AUTOSAR XML (schema 4-3-0)
package /CAN1/ISignalGroup
  31 x i signal group:
    CAN1_SG_ABM1: i-signal=[CAN1_AirBagFailCmd, CAN1_Checksum_ABM1, CAN1_CrashOutputSts, CAN1_DriverSeatBeltCmd, CAN1_LifeCount_ABM1, CAN1_PABSwitchCmd, CAN1_PsngrSeatBeltCmd, CAN1_RCenterSeatBeltCmd, CAN1_RDriverSeatBeltCmd, CAN1_RPsngrSeatBeltCmd, CAN1_TLHPsngrSeatBeltCmd, CAN1_TRHPsngrSeatBeltCmd], system-signal-group=CAN1_SG_ABM1
    CAN1_SG_EPAS1: i-signal=[CAN1_DriIntend, CAN1_EPAS1_Checksum, CAN1_EPAS1_LifeCount, CAN1_EPS_AOI_Control, CAN1_EPS_TOI_Fault], system-signal-group=CAN1_SG_EPAS1
    CAN1_SG_EPAS2: i-signal=[CAN1_SAS_Angle, CAN1_SAS_CAL, CAN1_SAS_CheckSum, CAN1_SAS_MsgCount, CAN1_SAS_Speed, CAN1_SAS_Speed_Valid, CAN1_SAS_V], system-signal-group=CAN1_SG_EPAS2
    CAN1_SG_EPB1: i-signal=[CAN1_DOA_Sta, CAN1_EPB1_CS, CAN1_EPB1_RC, CAN1_EPBCarWashMode, CAN1_EPBErrSta, CAN1_EPBExtApplyAvail, CAN1_EPBExtReleaseAvail, CAN1_EPBMsg, CAN1_EPBRLampSta, CAN1_EPBSta, CAN1_EPBStaL, CAN1_EPBStaR, CAN1_TakeOverReq], system-signal-group=CAN1_SG_EPB1
    CAN1_SG_ESC1: i-signal=[CAN1_ESC1_CS, CAN1_ESC1_RC, CAN1_Fr_PTCS_Active, CAN1_FrntAxlTrqReq_Drv, CAN1_RearAxlTrqReq_Drv, CAN1_Rr_PTCS_Active, CAN1_VehSpeed], system-signal-group=CAN1_SG_ESC1
    CAN1_SG_ESC2: i-signal=[CAN1_F_WhlSpeed_CRC_8, CAN1_F_WhlSpeed_Count, CAN1_LF_PulseCount, CAN1_LF_PulseCount_V, CAN1_LF_RawWhlSpeed, CAN1_LF_RawWhlSpeed_V, CAN1_LF_WhlRotDir, CAN1_RF_PulseCount, CAN1_RF_PulseCount_V, CAN1_RF_RawWhlSpeed, CAN1_RF_RawWhlSpeed_V, CAN1_RF_WhlRotDir], system-signal-group=CAN1_SG_ESC2
    CAN1_SG_ESC3: i-signal=[CAN1_LR_PulseCount, CAN1_LR_PulseCount_V, CAN1_LR_RawWhlSpeed, CAN1_LR_RawWhlSpeed_V, CAN1_LR_WhlRotDir, CAN1_RR_PulseCount, CAN1_RR_PulseCount_V, CAN1_RR_RawWhlSpeed, CAN1_RR_RawWhlSpeed_V, CAN1_RR_WhlRotDir, CAN1_R_WhlSpeed_CRC_8, CAN1_R_WhlSpeed_Count], system-signal-group=CAN1_SG_ESC3
    CAN1_SG_ESC4: i-signal=[CAN1_ABS_Active, CAN1_ABS_Failed, CAN1_ABS_WnlmpSta, CAN1_AVH_Active, CAN1_AVH_Failed, CAN1_Amber_WnlmpSta, CAN1_BTCS_Active, CAN1_EBD_Active, CAN1_EBD_Failed, CAN1_ESC_Active, CAN1_ESC_BeepReq, CAN1_ESC_Failed, CAN1_ESC_OFF_Status, CAN1_ESC_Off_lmpSta, CAN1_ESC_WnlmpSta, CAN1_ESS_Active, CAN1_GRADE, CAN1_HBB_Active, CAN1_HBB_Failed, CAN1_HDD_Active, CAN1_HDD_Failed, CAN1_HSA_Active, CAN1_HSA_Failed, CAN1_PBA_Active, CAN1_PBA_Failed, CAN1_Red_WnlmpSta, CAN1_SystemVoltage, CAN1_TCS_Active, CAN1_TCS_Failed], system-signal-group=CAN1_SG_ESC4
    CAN1_SG_ESC5: i-signal=[CAN1_BrkSw_Sta, CAN1_BrkSw_V, CAN1_ESC5_CRC8, CAN1_ESC5_RC, CAN1_LatAccel, CAN1_LatAccel_V, CAN1_LongAccel, CAN1_LongAccel_V, CAN1_MCPressure, CAN1_MCPressure_V, CAN1_YawRate, CAN1_YawRate_V], system-signal-group=CAN1_SG_ESC5
    CAN1_SG_ESC6: i-signal=[CAN1_ACCAvail, CAN1_AEBAvail, CAN1_ActBrkLamp_Sta, CAN1_BrkDiscTempSta, CAN1_DecErrSta, CAN1_ESC6_CS, CAN1_ESC6_RC, CAN1_ESC_ADAS_Sta, CAN1_ESC_APS_Sta, CAN1_ESC_Standstill, CAN1_Meter_Ind_VehSpeed], system-signal-group=CAN1_SG_ESC6
    CAN1_SG_ESC7: i-signal=[CAN1_BrkPedalPos, CAN1_BrkPedalPos_Sta, CAN1_ESC7_CS, CAN1_ESC7_RC, CAN1_Fr_RBC_Active, CAN1_FrntAxlTrqReq_Brk, CAN1_RDC_Active, CAN1_RearAxlTrqReq_Brk, CAN1_Rr_RBC_Active], system-signal-group=CAN1_SG_ESC7
    CAN1_SG_FCM2: i-signal=[CAN1_ACC_ComfortBandLower, CAN1_ACC_ComfortBandUpper, CAN1_ACC_JerkLowerLimit, CAN1_ACC_JerkUpperLimit, CAN1_ACC_RequiredAccel, CAN1_ACC_VehHoldReq, CAN1_ADAS_AEBReq, CAN1_ADAS_DBSReq, CAN1_ADAS_FaultSta, CAN1_AEB_VehHoldReq, CAN1_FCM2_Checksum, CAN1_FCM2_LifeCount], system-signal-group=CAN1_SG_FCM2
    CAN1_SG_FCM3: i-signal=[CAN1_ACC_ObjDist, CAN1_ACC_ObjRelSpd, CAN1_ADAS_ForceIdle, CAN1_ADAS_ShftPosnReq, CAN1_ADAS_ShftPosnReq_A, CAN1_ADAS_VehSpdLim, CAN1_FCM3_Checksum, CAN1_FCM3_LifeCount], system-signal-group=CAN1_SG_FCM3
    CAN1_SG_FCM4: i-signal=[CAN1_ACCSetSpeed, CAN1_ACCSetSpeed_Disp, CAN1_ACC_ObjDstLvl, CAN1_ACC_TakeoverReq, CAN1_ADAS_ACC_Sta, CAN1_ADAS_AEB_Sta, CAN1_ADAS_CAM_SpdLim, CAN1_ADAS_FCW_Sta, CAN1_ADAS_FltWrnReq, CAN1_ADAS_LDW_Sta, CAN1_ADAS_SLIF_SpdLim, CAN1_ADAS_WarningMsg, CAN1_FCM4_Checksum, CAN1_ForceLowBeam, CAN1_HazardWarningReq, CAN1_LeftTurnLightReq, CAN1_RightTurnLightReq, CAN1_Target_Type, CAN1_TimeGapLevel], system-signal-group=CAN1_SG_FCM4
    CAN1_SG_FD_APS1: i-signal=[CAN1_APS_Angle_Target, CAN1_APS_Rq_EPAS_Ctrl, CAN1_APS_Sta_System, CAN1_APS_V_Rq_EPAS_Ctrl], system-signal-group=CAN1_SG_FD_APS1
    CAN1_SG_FD_APS2: i-signal=[CAN1_APS_D_FLL, CAN1_APS_D_FLR, CAN1_APS_D_RLL, CAN1_APS_D_RLR, CAN1_APS_ExitCondition, CAN1_APS_HW_Ver, CAN1_APS_Progress_PCT, CAN1_APS_RQ_Display, CAN1_APS_SW_Ver, CAN1_PAS_A_FCL, CAN1_PAS_A_FCR, CAN1_PAS_A_FML, CAN1_PAS_A_FMR, CAN1_PAS_A_RCL, CAN1_PAS_A_RCR, CAN1_PAS_A_RML, CAN1_PAS_A_RMR, CAN1_PAS_Chime, CAN1_PAS_D_FCL, CAN1_PAS_D_FCR, CAN1_PAS_D_FML, CAN1_PAS_D_FMR, CAN1_PAS_D_RCL, CAN1_PAS_D_RCR, CAN1_PAS_D_RML, CAN1_PAS_D_RMR, CAN1_PAS_Mod_Operation, CAN1_PAS_SNSR_Layout, CAN1_PAS_Sta_F_Sys, CAN1_USS_Sta_FCL, CAN1_USS_Sta_FCR, CAN1_USS_Sta_FLL, CAN1_USS_Sta_FLR, CAN1_USS_Sta_FML, CAN1_USS_Sta_FMR, CAN1_USS_Sta_RCL, CAN1_USS_Sta_RCR, CAN1_USS_Sta_RLL, CAN1_USS_Sta_RLR, CAN1_USS_Sta_RML, CAN1_USS_Sta_RMR], system-signal-group=CAN1_SG_FD_APS2
    CAN1_SG_FD_APS3: i-signal=[CAN1_APS3_LifeCount, CAN1_APS3_checksum, CAN1_APSOpenPTG, CAN1_APS_DecReq, CAN1_APS_DecReq_A, CAN1_APS_Req, CAN1_CAAS_Sta, CAN1_SPTGDet, CAN1_SPTG_Sta], system-signal-group=CAN1_SG_FD_APS3
    CAN1_SG_FD_BCM1: i-signal=[CAN1_AllDoorSW, CAN1_AntiTheftSeatFold, CAN1_AntitheftSta, CAN1_BCM_Buzzer_Req, CAN1_BCM_DoorLock_Sta, CAN1_BrakeLamp, CAN1_CTDCtrl, CAN1_CTDLockSW, CAN1_CTDUnlockSW, CAN1_CrashDetd, CAN1_Dimmer, CAN1_DimmerEN, CAN1_DoorLockIND, CAN1_DrDoorSW, CAN1_Fr_ChargingDoorCtrl, CAN1_Fr_FogLamp, CAN1_Fr_Wiper_H, CAN1_Fr_Wiper_L, CAN1_H_Beam, CAN1_HazardSW, CAN1_HoodSW, CAN1_HornCtrl, CAN1_LBSD, CAN1_LDRL, CAN1_LTurnLP, CAN1_L_APM_WdwEnable, CAN1_L_Beam, CAN1_LockSetting, CAN1_MirrorCtrl, CAN1_MirrorDefog, CAN1_PosLamp, CAN1_PsDoorSW, CAN1_RBSD, CAN1_RDRL, CAN1_RLDoorSW, CAN1_RRDoorSW, CAN1_RTurnLP, CAN1_ReverseLamp, CAN1_RoomLampH, CAN1_RoomLampL, CAN1_Rr_ChargingDoorCtrl, CAN1_Rr_Defog, CAN1_Rr_FogLamp, CAN1_Rr_Wiper, CAN1_TailgateHDSW, CAN1_TailgateRemote, CAN1_Tailgate_SW, CAN1_TrunkRel, CAN1_WasherCtrl, CAN1_WiperFixMode], system-signal-group=CAN1_SG_FD_BCM1
    CAN1_SG_FD_THCM1: i-signal=[CAN1_BatteryMode, CAN1_CCU_ACLampSts, CAN1_CCU_ACMaxLampSts, CAN1_CCU_AutoLampSts, CAN1_CCU_AutoMidLampSts, CAN1_CCU_Dispaly_Request, CAN1_CCU_EcoSts, CAN1_CCU_FrtOnOffLampSts, CAN1_CCU_HEATMaxLampSts, CAN1_CCU_RrOnOffLampSts, CAN1_CCU_SyncLampSts, CAN1_CabinMode, CAN1_EDriveMode, CAN1_FD_AGS_Cmd, CAN1_FD_RecyAuto_Cmd, CAN1_Fr_Coolantflow, CAN1_Fr_Coolanttemp, CAN1_HPThermalRecoveryReq, CAN1_Rr_Coolantflow, CAN1_Rr_Coolanttemp, CAN1_sigAirIntenZon1St, CAN1_sigAirIntenZon3St, CAN1_sigAmbAirT, CAN1_sigCbnAirT, CAN1_sigCbnPTCPwrAct, CAN1_sigCbnSolarLeft, CAN1_sigCbnSolarRight, CAN1_sigClmtCmprPwrAct, CAN1_sigClntTHvBattOut, CAN1_sigDfrstSt, CAN1_sigHvacSt, CAN1_sigRecircSt, CAN1_sigSetTempZon1St, CAN1_sigSetTempZon2St, CAN1_sigSetTempZon3St, CAN1_sigWindDirZon1St, CAN1_sigWindDirZon3St], system-signal-group=CAN1_SG_FD_THCM1
    CAN1_SG_FD_VCU1: i-signal=[CAN1_CC_Crl_Sta, CAN1_HVPwrSta, CAN1_LVPwrSta, CAN1_MSA_Crl_Sta, CAN1_P_Button_Sta, CAN1_PrkReq, CAN1_PrkReqValid, CAN1_PwrSta, CAN1_ShiftGearPosn, CAN1_XWDMode], system-signal-group=CAN1_SG_FD_VCU1
    CAN1_SG_FD_VCU2: i-signal=[CAN1_ACC_CtrlAvail, CAN1_AccPedal_Override, CAN1_ActAPSPosn, CAN1_CS_VCU2_CAN1, CAN1_DriverTq, CAN1_Fr_DriverTq, CAN1_RC_VCU2_CAN1, CAN1_Rr_DriverTq, CAN1_VehActPwr], system-signal-group=CAN1_SG_FD_VCU2
    CAN1_SG_FD_VCU3: i-signal=[CAN1_CS_VCU3_CAN1, CAN1_EquivAccPedalSWSta, CAN1_Fr_EDUAvailBrkRgnTq, CAN1_Fr_EDUAvailBrkRgnTqValid, CAN1_Fr_EDURealARgnTq, CAN1_Fr_EDURealDrvOrBRgnTq, CAN1_Fr_EDUSpd, CAN1_Fr_EDUSpdValid, CAN1_Fr_RgnDecrSta, CAN1_Fr_RgnPermSta, CAN1_PTCS_PermSta, CAN1_RC_VCU3_CAN1, CAN1_RgnAbnorSta, CAN1_Rr_EDUAvailBrkRgnTq, CAN1_Rr_EDUAvailBrkRgnTqValid, CAN1_Rr_EDURealARgnTq, CAN1_Rr_EDURealDrvOrBRgnTq, CAN1_Rr_EDUSpd, CAN1_Rr_EDUSpdValid, CAN1_Rr_RgnDecrSta, CAN1_Rr_RgnPermSta], system-signal-group=CAN1_SG_FD_VCU3
    CAN1_SG_FD_VCU4: i-signal=[CAN1_Eng_AGSCloseSta, CAN1_Eng_ActvDmpDisabSta, CAN1_Eng_CoastDwSta, CAN1_Eng_PwrLockSta, CAN1_VehMalfunLevel], system-signal-group=CAN1_SG_FD_VCU4
    CAN1_SG_SRR1: i-signal=[CAN1_SRR1_Chksum, CAN1_SRR1_LifeCount, CAN1_SRR_BSD_Mute, CAN1_SRR_BSD_SoundL, CAN1_SRR_BSD_SoundR, CAN1_SRR_BSD_Sta, CAN1_SRR_BSD_WarnL, CAN1_SRR_BSD_WarnR, CAN1_SRR_FltWrnReq, CAN1_SRR_ODA_Mute, CAN1_SRR_ODA_SoundL, CAN1_SRR_ODA_SoundR, CAN1_SRR_ODA_Sta, CAN1_SRR_ODA_WarnL, CAN1_SRR_ODA_WarnR, CAN1_SRR_RCTA_Sta, CAN1_SRR_RCTA_WarnL, CAN1_SRR_RCTA_WarnR], system-signal-group=CAN1_SG_SRR1
    CAN1_SG_XNMm_ABM: i-signal=[CAN1_NM_ABM_Active_WU, CAN1_NM_ABM_CSB, CAN1_NM_ABM_ERROR_State, CAN1_NM_ABM_Node_ID, CAN1_NM_ABM_PNI, CAN1_NM_ABM_Rpt_Msg_Req], system-signal-group=CAN1_SG_XNMm_ABM
    CAN1_SG_XNMm_EPAS: i-signal=[CAN1_NM_EPAS_Active_WU, CAN1_NM_EPAS_CSB, CAN1_NM_EPAS_ERROR_State, CAN1_NM_EPAS_Node_ID, CAN1_NM_EPAS_PNI, CAN1_NM_EPAS_Rpt_Msg_Req], system-signal-group=CAN1_SG_XNMm_EPAS
    CAN1_SG_XNMm_ESC: i-signal=[CAN1_NM_ESC_Active_WU, CAN1_NM_ESC_CSB, CAN1_NM_ESC_ERROR_State, CAN1_NM_ESC_Node_ID, CAN1_NM_ESC_PNI, CAN1_NM_ESC_Rpt_Msg_Req], system-signal-group=CAN1_SG_XNMm_ESC
    CAN1_SG_XNMm_FCM: i-signal=[CAN1_NM_FCM_Active_WU, CAN1_NM_FCM_CSB, CAN1_NM_FCM_ERROR_State, CAN1_NM_FCM_Node_ID, CAN1_NM_FCM_PNI, CAN1_NM_FCM_Rpt_Msg_Req], system-signal-group=CAN1_SG_XNMm_FCM
    CAN1_SG_XNMm_FUSION: i-signal=[CAN1_NM_FUSION_Active_WU, CAN1_NM_FUSION_CSB, CAN1_NM_FUSION_ERROR_State, CAN1_NM_FUSION_Node_ID, CAN1_NM_FUSION_PNI, CAN1_NM_FUSION_Rpt_Msg_Req], system-signal-group=CAN1_SG_XNMm_FUSION
    CAN1_SG_XNMm_SRR_M: i-signal=[CAN1_NM_SRR_M_Active_WU, CAN1_NM_SRR_M_CSB, CAN1_NM_SRR_M_ERROR_State, CAN1_NM_SRR_M_Node_ID, CAN1_NM_SRR_M_PNI, CAN1_NM_SRR_M_Rpt_Msg_Req], system-signal-group=CAN1_SG_XNMm_SRR_M
    CAN1_SG_XNMm_eBST: i-signal=[CAN1_NM_eBST_Active_WU, CAN1_NM_eBST_CSB, CAN1_NM_eBST_ERROR_State, CAN1_NM_eBST_Node_ID, CAN1_NM_eBST_PNI, CAN1_NM_eBST_Rpt_Msg_Req], system-signal-group=CAN1_SG_XNMm_eBST
package /CAN1/Cluster
  can cluster CAN1: baudrate=500, can-fd-baudrate=2000
    can physical channel CAN1: comm-connectors=ConnCAN1
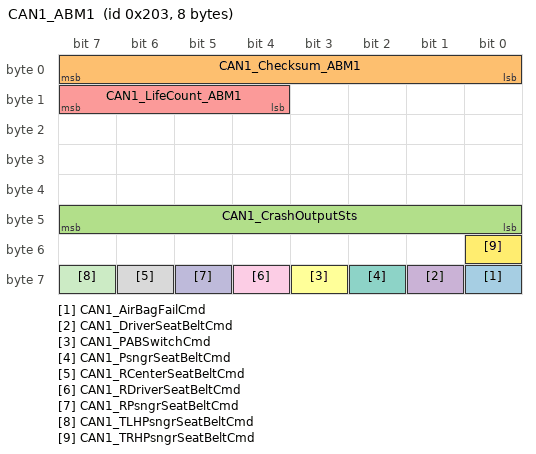
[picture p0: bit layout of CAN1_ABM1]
      frame CAN1_ABM1: id 0x203, frame-length=8, can-addressing-mode=STANDARD, can-fd-frame-support=true, can-frame-rx-behavior=CAN-FD, can-frame-tx-behavior=CAN-FD
        pdu CAN1_ABM1: length=8, minimum-delay=0.0, transmission-mode-true-timing={cyclic-timing=time-period=0.5, event-controlled-timing={number-of-repetitions=0, repetition-period=0.05}}, unused-bit-pattern=0
          mapping CAN1_SG_ABM1: i-signal-group=CAN1_SG_ABM1, start-position=0, transfer-property=TRIGGERED-ON-CHANGE
          signal CAN1_AirBagFailCmd: start 56, 1 bit, big-endian, i-signal-type=PRIMITIVE, init-value=constant-reference=Init_CAN1_AirBagFailCmd, base-type=uint8, implementation-data-type=uint8, transfer-property=TRIGGERED-ON-CHANGE
          signal CAN1_Checksum_ABM1: start 7, 8 bit, big-endian, i-signal-type=PRIMITIVE, init-value=constant-reference=Init_CAN1_Checksum_ABM1, base-type=uint8, implementation-data-type=uint8, transfer-property=TRIGGERED-ON-CHANGE
          signal CAN1_CrashOutputSts: start 47, 8 bit, big-endian, i-signal-type=PRIMITIVE, init-value=constant-reference=Init_CAN1_CrashOutputSts, base-type=uint8, implementation-data-type=uint8, transfer-property=TRIGGERED-ON-CHANGE
          signal CAN1_DriverSeatBeltCmd: start 57, 1 bit, big-endian, i-signal-type=PRIMITIVE, init-value=constant-reference=Init_CAN1_DriverSeatBeltCmd, base-type=uint8, implementation-data-type=uint8, transfer-property=TRIGGERED-ON-CHANGE
          signal CAN1_LifeCount_ABM1: start 15, 4 bit, big-endian, i-signal-type=PRIMITIVE, init-value=constant-reference=Init_CAN1_LifeCount_ABM1, base-type=uint8, implementation-data-type=uint8, transfer-property=TRIGGERED-ON-CHANGE
          signal CAN1_PABSwitchCmd: start 59, 1 bit, big-endian, i-signal-type=PRIMITIVE, init-value=constant-reference=Init_CAN1_PABSwitchCmd, base-type=uint8, implementation-data-type=uint8, transfer-property=TRIGGERED-ON-CHANGE
          signal CAN1_PsngrSeatBeltCmd: start 58, 1 bit, big-endian, i-signal-type=PRIMITIVE, init-value=constant-reference=Init_CAN1_PsngrSeatBeltCmd, base-type=uint8, implementation-data-type=uint8, transfer-property=TRIGGERED-ON-CHANGE
          signal CAN1_RCenterSeatBeltCmd: start 62, 1 bit, big-endian, i-signal-type=PRIMITIVE, init-value=constant-reference=Init_CAN1_RCenterSeatBeltCmd, base-type=uint8, implementation-data-type=uint8, transfer-property=TRIGGERED-ON-CHANGE
          signal CAN1_RDriverSeatBeltCmd: start 60, 1 bit, big-endian, i-signal-type=PRIMITIVE, init-value=constant-reference=Init_CAN1_RDriverSeatBeltCmd, base-type=uint8, implementation-data-type=uint8, transfer-property=TRIGGERED-ON-CHANGE
          signal CAN1_RPsngrSeatBeltCmd: start 61, 1 bit, big-endian, i-signal-type=PRIMITIVE, init-value=constant-reference=Init_CAN1_RPsngrSeatBeltCmd, base-type=uint8, implementation-data-type=uint8, transfer-property=TRIGGERED-ON-CHANGE
          signal CAN1_TLHPsngrSeatBeltCmd: start 63, 1 bit, big-endian, i-signal-type=PRIMITIVE, init-value=constant-reference=Init_CAN1_TLHPsngrSeatBeltCmd, base-type=uint8, implementation-data-type=uint8, transfer-property=TRIGGERED-ON-CHANGE
          signal CAN1_TRHPsngrSeatBeltCmd: start 48, 1 bit, big-endian, i-signal-type=PRIMITIVE, init-value=constant-reference=Init_CAN1_TRHPsngrSeatBeltCmd, base-type=uint8, implementation-data-type=uint8, transfer-property=TRIGGERED-ON-CHANGE
      frame CAN1_DiagFuncReqFT: id 0x7D0, frame-length=8, can-addressing-mode=STANDARD, can-fd-frame-support=false, can-frame-rx-behavior=CAN-20, can-frame-tx-behavior=CAN-20
        n pdu CAN1_DiagFuncReqFT: length=8
      frame CAN1_DiagPhysReqToABM: id 0x6B1, frame-length=8, can-addressing-mode=STANDARD, can-fd-frame-support=true, can-frame-rx-behavior=CAN-FD, can-frame-tx-behavior=CAN-FD
        n pdu CAN1_DiagPhysReqToABM: length=8
      frame CAN1_DiagPhysReqToEPAS: id 0x6A1, frame-length=8, can-addressing-mode=STANDARD, can-fd-frame-support=true, can-frame-rx-behavior=CAN-FD, can-frame-tx-behavior=CAN-FD
        n pdu CAN1_DiagPhysReqToEPAS: length=8
      frame CAN1_DiagPhysReqToESC: id 0x681, frame-length=8, can-addressing-mode=STANDARD, can-fd-frame-support=false, can-frame-rx-behavior=CAN-20, can-frame-tx-behavior=CAN-20
        n pdu CAN1_DiagPhysReqToESC: length=8
      frame CAN1_DiagPhysReqToFCM: id 0x690, frame-length=8, can-addressing-mode=STANDARD, can-fd-frame-support=true, can-frame-rx-behavior=CAN-FD, can-frame-tx-behavior=CAN-FD
        n pdu CAN1_DiagPhysReqToFCM: length=8
      frame CAN1_DiagPhysReqToMRR: id 0x695, frame-length=8, can-addressing-mode=STANDARD, can-fd-frame-support=false, can-frame-rx-behavior=CAN-20, can-frame-tx-behavior=CAN-20
        n pdu CAN1_DiagPhysReqToMRR: length=8
      frame CAN1_DiagPhysReqToSRR_M: id 0x692, frame-length=8, can-addressing-mode=STANDARD, can-fd-frame-support=true, can-frame-rx-behavior=CAN-FD, can-frame-tx-behavior=CAN-FD
        n pdu CAN1_DiagPhysReqToSRR_M: length=8
      frame CAN1_DiagPhysReqToeBST: id 0x691, frame-length=8, can-addressing-mode=STANDARD, can-fd-frame-support=false, can-frame-rx-behavior=CAN-20, can-frame-tx-behavior=CAN-20
        n pdu CAN1_DiagPhysReqToeBST: length=8
      frame CAN1_DiagRespFromABM: id 0x631, frame-length=8, can-addressing-mode=STANDARD, can-fd-frame-support=true, can-frame-rx-behavior=CAN-FD, can-frame-tx-behavior=CAN-FD
        n pdu CAN1_DiagRespFromABM: length=8
      frame CAN1_DiagRespFromEPAS: id 0x621, frame-length=8, can-addressing-mode=STANDARD, can-fd-frame-support=true, can-frame-rx-behavior=CAN-FD, can-frame-tx-behavior=CAN-FD
        n pdu CAN1_DiagRespFromEPAS: length=8
      frame CAN1_DiagRespFromESC: id 0x601, frame-length=8, can-addressing-mode=STANDARD, can-fd-frame-support=false, can-frame-rx-behavior=CAN-20, can-frame-tx-behavior=CAN-20
        n pdu CAN1_DiagRespFromESC: length=8
      frame CAN1_DiagRespFromFCM: id 0x610, frame-length=8, can-addressing-mode=STANDARD, can-fd-frame-support=true, can-frame-rx-behavior=CAN-FD, can-frame-tx-behavior=CAN-FD
        n pdu CAN1_DiagRespFromFCM: length=8
      frame CAN1_DiagRespFromMRR: id 0x615, frame-length=8, can-addressing-mode=STANDARD, can-fd-frame-support=false, can-frame-rx-behavior=CAN-20, can-frame-tx-behavior=CAN-20
        n pdu CAN1_DiagRespFromMRR: length=8
      frame CAN1_DiagRespFromSRR_M: id 0x612, frame-length=8, can-addressing-mode=STANDARD, can-fd-frame-support=true, can-frame-rx-behavior=CAN-FD, can-frame-tx-behavior=CAN-FD
        n pdu CAN1_DiagRespFromSRR_M: length=8
      frame CAN1_DiagRespFromeBST: id 0x611, frame-length=8, can-addressing-mode=STANDARD, can-fd-frame-support=false, can-frame-rx-behavior=CAN-20, can-frame-tx-behavior=CAN-20
        n pdu CAN1_DiagRespFromeBST: length=8
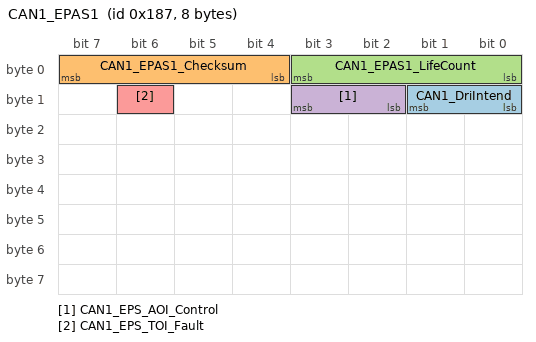
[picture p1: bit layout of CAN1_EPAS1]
      frame CAN1_EPAS1: id 0x187, frame-length=8, can-addressing-mode=STANDARD, can-fd-frame-support=true, can-frame-rx-behavior=CAN-FD, can-frame-tx-behavior=CAN-FD
        pdu CAN1_EPAS1: length=8, minimum-delay=0.0, transmission-mode-true-timing=cyclic-timing=time-period=0.02, unused-bit-pattern=0
          mapping CAN1_SG_EPAS1: i-signal-group=CAN1_SG_EPAS1, start-position=0, transfer-property=PENDING
          signal CAN1_DriIntend: start 9, 2 bit, big-endian, i-signal-type=PRIMITIVE, init-value=constant-reference=Init_CAN1_DriIntend, base-type=uint8, implementation-data-type=uint8, transfer-property=PENDING
          signal CAN1_EPAS1_Checksum: start 7, 4 bit, big-endian, i-signal-type=PRIMITIVE, init-value=constant-reference=Init_CAN1_EPAS1_Checksum, base-type=uint8, implementation-data-type=uint8, transfer-property=PENDING
          signal CAN1_EPAS1_LifeCount: start 3, 4 bit, big-endian, i-signal-type=PRIMITIVE, init-value=constant-reference=Init_CAN1_EPAS1_LifeCount, base-type=uint8, implementation-data-type=uint8, transfer-property=PENDING
          signal CAN1_EPS_AOI_Control: start 11, 2 bit, big-endian, i-signal-type=PRIMITIVE, init-value=constant-reference=Init_CAN1_EPS_AOI_Control, base-type=uint8, implementation-data-type=uint8, transfer-property=PENDING
          signal CAN1_EPS_TOI_Fault: start 14, 1 bit, big-endian, i-signal-type=PRIMITIVE, init-value=constant-reference=Init_CAN1_EPS_TOI_Fault, base-type=uint8, implementation-data-type=uint8, transfer-property=PENDING
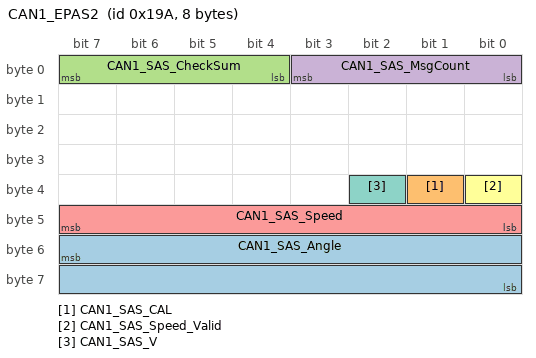
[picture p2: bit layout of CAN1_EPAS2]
      frame CAN1_EPAS2: id 0x19A, frame-length=8, can-addressing-mode=STANDARD, can-fd-frame-support=true, can-frame-rx-behavior=CAN-FD, can-frame-tx-behavior=CAN-FD
        pdu CAN1_EPAS2: length=8, minimum-delay=0.0, transmission-mode-true-timing=cyclic-timing=time-period=0.01, unused-bit-pattern=0
          mapping CAN1_SG_EPAS2: i-signal-group=CAN1_SG_EPAS2, start-position=0, transfer-property=PENDING
          signal CAN1_SAS_Angle: start 55, 16 bit, big-endian, i-signal-type=PRIMITIVE, init-value=constant-reference=Init_CAN1_SAS_Angle, base-type=uint16, implementation-data-type=uint16, transfer-property=PENDING
          signal CAN1_SAS_CAL: start 33, 1 bit, big-endian, i-signal-type=PRIMITIVE, init-value=constant-reference=Init_CAN1_SAS_CAL, base-type=uint8, implementation-data-type=uint8, transfer-property=PENDING
          signal CAN1_SAS_CheckSum: start 7, 4 bit, big-endian, i-signal-type=PRIMITIVE, init-value=constant-reference=Init_CAN1_SAS_CheckSum, base-type=uint8, implementation-data-type=uint8, transfer-property=PENDING
          signal CAN1_SAS_MsgCount: start 3, 4 bit, big-endian, i-signal-type=PRIMITIVE, init-value=constant-reference=Init_CAN1_SAS_MsgCount, base-type=uint8, implementation-data-type=uint8, transfer-property=PENDING
          signal CAN1_SAS_Speed: start 47, 8 bit, big-endian, i-signal-type=PRIMITIVE, init-value=constant-reference=Init_CAN1_SAS_Speed, base-type=uint8, implementation-data-type=uint8, transfer-property=PENDING
          signal CAN1_SAS_Speed_Valid: start 32, 1 bit, big-endian, i-signal-type=PRIMITIVE, init-value=constant-reference=Init_CAN1_SAS_Speed_Valid, base-type=uint8, implementation-data-type=uint8, transfer-property=PENDING
          signal CAN1_SAS_V: start 34, 1 bit, big-endian, i-signal-type=PRIMITIVE, init-value=constant-reference=Init_CAN1_SAS_V, base-type=uint8, implementation-data-type=uint8, transfer-property=PENDING
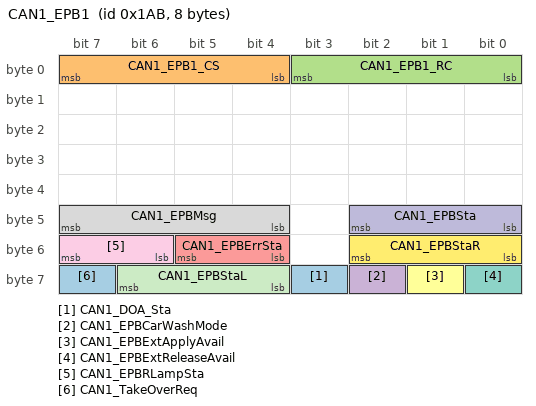
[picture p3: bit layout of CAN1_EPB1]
      frame CAN1_EPB1: id 0x1AB, frame-length=8, can-addressing-mode=STANDARD, can-fd-frame-support=true, can-frame-rx-behavior=CAN-FD, can-frame-tx-behavior=CAN-FD
        pdu CAN1_EPB1: length=8, minimum-delay=0.0, transmission-mode-true-timing=cyclic-timing=time-period=0.04, unused-bit-pattern=0
          mapping CAN1_SG_EPB1: i-signal-group=CAN1_SG_EPB1, start-position=0, transfer-property=PENDING
          signal CAN1_DOA_Sta: start 59, 1 bit, big-endian, i-signal-type=PRIMITIVE, init-value=constant-reference=Init_CAN1_DOA_Sta, base-type=uint8, implementation-data-type=uint8, transfer-property=PENDING
          signal CAN1_EPB1_CS: start 7, 4 bit, big-endian, i-signal-type=PRIMITIVE, init-value=constant-reference=Init_CAN1_EPB1_CS, base-type=uint8, implementation-data-type=uint8, transfer-property=PENDING
          signal CAN1_EPB1_RC: start 3, 4 bit, big-endian, i-signal-type=PRIMITIVE, init-value=constant-reference=Init_CAN1_EPB1_RC, base-type=uint8, implementation-data-type=uint8, transfer-property=PENDING
          signal CAN1_EPBCarWashMode: start 58, 1 bit, big-endian, i-signal-type=PRIMITIVE, init-value=constant-reference=Init_CAN1_EPBCarWashMode, base-type=uint8, implementation-data-type=uint8, transfer-property=PENDING
          signal CAN1_EPBErrSta: start 53, 2 bit, big-endian, i-signal-type=PRIMITIVE, init-value=constant-reference=Init_CAN1_EPBErrSta, base-type=uint8, implementation-data-type=uint8, transfer-property=PENDING
          signal CAN1_EPBExtApplyAvail: start 57, 1 bit, big-endian, i-signal-type=PRIMITIVE, init-value=constant-reference=Init_CAN1_EPBExtApplyAvail, base-type=uint8, implementation-data-type=uint8, transfer-property=PENDING
          signal CAN1_EPBExtReleaseAvail: start 56, 1 bit, big-endian, i-signal-type=PRIMITIVE, init-value=constant-reference=Init_CAN1_EPBExtReleaseAvail, base-type=uint8, implementation-data-type=uint8, transfer-property=PENDING
          signal CAN1_EPBMsg: start 47, 4 bit, big-endian, i-signal-type=PRIMITIVE, init-value=constant-reference=Init_CAN1_EPBMsg, base-type=uint8, implementation-data-type=uint8, transfer-property=PENDING
          signal CAN1_EPBRLampSta: start 55, 2 bit, big-endian, i-signal-type=PRIMITIVE, init-value=constant-reference=Init_CAN1_EPBRLampSta, base-type=uint8, implementation-data-type=uint8, transfer-property=PENDING
          signal CAN1_EPBSta: start 42, 3 bit, big-endian, i-signal-type=PRIMITIVE, init-value=constant-reference=Init_CAN1_EPBSta, base-type=uint8, implementation-data-type=uint8, transfer-property=PENDING
          signal CAN1_EPBStaL: start 62, 3 bit, big-endian, i-signal-type=PRIMITIVE, init-value=constant-reference=Init_CAN1_EPBStaL, base-type=uint8, implementation-data-type=uint8, transfer-property=PENDING
          signal CAN1_EPBStaR: start 50, 3 bit, big-endian, i-signal-type=PRIMITIVE, init-value=constant-reference=Init_CAN1_EPBStaR, base-type=uint8, implementation-data-type=uint8, transfer-property=PENDING
          signal CAN1_TakeOverReq: start 63, 1 bit, big-endian, i-signal-type=PRIMITIVE, init-value=constant-reference=Init_CAN1_TakeOverReq, base-type=uint8, implementation-data-type=uint8, transfer-property=PENDING
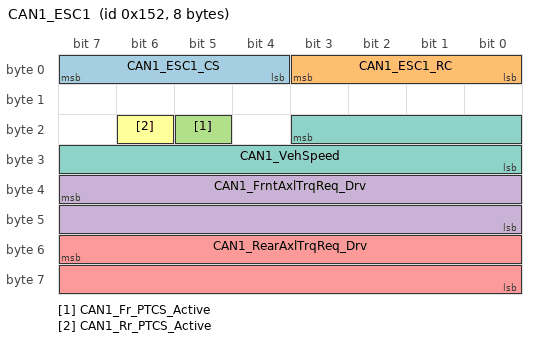
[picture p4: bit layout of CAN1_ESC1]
      frame CAN1_ESC1: id 0x152, frame-length=8, can-addressing-mode=STANDARD, can-fd-frame-support=true, can-frame-rx-behavior=CAN-FD, can-frame-tx-behavior=CAN-FD
        pdu CAN1_ESC1: length=8, minimum-delay=0.0, transmission-mode-true-timing=cyclic-timing=time-period=0.01, unused-bit-pattern=0
          mapping CAN1_SG_ESC1: i-signal-group=CAN1_SG_ESC1, start-position=0, transfer-property=PENDING
          signal CAN1_ESC1_CS: start 7, 4 bit, big-endian, i-signal-type=PRIMITIVE, init-value=constant-reference=Init_CAN1_ESC1_CS, base-type=uint8, implementation-data-type=uint8, transfer-property=PENDING
          signal CAN1_ESC1_RC: start 3, 4 bit, big-endian, i-signal-type=PRIMITIVE, init-value=constant-reference=Init_CAN1_ESC1_RC, base-type=uint8, implementation-data-type=uint8, transfer-property=PENDING
          signal CAN1_Fr_PTCS_Active: start 21, 1 bit, big-endian, i-signal-type=PRIMITIVE, init-value=constant-reference=Init_CAN1_Fr_PTCS_Active, base-type=uint8, implementation-data-type=uint8, transfer-property=PENDING
          signal CAN1_FrntAxlTrqReq_Drv: start 39, 16 bit, big-endian, i-signal-type=PRIMITIVE, init-value=constant-reference=Init_CAN1_FrntAxlTrqReq_Drv, base-type=uint16, implementation-data-type=uint16, transfer-property=PENDING
          signal CAN1_RearAxlTrqReq_Drv: start 55, 16 bit, big-endian, i-signal-type=PRIMITIVE, init-value=constant-reference=Init_CAN1_RearAxlTrqReq_Drv, base-type=uint16, implementation-data-type=uint16, transfer-property=PENDING
          signal CAN1_Rr_PTCS_Active: start 22, 1 bit, big-endian, i-signal-type=PRIMITIVE, init-value=constant-reference=Init_CAN1_Rr_PTCS_Active, base-type=uint8, implementation-data-type=uint8, transfer-property=PENDING
          signal CAN1_VehSpeed: start 19, 12 bit, big-endian, i-signal-type=PRIMITIVE, init-value=constant-reference=Init_CAN1_VehSpeed, base-type=uint16, implementation-data-type=uint16, transfer-property=PENDING
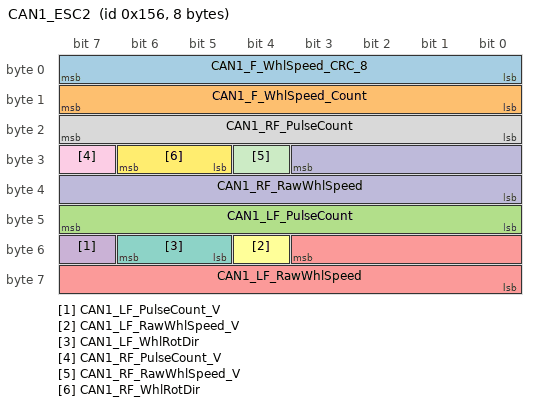
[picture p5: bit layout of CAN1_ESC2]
      frame CAN1_ESC2: id 0x156, frame-length=8, can-addressing-mode=STANDARD, can-fd-frame-support=true, can-frame-rx-behavior=CAN-FD, can-frame-tx-behavior=CAN-FD
        pdu CAN1_ESC2: length=8, minimum-delay=0.0, transmission-mode-true-timing=cyclic-timing=time-period=0.01, unused-bit-pattern=0
          mapping CAN1_SG_ESC2: i-signal-group=CAN1_SG_ESC2, start-position=0, transfer-property=PENDING
          signal CAN1_F_WhlSpeed_CRC_8: start 7, 8 bit, big-endian, i-signal-type=PRIMITIVE, init-value=constant-reference=Init_CAN1_F_WhlSpeed_CRC_8, base-type=uint8, implementation-data-type=uint8, transfer-property=PENDING
          signal CAN1_F_WhlSpeed_Count: start 15, 8 bit, big-endian, i-signal-type=PRIMITIVE, init-value=constant-reference=Init_CAN1_F_WhlSpeed_Count, base-type=uint8, implementation-data-type=uint8, transfer-property=PENDING
          signal CAN1_LF_PulseCount: start 47, 8 bit, big-endian, i-signal-type=PRIMITIVE, init-value=constant-reference=Init_CAN1_LF_PulseCount, base-type=uint8, implementation-data-type=uint8, transfer-property=PENDING
          signal CAN1_LF_PulseCount_V: start 55, 1 bit, big-endian, i-signal-type=PRIMITIVE, init-value=constant-reference=Init_CAN1_LF_PulseCount_V, base-type=uint8, implementation-data-type=uint8, transfer-property=PENDING
          signal CAN1_LF_RawWhlSpeed: start 51, 12 bit, big-endian, i-signal-type=PRIMITIVE, init-value=constant-reference=Init_CAN1_LF_RawWhlSpeed, base-type=uint16, implementation-data-type=uint16, transfer-property=PENDING
          signal CAN1_LF_RawWhlSpeed_V: start 52, 1 bit, big-endian, i-signal-type=PRIMITIVE, init-value=constant-reference=Init_CAN1_LF_RawWhlSpeed_V, base-type=uint8, implementation-data-type=uint8, transfer-property=PENDING
          signal CAN1_LF_WhlRotDir: start 54, 2 bit, big-endian, i-signal-type=PRIMITIVE, init-value=constant-reference=Init_CAN1_LF_WhlRotDir, base-type=uint8, implementation-data-type=uint8, transfer-property=PENDING
          signal CAN1_RF_PulseCount: start 23, 8 bit, big-endian, i-signal-type=PRIMITIVE, init-value=constant-reference=Init_CAN1_RF_PulseCount, base-type=uint8, implementation-data-type=uint8, transfer-property=PENDING
          signal CAN1_RF_PulseCount_V: start 31, 1 bit, big-endian, i-signal-type=PRIMITIVE, init-value=constant-reference=Init_CAN1_RF_PulseCount_V, base-type=uint8, implementation-data-type=uint8, transfer-property=PENDING
          signal CAN1_RF_RawWhlSpeed: start 27, 12 bit, big-endian, i-signal-type=PRIMITIVE, init-value=constant-reference=Init_CAN1_RF_RawWhlSpeed, base-type=uint16, implementation-data-type=uint16, transfer-property=PENDING
          signal CAN1_RF_RawWhlSpeed_V: start 28, 1 bit, big-endian, i-signal-type=PRIMITIVE, init-value=constant-reference=Init_CAN1_RF_RawWhlSpeed_V, base-type=uint8, implementation-data-type=uint8, transfer-property=PENDING
          signal CAN1_RF_WhlRotDir: start 30, 2 bit, big-endian, i-signal-type=PRIMITIVE, init-value=constant-reference=Init_CAN1_RF_WhlRotDir, base-type=uint8, implementation-data-type=uint8, transfer-property=PENDING
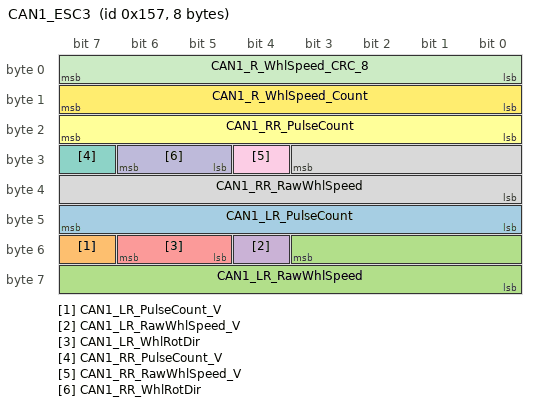
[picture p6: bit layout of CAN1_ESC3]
      frame CAN1_ESC3: id 0x157, frame-length=8, can-addressing-mode=STANDARD, can-fd-frame-support=true, can-frame-rx-behavior=CAN-FD, can-frame-tx-behavior=CAN-FD
        pdu CAN1_ESC3: length=8, minimum-delay=0.0, transmission-mode-true-timing=cyclic-timing=time-period=0.01, unused-bit-pattern=0
          mapping CAN1_SG_ESC3: i-signal-group=CAN1_SG_ESC3, start-position=0, transfer-property=PENDING
          signal CAN1_LR_PulseCount: start 47, 8 bit, big-endian, i-signal-type=PRIMITIVE, init-value=constant-reference=Init_CAN1_LR_PulseCount, base-type=uint8, implementation-data-type=uint8, transfer-property=PENDING
          signal CAN1_LR_PulseCount_V: start 55, 1 bit, big-endian, i-signal-type=PRIMITIVE, init-value=constant-reference=Init_CAN1_LR_PulseCount_V, base-type=uint8, implementation-data-type=uint8, transfer-property=PENDING
          signal CAN1_LR_RawWhlSpeed: start 51, 12 bit, big-endian, i-signal-type=PRIMITIVE, init-value=constant-reference=Init_CAN1_LR_RawWhlSpeed, base-type=uint16, implementation-data-type=uint16, transfer-property=PENDING
          signal CAN1_LR_RawWhlSpeed_V: start 52, 1 bit, big-endian, i-signal-type=PRIMITIVE, init-value=constant-reference=Init_CAN1_LR_RawWhlSpeed_V, base-type=uint8, implementation-data-type=uint8, transfer-property=PENDING
          signal CAN1_LR_WhlRotDir: start 54, 2 bit, big-endian, i-signal-type=PRIMITIVE, init-value=constant-reference=Init_CAN1_LR_WhlRotDir, base-type=uint8, implementation-data-type=uint8, transfer-property=PENDING
          signal CAN1_RR_PulseCount: start 23, 8 bit, big-endian, i-signal-type=PRIMITIVE, init-value=constant-reference=Init_CAN1_RR_PulseCount, base-type=uint8, implementation-data-type=uint8, transfer-property=PENDING
          signal CAN1_RR_PulseCount_V: start 31, 1 bit, big-endian, i-signal-type=PRIMITIVE, init-value=constant-reference=Init_CAN1_RR_PulseCount_V, base-type=uint8, implementation-data-type=uint8, transfer-property=PENDING
          signal CAN1_RR_RawWhlSpeed: start 27, 12 bit, big-endian, i-signal-type=PRIMITIVE, init-value=constant-reference=Init_CAN1_RR_RawWhlSpeed, base-type=uint16, implementation-data-type=uint16, transfer-property=PENDING
          signal CAN1_RR_RawWhlSpeed_V: start 28, 1 bit, big-endian, i-signal-type=PRIMITIVE, init-value=constant-reference=Init_CAN1_RR_RawWhlSpeed_V, base-type=uint8, implementation-data-type=uint8, transfer-property=PENDING
          signal CAN1_RR_WhlRotDir: start 30, 2 bit, big-endian, i-signal-type=PRIMITIVE, init-value=constant-reference=Init_CAN1_RR_WhlRotDir, base-type=uint8, implementation-data-type=uint8, transfer-property=PENDING
          signal CAN1_R_WhlSpeed_CRC_8: start 7, 8 bit, big-endian, i-signal-type=PRIMITIVE, init-value=constant-reference=Init_CAN1_R_WhlSpeed_CRC_8, base-type=uint8, implementation-data-type=uint8, transfer-property=PENDING
          signal CAN1_R_WhlSpeed_Count: start 15, 8 bit, big-endian, i-signal-type=PRIMITIVE, init-value=constant-reference=Init_CAN1_R_WhlSpeed_Count, base-type=uint8, implementation-data-type=uint8, transfer-property=PENDING
      frame CAN1_ESC4: id 0x1A3, frame-length=8, can-addressing-mode=STANDARD, can-fd-frame-support=true, can-frame-rx-behavior=CAN-FD, can-frame-tx-behavior=CAN-FD
        pdu CAN1_ESC4: length=8, minimum-delay=0.0, transmission-mode-true-timing=cyclic-timing=time-period=0.01, unused-bit-pattern=0
          mapping CAN1_SG_ESC4: i-signal-group=CAN1_SG_ESC4, start-position=0, transfer-property=PENDING
          signal CAN1_ABS_Active: start 45, 1 bit, big-endian, i-signal-type=PRIMITIVE, init-value=constant-reference=Init_CAN1_ABS_Active, base-type=uint8, implementation-data-type=uint8, transfer-property=PENDING
          signal CAN1_ABS_Failed: start 25, 1 bit, big-endian, i-signal-type=PRIMITIVE, init-value=constant-reference=Init_CAN1_ABS_Failed, base-type=uint8, implementation-data-type=uint8, transfer-property=PENDING
          signal CAN1_ABS_WnlmpSta: start 60, 1 bit, big-endian, i-signal-type=PRIMITIVE, init-value=constant-reference=Init_CAN1_ABS_WnlmpSta, base-type=uint8, implementation-data-type=uint8, transfer-property=PENDING
          signal CAN1_AVH_Active: start 35, 1 bit, big-endian, i-signal-type=PRIMITIVE, init-value=constant-reference=Init_CAN1_AVH_Active, base-type=uint8, implementation-data-type=uint8, transfer-property=PENDING
          signal CAN1_AVH_Failed: start 31, 1 bit, big-endian, i-signal-type=PRIMITIVE, init-value=constant-reference=Init_CAN1_AVH_Failed, base-type=uint8, implementation-data-type=uint8, transfer-property=PENDING
          signal CAN1_Amber_WnlmpSta: start 36, 1 bit, big-endian, i-signal-type=PRIMITIVE, init-value=constant-reference=Init_CAN1_Amber_WnlmpSta, base-type=uint8, implementation-data-type=uint8, transfer-property=PENDING
          signal CAN1_BTCS_Active: start 37, 1 bit, big-endian, i-signal-type=PRIMITIVE, init-value=constant-reference=Init_CAN1_BTCS_Active, base-type=uint8, implementation-data-type=uint8, transfer-property=PENDING
          signal CAN1_EBD_Active: start 44, 1 bit, big-endian, i-signal-type=PRIMITIVE, init-value=constant-reference=Init_CAN1_EBD_Active, base-type=uint8, implementation-data-type=uint8, transfer-property=PENDING
          signal CAN1_EBD_Failed: start 24, 1 bit, big-endian, i-signal-type=PRIMITIVE, init-value=constant-reference=Init_CAN1_EBD_Failed, base-type=uint8, implementation-data-type=uint8, transfer-property=PENDING
          signal CAN1_ESC_Active: start 47, 1 bit, big-endian, i-signal-type=PRIMITIVE, init-value=constant-reference=Init_CAN1_ESC_Active, base-type=uint8, implementation-data-type=uint8, transfer-property=PENDING
          signal CAN1_ESC_BeepReq: start 15, 1 bit, big-endian, i-signal-type=PRIMITIVE, init-value=constant-reference=Init_CAN1_ESC_BeepReq, base-type=uint8, implementation-data-type=uint8, transfer-property=PENDING
          signal CAN1_ESC_Failed: start 27, 1 bit, big-endian, i-signal-type=PRIMITIVE, init-value=constant-reference=Init_CAN1_ESC_Failed, base-type=uint8, implementation-data-type=uint8, transfer-property=PENDING
          signal CAN1_ESC_OFF_Status: start 18, 2 bit, big-endian, i-signal-type=PRIMITIVE, init-value=constant-reference=Init_CAN1_ESC_OFF_Status, base-type=uint8, implementation-data-type=uint8, transfer-property=PENDING
          signal CAN1_ESC_Off_lmpSta: start 61, 1 bit, big-endian, i-signal-type=PRIMITIVE, init-value=constant-reference=Init_CAN1_ESC_Off_lmpSta, base-type=uint8, implementation-data-type=uint8, transfer-property=PENDING
          signal CAN1_ESC_WnlmpSta: start 63, 2 bit, big-endian, i-signal-type=PRIMITIVE, init-value=constant-reference=Init_CAN1_ESC_WnlmpSta, base-type=uint8, implementation-data-type=uint8, transfer-property=PENDING
          signal CAN1_ESS_Active: start 38, 1 bit, big-endian, i-signal-type=PRIMITIVE, init-value=constant-reference=Init_CAN1_ESS_Active, base-type=uint8, implementation-data-type=uint8, transfer-property=PENDING
          signal CAN1_GRADE: start 55, 8 bit, big-endian, i-signal-type=PRIMITIVE, init-value=constant-reference=Init_CAN1_GRADE, base-type=uint8, implementation-data-type=uint8, transfer-property=PENDING
          signal CAN1_HBB_Active: start 32, 1 bit, big-endian, i-signal-type=PRIMITIVE, init-value=constant-reference=Init_CAN1_HBB_Active, base-type=uint8, implementation-data-type=uint8, transfer-property=PENDING
          signal CAN1_HBB_Failed: start 28, 1 bit, big-endian, i-signal-type=PRIMITIVE, init-value=constant-reference=Init_CAN1_HBB_Failed, base-type=uint8, implementation-data-type=uint8, transfer-property=PENDING
          signal CAN1_HDD_Active: start 39, 1 bit, big-endian, i-signal-type=PRIMITIVE, init-value=constant-reference=Init_CAN1_HDD_Active, base-type=uint8, implementation-data-type=uint8, transfer-property=PENDING
          signal CAN1_HDD_Failed: start 16, 1 bit, big-endian, i-signal-type=PRIMITIVE, init-value=constant-reference=Init_CAN1_HDD_Failed, base-type=uint8, implementation-data-type=uint8, transfer-property=PENDING
          signal CAN1_HSA_Active: start 34, 1 bit, big-endian, i-signal-type=PRIMITIVE, init-value=constant-reference=Init_CAN1_HSA_Active, base-type=uint8, implementation-data-type=uint8, transfer-property=PENDING
          signal CAN1_HSA_Failed: start 30, 1 bit, big-endian, i-signal-type=PRIMITIVE, init-value=constant-reference=Init_CAN1_HSA_Failed, base-type=uint8, implementation-data-type=uint8, transfer-property=PENDING
          signal CAN1_PBA_Active: start 33, 1 bit, big-endian, i-signal-type=PRIMITIVE, init-value=constant-reference=Init_CAN1_PBA_Active, base-type=uint8, implementation-data-type=uint8, transfer-property=PENDING
          signal CAN1_PBA_Failed: start 29, 1 bit, big-endian, i-signal-type=PRIMITIVE, init-value=constant-reference=Init_CAN1_PBA_Failed, base-type=uint8, implementation-data-type=uint8, transfer-property=PENDING
          signal CAN1_Red_WnlmpSta: start 59, 1 bit, big-endian, i-signal-type=PRIMITIVE, init-value=constant-reference=Init_CAN1_Red_WnlmpSta, base-type=uint8, implementation-data-type=uint8, transfer-property=PENDING
          signal CAN1_SystemVoltage: start 7, 8 bit, big-endian, i-signal-type=PRIMITIVE, init-value=constant-reference=Init_CAN1_SystemVoltage, base-type=uint8, implementation-data-type=uint8, transfer-property=PENDING
          signal CAN1_TCS_Active: start 46, 1 bit, big-endian, i-signal-type=PRIMITIVE, init-value=constant-reference=Init_CAN1_TCS_Active, base-type=uint8, implementation-data-type=uint8, transfer-property=PENDING
          signal CAN1_TCS_Failed: start 26, 1 bit, big-endian, i-signal-type=PRIMITIVE, init-value=constant-reference=Init_CAN1_TCS_Failed, base-type=uint8, implementation-data-type=uint8, transfer-property=PENDING
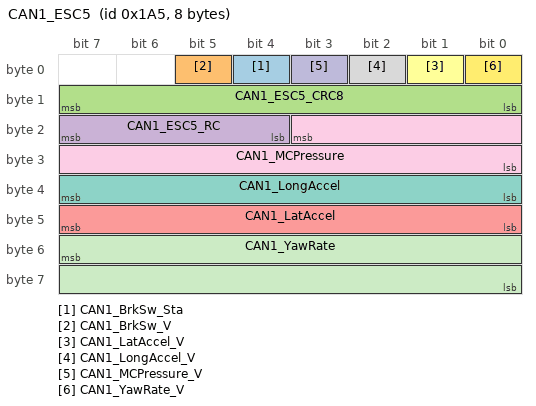
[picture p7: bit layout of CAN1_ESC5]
      frame CAN1_ESC5: id 0x1A5, frame-length=8, can-addressing-mode=STANDARD, can-fd-frame-support=true, can-frame-rx-behavior=CAN-FD, can-frame-tx-behavior=CAN-FD
        pdu CAN1_ESC5: length=8, minimum-delay=0.0, transmission-mode-true-timing=cyclic-timing=time-period=0.01, unused-bit-pattern=0
          mapping CAN1_SG_ESC5: i-signal-group=CAN1_SG_ESC5, start-position=0, transfer-property=PENDING
          signal CAN1_BrkSw_Sta: start 4, 1 bit, big-endian, i-signal-type=PRIMITIVE, init-value=constant-reference=Init_CAN1_BrkSw_Sta, base-type=uint8, implementation-data-type=uint8, transfer-property=PENDING
          signal CAN1_BrkSw_V: start 5, 1 bit, big-endian, i-signal-type=PRIMITIVE, init-value=constant-reference=Init_CAN1_BrkSw_V, base-type=uint8, implementation-data-type=uint8, transfer-property=PENDING
          signal CAN1_ESC5_CRC8: start 15, 8 bit, big-endian, i-signal-type=PRIMITIVE, init-value=constant-reference=Init_CAN1_ESC5_CRC8, base-type=uint8, implementation-data-type=uint8, transfer-property=PENDING
          signal CAN1_ESC5_RC: start 23, 4 bit, big-endian, i-signal-type=PRIMITIVE, init-value=constant-reference=Init_CAN1_ESC5_RC, base-type=uint8, implementation-data-type=uint8, transfer-property=PENDING
          signal CAN1_LatAccel: start 47, 8 bit, big-endian, i-signal-type=PRIMITIVE, init-value=constant-reference=Init_CAN1_LatAccel, base-type=uint8, implementation-data-type=uint8, transfer-property=PENDING
          signal CAN1_LatAccel_V: start 1, 1 bit, big-endian, i-signal-type=PRIMITIVE, init-value=constant-reference=Init_CAN1_LatAccel_V, base-type=uint8, implementation-data-type=uint8, transfer-property=PENDING
          signal CAN1_LongAccel: start 39, 8 bit, big-endian, i-signal-type=PRIMITIVE, init-value=constant-reference=Init_CAN1_LongAccel, base-type=uint8, implementation-data-type=uint8, transfer-property=PENDING
          signal CAN1_LongAccel_V: start 2, 1 bit, big-endian, i-signal-type=PRIMITIVE, init-value=constant-reference=Init_CAN1_LongAccel_V, base-type=uint8, implementation-data-type=uint8, transfer-property=PENDING
          signal CAN1_MCPressure: start 19, 12 bit, big-endian, i-signal-type=PRIMITIVE, init-value=constant-reference=Init_CAN1_MCPressure, base-type=uint16, implementation-data-type=uint16, transfer-property=PENDING
          signal CAN1_MCPressure_V: start 3, 1 bit, big-endian, i-signal-type=PRIMITIVE, init-value=constant-reference=Init_CAN1_MCPressure_V, base-type=uint8, implementation-data-type=uint8, transfer-property=PENDING
          signal CAN1_YawRate: start 55, 16 bit, big-endian, i-signal-type=PRIMITIVE, init-value=constant-reference=Init_CAN1_YawRate, base-type=uint16, implementation-data-type=uint16, transfer-property=PENDING
          signal CAN1_YawRate_V: start 0, 1 bit, big-endian, i-signal-type=PRIMITIVE, init-value=constant-reference=Init_CAN1_YawRate_V, base-type=uint8, implementation-data-type=uint8, transfer-property=PENDING
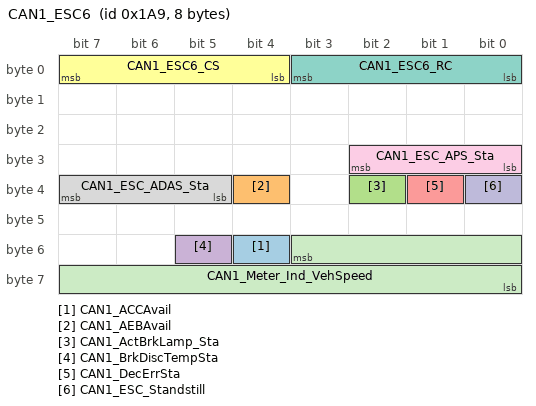
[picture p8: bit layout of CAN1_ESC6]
      frame CAN1_ESC6: id 0x1A9, frame-length=8, can-addressing-mode=STANDARD, can-fd-frame-support=true, can-frame-rx-behavior=CAN-FD, can-frame-tx-behavior=CAN-FD
        pdu CAN1_ESC6: length=8, minimum-delay=0.0, transmission-mode-true-timing=cyclic-timing=time-period=0.01, unused-bit-pattern=0
          mapping CAN1_SG_ESC6: i-signal-group=CAN1_SG_ESC6, start-position=0, transfer-property=PENDING
          signal CAN1_ACCAvail: start 52, 1 bit, big-endian, i-signal-type=PRIMITIVE, init-value=constant-reference=Init_CAN1_ACCAvail, base-type=uint8, implementation-data-type=uint8, transfer-property=PENDING
          signal CAN1_AEBAvail: start 36, 1 bit, big-endian, i-signal-type=PRIMITIVE, init-value=constant-reference=Init_CAN1_AEBAvail, base-type=uint8, implementation-data-type=uint8, transfer-property=PENDING
          signal CAN1_ActBrkLamp_Sta: start 34, 1 bit, big-endian, i-signal-type=PRIMITIVE, init-value=constant-reference=Init_CAN1_ActBrkLamp_Sta, base-type=uint8, implementation-data-type=uint8, transfer-property=PENDING
          signal CAN1_BrkDiscTempSta: start 53, 1 bit, big-endian, i-signal-type=PRIMITIVE, init-value=constant-reference=Init_CAN1_BrkDiscTempSta, base-type=uint8, implementation-data-type=uint8, transfer-property=PENDING
          signal CAN1_DecErrSta: start 33, 1 bit, big-endian, i-signal-type=PRIMITIVE, init-value=constant-reference=Init_CAN1_DecErrSta, base-type=uint8, implementation-data-type=uint8, transfer-property=PENDING
          signal CAN1_ESC6_CS: start 7, 4 bit, big-endian, i-signal-type=PRIMITIVE, init-value=constant-reference=Init_CAN1_ESC6_CS, base-type=uint8, implementation-data-type=uint8, transfer-property=PENDING
          signal CAN1_ESC6_RC: start 3, 4 bit, big-endian, i-signal-type=PRIMITIVE, init-value=constant-reference=Init_CAN1_ESC6_RC, base-type=uint8, implementation-data-type=uint8, transfer-property=PENDING
          signal CAN1_ESC_ADAS_Sta: start 39, 3 bit, big-endian, i-signal-type=PRIMITIVE, init-value=constant-reference=Init_CAN1_ESC_ADAS_Sta, base-type=uint8, implementation-data-type=uint8, transfer-property=PENDING
          signal CAN1_ESC_APS_Sta: start 26, 3 bit, big-endian, i-signal-type=PRIMITIVE, init-value=constant-reference=Init_CAN1_ESC_APS_Sta, base-type=uint8, implementation-data-type=uint8, transfer-property=PENDING
          signal CAN1_ESC_Standstill: start 32, 1 bit, big-endian, i-signal-type=PRIMITIVE, init-value=constant-reference=Init_CAN1_ESC_Standstill, base-type=uint8, implementation-data-type=uint8, transfer-property=PENDING
          signal CAN1_Meter_Ind_VehSpeed: start 51, 12 bit, big-endian, i-signal-type=PRIMITIVE, init-value=constant-reference=Init_CAN1_Meter_Ind_VehSpeed, base-type=uint16, implementation-data-type=uint16, transfer-property=PENDING
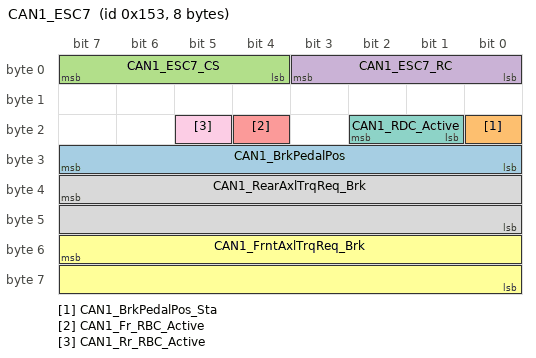
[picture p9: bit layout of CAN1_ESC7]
      frame CAN1_ESC7: id 0x153, frame-length=8, can-addressing-mode=STANDARD, can-fd-frame-support=true, can-frame-rx-behavior=CAN-FD, can-frame-tx-behavior=CAN-FD
        pdu CAN1_ESC7: length=8, minimum-delay=0.0, transmission-mode-true-timing=cyclic-timing=time-period=0.01, unused-bit-pattern=0
          mapping CAN1_SG_ESC7: i-signal-group=CAN1_SG_ESC7, start-position=0, transfer-property=PENDING
          signal CAN1_BrkPedalPos: start 31, 8 bit, big-endian, i-signal-type=PRIMITIVE, init-value=constant-reference=Init_CAN1_BrkPedalPos, base-type=uint8, implementation-data-type=uint8, transfer-property=PENDING
          signal CAN1_BrkPedalPos_Sta: start 16, 1 bit, big-endian, i-signal-type=PRIMITIVE, init-value=constant-reference=Init_CAN1_BrkPedalPos_Sta, base-type=uint8, implementation-data-type=uint8, transfer-property=PENDING
          signal CAN1_ESC7_CS: start 7, 4 bit, big-endian, i-signal-type=PRIMITIVE, init-value=constant-reference=Init_CAN1_ESC7_CS, base-type=uint8, implementation-data-type=uint8, transfer-property=PENDING
          signal CAN1_ESC7_RC: start 3, 4 bit, big-endian, i-signal-type=PRIMITIVE, init-value=constant-reference=Init_CAN1_ESC7_RC, base-type=uint8, implementation-data-type=uint8, transfer-property=PENDING
          signal CAN1_Fr_RBC_Active: start 20, 1 bit, big-endian, i-signal-type=PRIMITIVE, init-value=constant-reference=Init_CAN1_Fr_RBC_Active, base-type=uint8, implementation-data-type=uint8, transfer-property=PENDING
          signal CAN1_FrntAxlTrqReq_Brk: start 55, 16 bit, big-endian, i-signal-type=PRIMITIVE, init-value=constant-reference=Init_CAN1_FrntAxlTrqReq_Brk, base-type=uint16, implementation-data-type=uint16, transfer-property=PENDING
          signal CAN1_RDC_Active: start 18, 2 bit, big-endian, i-signal-type=PRIMITIVE, init-value=constant-reference=Init_CAN1_RDC_Active, base-type=uint8, implementation-data-type=uint8, transfer-property=PENDING
          signal CAN1_RearAxlTrqReq_Brk: start 39, 16 bit, big-endian, i-signal-type=PRIMITIVE, init-value=constant-reference=Init_CAN1_RearAxlTrqReq_Brk, base-type=uint16, implementation-data-type=uint16, transfer-property=PENDING
          signal CAN1_Rr_RBC_Active: start 21, 1 bit, big-endian, i-signal-type=PRIMITIVE, init-value=constant-reference=Init_CAN1_Rr_RBC_Active, base-type=uint8, implementation-data-type=uint8, transfer-property=PENDING
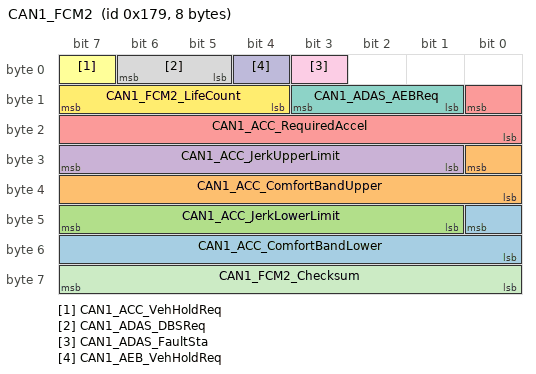
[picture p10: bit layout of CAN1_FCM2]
      frame CAN1_FCM2: id 0x179, frame-length=8, can-addressing-mode=STANDARD, can-fd-frame-support=true, can-frame-rx-behavior=CAN-FD, can-frame-tx-behavior=CAN-FD
        pdu CAN1_FCM2: length=8, minimum-delay=0.0, transmission-mode-true-timing=cyclic-timing=time-period=0.01, unused-bit-pattern=0
          mapping CAN1_SG_FCM2: i-signal-group=CAN1_SG_FCM2, start-position=0, transfer-property=PENDING
          signal CAN1_ACC_ComfortBandLower: start 40, 9 bit, big-endian, i-signal-type=PRIMITIVE, init-value=constant-reference=Init_CAN1_ACC_ComfortBandLower, base-type=uint16, implementation-data-type=uint16, transfer-property=PENDING
          signal CAN1_ACC_ComfortBandUpper: start 24, 9 bit, big-endian, i-signal-type=PRIMITIVE, init-value=constant-reference=Init_CAN1_ACC_ComfortBandUpper, base-type=uint16, implementation-data-type=uint16, transfer-property=PENDING
          signal CAN1_ACC_JerkLowerLimit: start 47, 7 bit, big-endian, i-signal-type=PRIMITIVE, init-value=constant-reference=Init_CAN1_ACC_JerkLowerLimit, base-type=uint8, implementation-data-type=uint8, transfer-property=PENDING
          signal CAN1_ACC_JerkUpperLimit: start 31, 7 bit, big-endian, i-signal-type=PRIMITIVE, init-value=constant-reference=Init_CAN1_ACC_JerkUpperLimit, base-type=uint8, implementation-data-type=uint8, transfer-property=PENDING
          signal CAN1_ACC_RequiredAccel: start 8, 9 bit, big-endian, i-signal-type=PRIMITIVE, init-value=constant-reference=Init_CAN1_ACC_RequiredAccel, base-type=uint16, implementation-data-type=uint16, transfer-property=PENDING
          signal CAN1_ACC_VehHoldReq: start 7, 1 bit, big-endian, i-signal-type=PRIMITIVE, init-value=constant-reference=Init_CAN1_ACC_VehHoldReq, base-type=uint8, implementation-data-type=uint8, transfer-property=PENDING
          signal CAN1_ADAS_AEBReq: start 11, 3 bit, big-endian, i-signal-type=PRIMITIVE, init-value=constant-reference=Init_CAN1_ADAS_AEBReq, base-type=uint8, implementation-data-type=uint8, transfer-property=PENDING
          signal CAN1_ADAS_DBSReq: start 6, 2 bit, big-endian, i-signal-type=PRIMITIVE, init-value=constant-reference=Init_CAN1_ADAS_DBSReq, base-type=uint8, implementation-data-type=uint8, transfer-property=PENDING
          signal CAN1_ADAS_FaultSta: start 3, 1 bit, big-endian, i-signal-type=PRIMITIVE, init-value=constant-reference=Init_CAN1_ADAS_FaultSta, base-type=uint8, implementation-data-type=uint8, transfer-property=PENDING
          signal CAN1_AEB_VehHoldReq: start 4, 1 bit, big-endian, i-signal-type=PRIMITIVE, init-value=constant-reference=Init_CAN1_AEB_VehHoldReq, base-type=uint8, implementation-data-type=uint8, transfer-property=PENDING
          signal CAN1_FCM2_Checksum: start 63, 8 bit, big-endian, i-signal-type=PRIMITIVE, init-value=constant-reference=Init_CAN1_FCM2_Checksum, base-type=uint8, implementation-data-type=uint8, transfer-property=PENDING
          signal CAN1_FCM2_LifeCount: start 15, 4 bit, big-endian, i-signal-type=PRIMITIVE, init-value=constant-reference=Init_CAN1_FCM2_LifeCount, base-type=uint8, implementation-data-type=uint8, transfer-property=PENDING
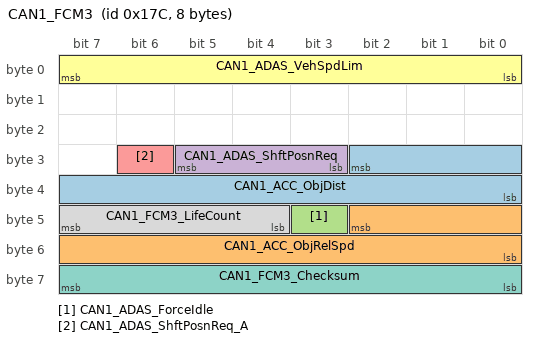
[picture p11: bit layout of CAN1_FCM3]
      frame CAN1_FCM3: id 0x17C, frame-length=8, can-addressing-mode=STANDARD, can-fd-frame-support=true, can-frame-rx-behavior=CAN-FD, can-frame-tx-behavior=CAN-FD
        pdu CAN1_FCM3: length=8, minimum-delay=0.0, transmission-mode-true-timing=cyclic-timing=time-period=0.01, unused-bit-pattern=0
          mapping CAN1_SG_FCM3: i-signal-group=CAN1_SG_FCM3, start-position=0, transfer-property=PENDING
          signal CAN1_ACC_ObjDist: start 26, 11 bit, big-endian, i-signal-type=PRIMITIVE, init-value=constant-reference=Init_CAN1_ACC_ObjDist, base-type=uint16, implementation-data-type=uint16, transfer-property=PENDING
          signal CAN1_ACC_ObjRelSpd: start 42, 11 bit, big-endian, i-signal-type=PRIMITIVE, init-value=constant-reference=Init_CAN1_ACC_ObjRelSpd, base-type=uint16, implementation-data-type=uint16, transfer-property=PENDING
          signal CAN1_ADAS_ForceIdle: start 43, 1 bit, big-endian, i-signal-type=PRIMITIVE, init-value=constant-reference=Init_CAN1_ADAS_ForceIdle, base-type=uint8, implementation-data-type=uint8, transfer-property=PENDING
          signal CAN1_ADAS_ShftPosnReq: start 29, 3 bit, big-endian, i-signal-type=PRIMITIVE, init-value=constant-reference=Init_CAN1_ADAS_ShftPosnReq, base-type=uint8, implementation-data-type=uint8, transfer-property=PENDING
          signal CAN1_ADAS_ShftPosnReq_A: start 30, 1 bit, big-endian, i-signal-type=PRIMITIVE, init-value=constant-reference=Init_CAN1_ADAS_ShftPosnReq_A, base-type=uint8, implementation-data-type=uint8, transfer-property=PENDING
          signal CAN1_ADAS_VehSpdLim: start 7, 8 bit, big-endian, i-signal-type=PRIMITIVE, init-value=constant-reference=Init_CAN1_ADAS_VehSpdLim, base-type=uint8, implementation-data-type=uint8, transfer-property=PENDING
          signal CAN1_FCM3_Checksum: start 63, 8 bit, big-endian, i-signal-type=PRIMITIVE, init-value=constant-reference=Init_CAN1_FCM3_Checksum, base-type=uint8, implementation-data-type=uint8, transfer-property=PENDING
          signal CAN1_FCM3_LifeCount: start 47, 4 bit, big-endian, i-signal-type=PRIMITIVE, init-value=constant-reference=Init_CAN1_FCM3_LifeCount, base-type=uint8, implementation-data-type=uint8, transfer-property=PENDING
      frame CAN1_FCM4: id 0x23A, frame-length=8, can-addressing-mode=STANDARD, can-fd-frame-support=true, can-frame-rx-behavior=CAN-FD, can-frame-tx-behavior=CAN-FD
        pdu CAN1_FCM4: length=8, minimum-delay=0.0, transmission-mode-true-timing=cyclic-timing=time-period=0.1, unused-bit-pattern=0
          mapping CAN1_SG_FCM4: i-signal-group=CAN1_SG_FCM4, start-position=0, transfer-property=PENDING
          signal CAN1_ACCSetSpeed: start 31, 8 bit, big-endian, i-signal-type=PRIMITIVE, init-value=constant-reference=Init_CAN1_ACCSetSpeed, base-type=uint8, implementation-data-type=uint8, transfer-property=PENDING
          signal CAN1_ACCSetSpeed_Disp: start 39, 3 bit, big-endian, i-signal-type=PRIMITIVE, init-value=constant-reference=Init_CAN1_ACCSetSpeed_Disp, base-type=uint8, implementation-data-type=uint8, transfer-property=PENDING
          signal CAN1_ACC_ObjDstLvl: start 23, 3 bit, big-endian, i-signal-type=PRIMITIVE, init-value=constant-reference=Init_CAN1_ACC_ObjDstLvl, base-type=uint8, implementation-data-type=uint8, transfer-property=PENDING
          signal CAN1_ACC_TakeoverReq: start 36, 1 bit, big-endian, i-signal-type=PRIMITIVE, init-value=constant-reference=Init_CAN1_ACC_TakeoverReq, base-type=uint8, implementation-data-type=uint8, transfer-property=PENDING
          signal CAN1_ADAS_ACC_Sta: start 10, 3 bit, big-endian, i-signal-type=PRIMITIVE, init-value=constant-reference=Init_CAN1_ADAS_ACC_Sta, base-type=uint8, implementation-data-type=uint8, transfer-property=PENDING
          signal CAN1_ADAS_AEB_Sta: start 6, 3 bit, big-endian, i-signal-type=PRIMITIVE, init-value=constant-reference=Init_CAN1_ADAS_AEB_Sta, base-type=uint8, implementation-data-type=uint8, transfer-property=PENDING
          signal CAN1_ADAS_CAM_SpdLim: start 47, 5 bit, big-endian, i-signal-type=PRIMITIVE, init-value=constant-reference=Init_CAN1_ADAS_CAM_SpdLim, base-type=uint8, implementation-data-type=uint8, transfer-property=PENDING
          signal CAN1_ADAS_FCW_Sta: start 2, 3 bit, big-endian, i-signal-type=PRIMITIVE, init-value=constant-reference=Init_CAN1_ADAS_FCW_Sta, base-type=uint8, implementation-data-type=uint8, transfer-property=PENDING
          signal CAN1_ADAS_FltWrnReq: start 11, 1 bit, big-endian, i-signal-type=PRIMITIVE, init-value=constant-reference=Init_CAN1_ADAS_FltWrnReq, base-type=uint8, implementation-data-type=uint8, transfer-property=PENDING
          signal CAN1_ADAS_LDW_Sta: start 14, 3 bit, big-endian, i-signal-type=PRIMITIVE, init-value=constant-reference=Init_CAN1_ADAS_LDW_Sta, base-type=uint8, implementation-data-type=uint8, transfer-property=PENDING
          signal CAN1_ADAS_SLIF_SpdLim: start 52, 5 bit, big-endian, i-signal-type=PRIMITIVE, init-value=constant-reference=Init_CAN1_ADAS_SLIF_SpdLim, base-type=uint8, implementation-data-type=uint8, transfer-property=PENDING
          signal CAN1_ADAS_WarningMsg: start 35, 4 bit, big-endian, i-signal-type=PRIMITIVE, init-value=constant-reference=Init_CAN1_ADAS_WarningMsg, base-type=uint8, implementation-data-type=uint8, transfer-property=PENDING
          signal CAN1_FCM4_Checksum: start 63, 8 bit, big-endian, i-signal-type=PRIMITIVE, init-value=constant-reference=Init_CAN1_FCM4_Checksum, base-type=uint8, implementation-data-type=uint8, transfer-property=PENDING
          signal CAN1_ForceLowBeam: start 20, 2 bit, big-endian, i-signal-type=PRIMITIVE, init-value=constant-reference=Init_CAN1_ForceLowBeam, base-type=uint8, implementation-data-type=uint8, transfer-property=PENDING
          signal CAN1_HazardWarningReq: start 7, 1 bit, big-endian, i-signal-type=PRIMITIVE, init-value=constant-reference=Init_CAN1_HazardWarningReq, base-type=uint8, implementation-data-type=uint8, transfer-property=PENDING
          signal CAN1_LeftTurnLightReq: start 15, 1 bit, big-endian, i-signal-type=PRIMITIVE, init-value=constant-reference=Init_CAN1_LeftTurnLightReq, base-type=uint8, implementation-data-type=uint8, transfer-property=PENDING
          signal CAN1_RightTurnLightReq: start 3, 1 bit, big-endian, i-signal-type=PRIMITIVE, init-value=constant-reference=Init_CAN1_RightTurnLightReq, base-type=uint8, implementation-data-type=uint8, transfer-property=PENDING
          signal CAN1_Target_Type: start 40, 4 bit, big-endian, i-signal-type=PRIMITIVE, init-value=constant-reference=Init_CAN1_Target_Type, base-type=uint8, implementation-data-type=uint8, transfer-property=PENDING
          signal CAN1_TimeGapLevel: start 18, 3 bit, big-endian, i-signal-type=PRIMITIVE, init-value=constant-reference=Init_CAN1_TimeGapLevel, base-type=uint8, implementation-data-type=uint8, transfer-property=PENDING
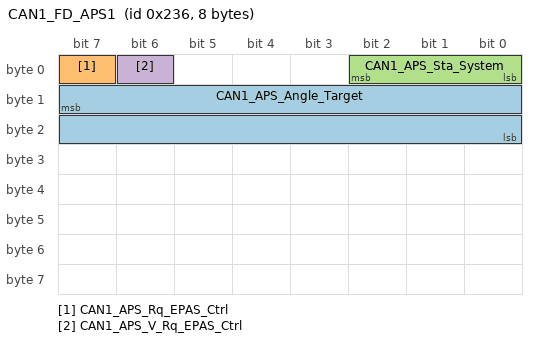
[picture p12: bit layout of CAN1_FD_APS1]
      frame CAN1_FD_APS1: id 0x236, frame-length=8, can-addressing-mode=STANDARD, can-fd-frame-support=true, can-frame-rx-behavior=CAN-FD, can-frame-tx-behavior=CAN-FD
        pdu CAN1_FD_APS1: length=8, minimum-delay=0.0, transmission-mode-true-timing=cyclic-timing=time-period=0.02, unused-bit-pattern=0
          mapping CAN1_SG_FD_APS1: i-signal-group=CAN1_SG_FD_APS1, start-position=0, transfer-property=PENDING
          signal CAN1_APS_Angle_Target: start 15, 16 bit, big-endian, i-signal-type=PRIMITIVE, init-value=constant-reference=Init_CAN1_APS_Angle_Target, base-type=uint16, implementation-data-type=uint16, transfer-property=PENDING
          signal CAN1_APS_Rq_EPAS_Ctrl: start 7, 1 bit, big-endian, i-signal-type=PRIMITIVE, init-value=constant-reference=Init_CAN1_APS_Rq_EPAS_Ctrl, base-type=uint8, implementation-data-type=uint8, transfer-property=PENDING
          signal CAN1_APS_Sta_System: start 2, 3 bit, big-endian, i-signal-type=PRIMITIVE, init-value=constant-reference=Init_CAN1_APS_Sta_System, base-type=uint8, implementation-data-type=uint8, transfer-property=PENDING
          signal CAN1_APS_V_Rq_EPAS_Ctrl: start 6, 1 bit, big-endian, i-signal-type=PRIMITIVE, init-value=constant-reference=Init_CAN1_APS_V_Rq_EPAS_Ctrl, base-type=uint8, implementation-data-type=uint8, transfer-property=PENDING
      frame CAN1_FD_APS2: id 0x210, frame-length=32, can-addressing-mode=STANDARD, can-fd-frame-support=true, can-frame-rx-behavior=CAN-FD, can-frame-tx-behavior=CAN-FD
        pdu CAN1_FD_APS2: length=32, minimum-delay=0.0, transmission-mode-true-timing=cyclic-timing=time-period=0.02, unused-bit-pattern=0
          mapping CAN1_SG_FD_APS2: i-signal-group=CAN1_SG_FD_APS2, start-position=0, transfer-property=PENDING
          signal CAN1_APS_D_FLL: start 49, 10 bit, big-endian, i-signal-type=PRIMITIVE, init-value=constant-reference=Init_CAN1_APS_D_FLL, base-type=uint16, implementation-data-type=uint16, transfer-property=PENDING
          signal CAN1_APS_D_FLR: start 65, 10 bit, big-endian, i-signal-type=PRIMITIVE, init-value=constant-reference=Init_CAN1_APS_D_FLR, base-type=uint16, implementation-data-type=uint16, transfer-property=PENDING
          signal CAN1_APS_D_RLL: start 81, 10 bit, big-endian, i-signal-type=PRIMITIVE, init-value=constant-reference=Init_CAN1_APS_D_RLL, base-type=uint16, implementation-data-type=uint16, transfer-property=PENDING
          signal CAN1_APS_D_RLR: start 97, 10 bit, big-endian, i-signal-type=PRIMITIVE, init-value=constant-reference=Init_CAN1_APS_D_RLR, base-type=uint16, implementation-data-type=uint16, transfer-property=PENDING
          signal CAN1_APS_ExitCondition: start 151, 8 bit, big-endian, i-signal-type=PRIMITIVE, init-value=constant-reference=Init_CAN1_APS_ExitCondition, base-type=uint8, implementation-data-type=uint8, transfer-property=PENDING
          signal CAN1_APS_HW_Ver: start 159, 8 bit, big-endian, i-signal-type=PRIMITIVE, init-value=constant-reference=Init_CAN1_APS_HW_Ver, base-type=uint8, implementation-data-type=uint8, transfer-property=PENDING
          signal CAN1_APS_Progress_PCT: start 215, 8 bit, big-endian, i-signal-type=PRIMITIVE, init-value=constant-reference=Init_CAN1_APS_Progress_PCT, base-type=uint8, implementation-data-type=uint8, transfer-property=PENDING
          signal CAN1_APS_RQ_Display: start 207, 8 bit, big-endian, i-signal-type=PRIMITIVE, init-value=constant-reference=Init_CAN1_APS_RQ_Display, base-type=uint8, implementation-data-type=uint8, transfer-property=PENDING
          signal CAN1_APS_SW_Ver: start 167, 8 bit, big-endian, i-signal-type=PRIMITIVE, init-value=constant-reference=Init_CAN1_APS_SW_Ver, base-type=uint8, implementation-data-type=uint8, transfer-property=PENDING
          signal CAN1_PAS_A_FCL: start 219, 4 bit, big-endian, i-signal-type=PRIMITIVE, init-value=constant-reference=Init_CAN1_PAS_A_FCL, base-type=uint8, implementation-data-type=uint8, transfer-property=PENDING
          signal CAN1_PAS_A_FCR: start 23, 4 bit, big-endian, i-signal-type=PRIMITIVE, init-value=constant-reference=Init_CAN1_PAS_A_FCR, base-type=uint8, implementation-data-type=uint8, transfer-property=PENDING
          signal CAN1_PAS_A_FML: start 19, 4 bit, big-endian, i-signal-type=PRIMITIVE, init-value=constant-reference=Init_CAN1_PAS_A_FML, base-type=uint8, implementation-data-type=uint8, transfer-property=PENDING
          signal CAN1_PAS_A_FMR: start 31, 4 bit, big-endian, i-signal-type=PRIMITIVE, init-value=constant-reference=Init_CAN1_PAS_A_FMR, base-type=uint8, implementation-data-type=uint8, transfer-property=PENDING
          signal CAN1_PAS_A_RCL: start 27, 4 bit, big-endian, i-signal-type=PRIMITIVE, init-value=constant-reference=Init_CAN1_PAS_A_RCL, base-type=uint8, implementation-data-type=uint8, transfer-property=PENDING
          signal CAN1_PAS_A_RCR: start 39, 4 bit, big-endian, i-signal-type=PRIMITIVE, init-value=constant-reference=Init_CAN1_PAS_A_RCR, base-type=uint8, implementation-data-type=uint8, transfer-property=PENDING
          signal CAN1_PAS_A_RML: start 35, 4 bit, big-endian, i-signal-type=PRIMITIVE, init-value=constant-reference=Init_CAN1_PAS_A_RML, base-type=uint8, implementation-data-type=uint8, transfer-property=PENDING
          signal CAN1_PAS_A_RMR: start 47, 4 bit, big-endian, i-signal-type=PRIMITIVE, init-value=constant-reference=Init_CAN1_PAS_A_RMR, base-type=uint8, implementation-data-type=uint8, transfer-property=PENDING
          signal CAN1_PAS_Chime: start 223, 4 bit, big-endian, i-signal-type=PRIMITIVE, init-value=constant-reference=Init_CAN1_PAS_Chime, base-type=uint8, implementation-data-type=uint8, transfer-property=PENDING
          signal CAN1_PAS_D_FCL: start 119, 8 bit, big-endian, i-signal-type=PRIMITIVE, init-value=constant-reference=Init_CAN1_PAS_D_FCL, base-type=uint8, implementation-data-type=uint8, transfer-property=PENDING
          signal CAN1_PAS_D_FCR: start 127, 8 bit, big-endian, i-signal-type=PRIMITIVE, init-value=constant-reference=Init_CAN1_PAS_D_FCR, base-type=uint8, implementation-data-type=uint8, transfer-property=PENDING
          signal CAN1_PAS_D_FML: start 135, 8 bit, big-endian, i-signal-type=PRIMITIVE, init-value=constant-reference=Init_CAN1_PAS_D_FML, base-type=uint8, implementation-data-type=uint8, transfer-property=PENDING
          signal CAN1_PAS_D_FMR: start 143, 8 bit, big-endian, i-signal-type=PRIMITIVE, init-value=constant-reference=Init_CAN1_PAS_D_FMR, base-type=uint8, implementation-data-type=uint8, transfer-property=PENDING
          signal CAN1_PAS_D_RCL: start 175, 8 bit, big-endian, i-signal-type=PRIMITIVE, init-value=constant-reference=Init_CAN1_PAS_D_RCL, base-type=uint8, implementation-data-type=uint8, transfer-property=PENDING
          signal CAN1_PAS_D_RCR: start 183, 8 bit, big-endian, i-signal-type=PRIMITIVE, init-value=constant-reference=Init_CAN1_PAS_D_RCR, base-type=uint8, implementation-data-type=uint8, transfer-property=PENDING
          signal CAN1_PAS_D_RML: start 191, 8 bit, big-endian, i-signal-type=PRIMITIVE, init-value=constant-reference=Init_CAN1_PAS_D_RML, base-type=uint8, implementation-data-type=uint8, transfer-property=PENDING
          signal CAN1_PAS_D_RMR: start 199, 8 bit, big-endian, i-signal-type=PRIMITIVE, init-value=constant-reference=Init_CAN1_PAS_D_RMR, base-type=uint8, implementation-data-type=uint8, transfer-property=PENDING
          signal CAN1_PAS_Mod_Operation: start 11, 2 bit, big-endian, i-signal-type=PRIMITIVE, init-value=constant-reference=Init_CAN1_PAS_Mod_Operation, base-type=uint8, implementation-data-type=uint8, transfer-property=PENDING
          signal CAN1_PAS_SNSR_Layout: start 43, 4 bit, big-endian, i-signal-type=PRIMITIVE, init-value=constant-reference=Init_CAN1_PAS_SNSR_Layout, base-type=uint8, implementation-data-type=uint8, transfer-property=PENDING
          signal CAN1_PAS_Sta_F_Sys: start 9, 1 bit, big-endian, i-signal-type=PRIMITIVE, init-value=constant-reference=Init_CAN1_PAS_Sta_F_Sys, base-type=uint8, implementation-data-type=uint8, transfer-property=PENDING
          signal CAN1_USS_Sta_FCL: start 7, 1 bit, big-endian, i-signal-type=PRIMITIVE, init-value=constant-reference=Init_CAN1_USS_Sta_FCL, base-type=uint8, implementation-data-type=uint8, transfer-property=PENDING
          signal CAN1_USS_Sta_FCR: start 6, 1 bit, big-endian, i-signal-type=PRIMITIVE, init-value=constant-reference=Init_CAN1_USS_Sta_FCR, base-type=uint8, implementation-data-type=uint8, transfer-property=PENDING
          signal CAN1_USS_Sta_FLL: start 5, 1 bit, big-endian, i-signal-type=PRIMITIVE, init-value=constant-reference=Init_CAN1_USS_Sta_FLL, base-type=uint8, implementation-data-type=uint8, transfer-property=PENDING
          signal CAN1_USS_Sta_FLR: start 4, 1 bit, big-endian, i-signal-type=PRIMITIVE, init-value=constant-reference=Init_CAN1_USS_Sta_FLR, base-type=uint8, implementation-data-type=uint8, transfer-property=PENDING
          signal CAN1_USS_Sta_FML: start 3, 1 bit, big-endian, i-signal-type=PRIMITIVE, init-value=constant-reference=Init_CAN1_USS_Sta_FML, base-type=uint8, implementation-data-type=uint8, transfer-property=PENDING
          signal CAN1_USS_Sta_FMR: start 2, 1 bit, big-endian, i-signal-type=PRIMITIVE, init-value=constant-reference=Init_CAN1_USS_Sta_FMR, base-type=uint8, implementation-data-type=uint8, transfer-property=PENDING
          signal CAN1_USS_Sta_RCL: start 1, 1 bit, big-endian, i-signal-type=PRIMITIVE, init-value=constant-reference=Init_CAN1_USS_Sta_RCL, base-type=uint8, implementation-data-type=uint8, transfer-property=PENDING
          signal CAN1_USS_Sta_RCR: start 0, 1 bit, big-endian, i-signal-type=PRIMITIVE, init-value=constant-reference=Init_CAN1_USS_Sta_RCR, base-type=uint8, implementation-data-type=uint8, transfer-property=PENDING
          signal CAN1_USS_Sta_RLL: start 15, 1 bit, big-endian, i-signal-type=PRIMITIVE, init-value=constant-reference=Init_CAN1_USS_Sta_RLL, base-type=uint8, implementation-data-type=uint8, transfer-property=PENDING
          signal CAN1_USS_Sta_RLR: start 14, 1 bit, big-endian, i-signal-type=PRIMITIVE, init-value=constant-reference=Init_CAN1_USS_Sta_RLR, base-type=uint8, implementation-data-type=uint8, transfer-property=PENDING
          signal CAN1_USS_Sta_RML: start 13, 1 bit, big-endian, i-signal-type=PRIMITIVE, init-value=constant-reference=Init_CAN1_USS_Sta_RML, base-type=uint8, implementation-data-type=uint8, transfer-property=PENDING
          signal CAN1_USS_Sta_RMR: start 12, 1 bit, big-endian, i-signal-type=PRIMITIVE, init-value=constant-reference=Init_CAN1_USS_Sta_RMR, base-type=uint8, implementation-data-type=uint8, transfer-property=PENDING
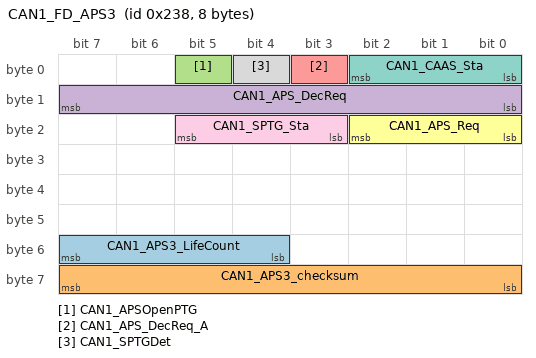
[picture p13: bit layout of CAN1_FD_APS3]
      frame CAN1_FD_APS3: id 0x238, frame-length=8, can-addressing-mode=STANDARD, can-fd-frame-support=true, can-frame-rx-behavior=CAN-FD, can-frame-tx-behavior=CAN-FD
        pdu CAN1_FD_APS3: length=8, minimum-delay=0.0, transmission-mode-true-timing=cyclic-timing=time-period=0.01, unused-bit-pattern=0
          mapping CAN1_SG_FD_APS3: i-signal-group=CAN1_SG_FD_APS3, start-position=0, transfer-property=PENDING
          signal CAN1_APS3_LifeCount: start 55, 4 bit, big-endian, i-signal-type=PRIMITIVE, init-value=constant-reference=Init_CAN1_APS3_LifeCount, base-type=uint8, implementation-data-type=uint8, transfer-property=PENDING
          signal CAN1_APS3_checksum: start 63, 8 bit, big-endian, i-signal-type=PRIMITIVE, init-value=constant-reference=Init_CAN1_APS3_checksum, base-type=uint8, implementation-data-type=uint8, transfer-property=PENDING
          signal CAN1_APSOpenPTG: start 5, 1 bit, big-endian, i-signal-type=PRIMITIVE, init-value=constant-reference=Init_CAN1_APSOpenPTG, base-type=uint8, implementation-data-type=uint8, transfer-property=PENDING
          signal CAN1_APS_DecReq: start 15, 8 bit, big-endian, i-signal-type=PRIMITIVE, init-value=constant-reference=Init_CAN1_APS_DecReq, base-type=uint8, implementation-data-type=uint8, transfer-property=PENDING
          signal CAN1_APS_DecReq_A: start 3, 1 bit, big-endian, i-signal-type=PRIMITIVE, init-value=constant-reference=Init_CAN1_APS_DecReq_A, base-type=uint8, implementation-data-type=uint8, transfer-property=PENDING
          signal CAN1_APS_Req: start 18, 3 bit, big-endian, i-signal-type=PRIMITIVE, init-value=constant-reference=Init_CAN1_APS_Req, base-type=uint8, implementation-data-type=uint8, transfer-property=PENDING
          signal CAN1_CAAS_Sta: start 2, 3 bit, big-endian, i-signal-type=PRIMITIVE, init-value=constant-reference=Init_CAN1_CAAS_Sta, base-type=uint8, implementation-data-type=uint8, transfer-property=PENDING
          signal CAN1_SPTGDet: start 4, 1 bit, big-endian, i-signal-type=PRIMITIVE, init-value=constant-reference=Init_CAN1_SPTGDet, base-type=uint8, implementation-data-type=uint8, transfer-property=PENDING
          signal CAN1_SPTG_Sta: start 21, 3 bit, big-endian, i-signal-type=PRIMITIVE, init-value=constant-reference=Init_CAN1_SPTG_Sta, base-type=uint8, implementation-data-type=uint8, transfer-property=PENDING
      frame CAN1_FD_BCM1: id 0x216, frame-length=16, can-addressing-mode=STANDARD, can-fd-frame-support=true, can-frame-rx-behavior=CAN-FD, can-frame-tx-behavior=CAN-FD
        pdu CAN1_FD_BCM1: length=16, minimum-delay=0.0, transmission-mode-true-timing={cyclic-timing=time-period=0.2, event-controlled-timing={number-of-repetitions=0, repetition-period=0.06}}, unused-bit-pattern=0
          mapping CAN1_SG_FD_BCM1: i-signal-group=CAN1_SG_FD_BCM1, start-position=0, transfer-property=TRIGGERED-ON-CHANGE
          signal CAN1_AllDoorSW: start 124, 1 bit, big-endian, i-signal-type=PRIMITIVE, init-value=constant-reference=Init_CAN1_AllDoorSW, base-type=uint8, implementation-data-type=uint8, transfer-property=TRIGGERED-ON-CHANGE
          signal CAN1_AntiTheftSeatFold: start 84, 1 bit, big-endian, i-signal-type=PRIMITIVE, init-value=constant-reference=Init_CAN1_AntiTheftSeatFold, base-type=uint8, implementation-data-type=uint8, transfer-property=TRIGGERED-ON-CHANGE
          signal CAN1_AntitheftSta: start 83, 2 bit, big-endian, i-signal-type=PRIMITIVE, init-value=constant-reference=Init_CAN1_AntitheftSta, base-type=uint8, implementation-data-type=uint8, transfer-property=TRIGGERED-ON-CHANGE
          signal CAN1_BCM_Buzzer_Req: start 64, 1 bit, big-endian, i-signal-type=PRIMITIVE, init-value=constant-reference=Init_CAN1_BCM_Buzzer_Req, base-type=uint8, implementation-data-type=uint8, transfer-property=TRIGGERED-ON-CHANGE
          signal CAN1_BCM_DoorLock_Sta: start 70, 1 bit, big-endian, i-signal-type=PRIMITIVE, init-value=constant-reference=Init_CAN1_BCM_DoorLock_Sta, base-type=uint8, implementation-data-type=uint8, transfer-property=TRIGGERED-ON-CHANGE
          signal CAN1_BrakeLamp: start 90, 1 bit, big-endian, i-signal-type=PRIMITIVE, init-value=constant-reference=Init_CAN1_BrakeLamp, base-type=uint8, implementation-data-type=uint8, transfer-property=TRIGGERED-ON-CHANGE
          signal CAN1_CTDCtrl: start 113, 2 bit, big-endian, i-signal-type=PRIMITIVE, init-value=constant-reference=Init_CAN1_CTDCtrl, base-type=uint8, implementation-data-type=uint8, transfer-property=TRIGGERED-ON-CHANGE
          signal CAN1_CTDLockSW: start 118, 1 bit, big-endian, i-signal-type=PRIMITIVE, init-value=constant-reference=Init_CAN1_CTDLockSW, base-type=uint8, implementation-data-type=uint8, transfer-property=TRIGGERED-ON-CHANGE
          signal CAN1_CTDUnlockSW: start 119, 1 bit, big-endian, i-signal-type=PRIMITIVE, init-value=constant-reference=Init_CAN1_CTDUnlockSW, base-type=uint8, implementation-data-type=uint8, transfer-property=TRIGGERED-ON-CHANGE
          signal CAN1_CrashDetd: start 85, 1 bit, big-endian, i-signal-type=PRIMITIVE, init-value=constant-reference=Init_CAN1_CrashDetd, base-type=uint8, implementation-data-type=uint8, transfer-property=TRIGGERED-ON-CHANGE
          signal CAN1_Dimmer: start 78, 7 bit, big-endian, i-signal-type=PRIMITIVE, init-value=constant-reference=Init_CAN1_Dimmer, base-type=uint8, implementation-data-type=uint8, transfer-property=TRIGGERED-ON-CHANGE
          signal CAN1_DimmerEN: start 69, 1 bit, big-endian, i-signal-type=PRIMITIVE, init-value=constant-reference=Init_CAN1_DimmerEN, base-type=uint8, implementation-data-type=uint8, transfer-property=TRIGGERED-ON-CHANGE
          signal CAN1_DoorLockIND: start 125, 1 bit, big-endian, i-signal-type=PRIMITIVE, init-value=constant-reference=Init_CAN1_DoorLockIND, base-type=uint8, implementation-data-type=uint8, transfer-property=TRIGGERED-ON-CHANGE
          signal CAN1_DrDoorSW: start 120, 1 bit, big-endian, i-signal-type=PRIMITIVE, init-value=constant-reference=Init_CAN1_DrDoorSW, base-type=uint8, implementation-data-type=uint8, transfer-property=TRIGGERED-ON-CHANGE
          signal CAN1_Fr_ChargingDoorCtrl: start 115, 2 bit, big-endian, i-signal-type=PRIMITIVE, init-value=constant-reference=Init_CAN1_Fr_ChargingDoorCtrl, base-type=uint8, implementation-data-type=uint8, transfer-property=TRIGGERED-ON-CHANGE
          signal CAN1_Fr_FogLamp: start 93, 1 bit, big-endian, i-signal-type=PRIMITIVE, init-value=constant-reference=Init_CAN1_Fr_FogLamp, base-type=uint8, implementation-data-type=uint8, transfer-property=TRIGGERED-ON-CHANGE
          signal CAN1_Fr_Wiper_H: start 110, 1 bit, big-endian, i-signal-type=PRIMITIVE, init-value=constant-reference=Init_CAN1_Fr_Wiper_H, base-type=uint8, implementation-data-type=uint8, transfer-property=TRIGGERED-ON-CHANGE
          signal CAN1_Fr_Wiper_L: start 111, 1 bit, big-endian, i-signal-type=PRIMITIVE, init-value=constant-reference=Init_CAN1_Fr_Wiper_L, base-type=uint8, implementation-data-type=uint8, transfer-property=TRIGGERED-ON-CHANGE
          signal CAN1_H_Beam: start 101, 1 bit, big-endian, i-signal-type=PRIMITIVE, init-value=constant-reference=Init_CAN1_H_Beam, base-type=uint8, implementation-data-type=uint8, transfer-property=TRIGGERED-ON-CHANGE
          signal CAN1_HazardSW: start 95, 1 bit, big-endian, i-signal-type=PRIMITIVE, init-value=constant-reference=Init_CAN1_HazardSW, base-type=uint8, implementation-data-type=uint8, transfer-property=TRIGGERED-ON-CHANGE
          signal CAN1_HoodSW: start 126, 1 bit, big-endian, i-signal-type=PRIMITIVE, init-value=constant-reference=Init_CAN1_HoodSW, base-type=uint8, implementation-data-type=uint8, transfer-property=TRIGGERED-ON-CHANGE
          signal CAN1_HornCtrl: start 71, 1 bit, big-endian, i-signal-type=PRIMITIVE, init-value=constant-reference=Init_CAN1_HornCtrl, base-type=uint8, implementation-data-type=uint8, transfer-property=TRIGGERED-ON-CHANGE
          signal CAN1_LBSD: start 91, 1 bit, big-endian, i-signal-type=PRIMITIVE, init-value=constant-reference=Init_CAN1_LBSD, base-type=uint8, implementation-data-type=uint8, transfer-property=TRIGGERED-ON-CHANGE
          signal CAN1_LDRL: start 103, 1 bit, big-endian, i-signal-type=PRIMITIVE, init-value=constant-reference=Init_CAN1_LDRL, base-type=uint8, implementation-data-type=uint8, transfer-property=TRIGGERED-ON-CHANGE
          signal CAN1_LTurnLP: start 80, 1 bit, big-endian, i-signal-type=PRIMITIVE, init-value=constant-reference=Init_CAN1_LTurnLP, base-type=uint8, implementation-data-type=uint8, transfer-property=TRIGGERED-ON-CHANGE
          signal CAN1_L_APM_WdwEnable: start 87, 1 bit, big-endian, i-signal-type=PRIMITIVE, init-value=constant-reference=Init_CAN1_L_APM_WdwEnable, base-type=uint8, implementation-data-type=uint8, transfer-property=TRIGGERED-ON-CHANGE
          signal CAN1_L_Beam: start 100, 1 bit, big-endian, i-signal-type=PRIMITIVE, init-value=constant-reference=Init_CAN1_L_Beam, base-type=uint8, implementation-data-type=uint8, transfer-property=TRIGGERED-ON-CHANGE
          signal CAN1_LockSetting: start 79, 1 bit, big-endian, i-signal-type=PRIMITIVE, init-value=constant-reference=Init_CAN1_LockSetting, base-type=uint8, implementation-data-type=uint8, transfer-property=TRIGGERED-ON-CHANGE
          signal CAN1_MirrorCtrl: start 109, 2 bit, big-endian, i-signal-type=PRIMITIVE, init-value=constant-reference=Init_CAN1_MirrorCtrl, base-type=uint8, implementation-data-type=uint8, transfer-property=TRIGGERED-ON-CHANGE
          signal CAN1_MirrorDefog: start 104, 1 bit, big-endian, i-signal-type=PRIMITIVE, init-value=constant-reference=Init_CAN1_MirrorDefog, base-type=uint8, implementation-data-type=uint8, transfer-property=TRIGGERED-ON-CHANGE
          signal CAN1_PosLamp: start 102, 1 bit, big-endian, i-signal-type=PRIMITIVE, init-value=constant-reference=Init_CAN1_PosLamp, base-type=uint8, implementation-data-type=uint8, transfer-property=TRIGGERED-ON-CHANGE
          signal CAN1_PsDoorSW: start 121, 1 bit, big-endian, i-signal-type=PRIMITIVE, init-value=constant-reference=Init_CAN1_PsDoorSW, base-type=uint8, implementation-data-type=uint8, transfer-property=TRIGGERED-ON-CHANGE
          signal CAN1_RBSD: start 92, 1 bit, big-endian, i-signal-type=PRIMITIVE, init-value=constant-reference=Init_CAN1_RBSD, base-type=uint8, implementation-data-type=uint8, transfer-property=TRIGGERED-ON-CHANGE
          signal CAN1_RDRL: start 88, 1 bit, big-endian, i-signal-type=PRIMITIVE, init-value=constant-reference=Init_CAN1_RDRL, base-type=uint8, implementation-data-type=uint8, transfer-property=TRIGGERED-ON-CHANGE
          signal CAN1_RLDoorSW: start 122, 1 bit, big-endian, i-signal-type=PRIMITIVE, init-value=constant-reference=Init_CAN1_RLDoorSW, base-type=uint8, implementation-data-type=uint8, transfer-property=TRIGGERED-ON-CHANGE
          signal CAN1_RRDoorSW: start 123, 1 bit, big-endian, i-signal-type=PRIMITIVE, init-value=constant-reference=Init_CAN1_RRDoorSW, base-type=uint8, implementation-data-type=uint8, transfer-property=TRIGGERED-ON-CHANGE
          signal CAN1_RTurnLP: start 81, 1 bit, big-endian, i-signal-type=PRIMITIVE, init-value=constant-reference=Init_CAN1_RTurnLP, base-type=uint8, implementation-data-type=uint8, transfer-property=TRIGGERED-ON-CHANGE
          signal CAN1_ReverseLamp: start 89, 1 bit, big-endian, i-signal-type=PRIMITIVE, init-value=constant-reference=Init_CAN1_ReverseLamp, base-type=uint8, implementation-data-type=uint8, transfer-property=TRIGGERED-ON-CHANGE
          signal CAN1_RoomLampH: start 68, 1 bit, big-endian, i-signal-type=PRIMITIVE, init-value=constant-reference=Init_CAN1_RoomLampH, base-type=uint8, implementation-data-type=uint8, transfer-property=TRIGGERED-ON-CHANGE
          signal CAN1_RoomLampL: start 67, 1 bit, big-endian, i-signal-type=PRIMITIVE, init-value=constant-reference=Init_CAN1_RoomLampL, base-type=uint8, implementation-data-type=uint8, transfer-property=TRIGGERED-ON-CHANGE
          signal CAN1_Rr_ChargingDoorCtrl: start 117, 2 bit, big-endian, i-signal-type=PRIMITIVE, init-value=constant-reference=Init_CAN1_Rr_ChargingDoorCtrl, base-type=uint8, implementation-data-type=uint8, transfer-property=TRIGGERED-ON-CHANGE
          signal CAN1_Rr_Defog: start 105, 1 bit, big-endian, i-signal-type=PRIMITIVE, init-value=constant-reference=Init_CAN1_Rr_Defog, base-type=uint8, implementation-data-type=uint8, transfer-property=TRIGGERED-ON-CHANGE
          signal CAN1_Rr_FogLamp: start 94, 1 bit, big-endian, i-signal-type=PRIMITIVE, init-value=constant-reference=Init_CAN1_Rr_FogLamp, base-type=uint8, implementation-data-type=uint8, transfer-property=TRIGGERED-ON-CHANGE
          signal CAN1_Rr_Wiper: start 96, 1 bit, big-endian, i-signal-type=PRIMITIVE, init-value=constant-reference=Init_CAN1_Rr_Wiper, base-type=uint8, implementation-data-type=uint8, transfer-property=TRIGGERED-ON-CHANGE
          signal CAN1_TailgateHDSW: start 107, 1 bit, big-endian, i-signal-type=PRIMITIVE, init-value=constant-reference=Init_CAN1_TailgateHDSW, base-type=uint8, implementation-data-type=uint8, transfer-property=TRIGGERED-ON-CHANGE
          signal CAN1_TailgateRemote: start 66, 2 bit, big-endian, i-signal-type=PRIMITIVE, init-value=constant-reference=Init_CAN1_TailgateRemote, base-type=uint8, implementation-data-type=uint8, transfer-property=TRIGGERED-ON-CHANGE
          signal CAN1_Tailgate_SW: start 127, 1 bit, big-endian, i-signal-type=PRIMITIVE, init-value=constant-reference=Init_CAN1_Tailgate_SW, base-type=uint8, implementation-data-type=uint8, transfer-property=TRIGGERED-ON-CHANGE
          signal CAN1_TrunkRel: start 106, 1 bit, big-endian, i-signal-type=PRIMITIVE, init-value=constant-reference=Init_CAN1_TrunkRel, base-type=uint8, implementation-data-type=uint8, transfer-property=TRIGGERED-ON-CHANGE
          signal CAN1_WasherCtrl: start 99, 2 bit, big-endian, i-signal-type=PRIMITIVE, init-value=constant-reference=Init_CAN1_WasherCtrl, base-type=uint8, implementation-data-type=uint8, transfer-property=TRIGGERED-ON-CHANGE
          signal CAN1_WiperFixMode: start 97, 1 bit, big-endian, i-signal-type=PRIMITIVE, init-value=constant-reference=Init_CAN1_WiperFixMode, base-type=uint8, implementation-data-type=uint8, transfer-property=TRIGGERED-ON-CHANGE
      frame CAN1_FD_THCM1: id 0x182, frame-length=20, can-addressing-mode=STANDARD, can-fd-frame-support=true, can-frame-rx-behavior=CAN-FD, can-frame-tx-behavior=CAN-FD
        pdu CAN1_FD_THCM1: length=20, minimum-delay=0.0, transmission-mode-true-timing=cyclic-timing=time-period=0.1, unused-bit-pattern=0
          mapping CAN1_SG_FD_THCM1: i-signal-group=CAN1_SG_FD_THCM1, start-position=0, transfer-property=PENDING
          signal CAN1_BatteryMode: start 118, 3 bit, big-endian, i-signal-type=PRIMITIVE, init-value=constant-reference=Init_CAN1_BatteryMode, base-type=uint8, implementation-data-type=uint8, transfer-property=PENDING
          signal CAN1_CCU_ACLampSts: start 6, 1 bit, big-endian, i-signal-type=PRIMITIVE, init-value=constant-reference=Init_CAN1_CCU_ACLampSts, base-type=uint8, implementation-data-type=uint8, transfer-property=PENDING
          signal CAN1_CCU_ACMaxLampSts: start 1, 1 bit, big-endian, i-signal-type=PRIMITIVE, init-value=constant-reference=Init_CAN1_CCU_ACMaxLampSts, base-type=uint8, implementation-data-type=uint8, transfer-property=PENDING
          signal CAN1_CCU_AutoLampSts: start 2, 1 bit, big-endian, i-signal-type=PRIMITIVE, init-value=constant-reference=Init_CAN1_CCU_AutoLampSts, base-type=uint8, implementation-data-type=uint8, transfer-property=PENDING
          signal CAN1_CCU_AutoMidLampSts: start 3, 1 bit, big-endian, i-signal-type=PRIMITIVE, init-value=constant-reference=Init_CAN1_CCU_AutoMidLampSts, base-type=uint8, implementation-data-type=uint8, transfer-property=PENDING
          signal CAN1_CCU_Dispaly_Request: start 5, 1 bit, big-endian, i-signal-type=PRIMITIVE, init-value=constant-reference=Init_CAN1_CCU_Dispaly_Request, base-type=uint8, implementation-data-type=uint8, transfer-property=PENDING
          signal CAN1_CCU_EcoSts: start 4, 1 bit, big-endian, i-signal-type=PRIMITIVE, init-value=constant-reference=Init_CAN1_CCU_EcoSts, base-type=uint8, implementation-data-type=uint8, transfer-property=PENDING
          signal CAN1_CCU_FrtOnOffLampSts: start 19, 1 bit, big-endian, i-signal-type=PRIMITIVE, init-value=constant-reference=Init_CAN1_CCU_FrtOnOffLampSts, base-type=uint8, implementation-data-type=uint8, transfer-property=PENDING
          signal CAN1_CCU_HEATMaxLampSts: start 7, 1 bit, big-endian, i-signal-type=PRIMITIVE, init-value=constant-reference=Init_CAN1_CCU_HEATMaxLampSts, base-type=uint8, implementation-data-type=uint8, transfer-property=PENDING
          signal CAN1_CCU_RrOnOffLampSts: start 23, 1 bit, big-endian, i-signal-type=PRIMITIVE, init-value=constant-reference=Init_CAN1_CCU_RrOnOffLampSts, base-type=uint8, implementation-data-type=uint8, transfer-property=PENDING
          signal CAN1_CCU_SyncLampSts: start 39, 1 bit, big-endian, i-signal-type=PRIMITIVE, init-value=constant-reference=Init_CAN1_CCU_SyncLampSts, base-type=uint8, implementation-data-type=uint8, transfer-property=PENDING
          signal CAN1_CabinMode: start 115, 4 bit, big-endian, i-signal-type=PRIMITIVE, init-value=constant-reference=Init_CAN1_CabinMode, base-type=uint8, implementation-data-type=uint8, transfer-property=PENDING
          signal CAN1_EDriveMode: start 63, 2 bit, big-endian, i-signal-type=PRIMITIVE, init-value=constant-reference=Init_CAN1_EDriveMode, base-type=uint8, implementation-data-type=uint8, transfer-property=PENDING
          signal CAN1_FD_AGS_Cmd: start 143, 8 bit, big-endian, i-signal-type=PRIMITIVE, init-value=constant-reference=Init_CAN1_FD_AGS_Cmd, base-type=uint8, implementation-data-type=uint8, transfer-property=PENDING
          signal CAN1_FD_RecyAuto_Cmd: start 111, 3 bit, big-endian, i-signal-type=PRIMITIVE, init-value=constant-reference=Init_CAN1_FD_RecyAuto_Cmd, base-type=uint8, implementation-data-type=uint8, transfer-property=PENDING
          signal CAN1_Fr_Coolantflow: start 61, 6 bit, big-endian, i-signal-type=PRIMITIVE, init-value=constant-reference=Init_CAN1_Fr_Coolantflow, base-type=uint8, implementation-data-type=uint8, transfer-property=PENDING
          signal CAN1_Fr_Coolanttemp: start 0, 9 bit, big-endian, i-signal-type=PRIMITIVE, init-value=constant-reference=Init_CAN1_Fr_Coolanttemp, base-type=uint16, implementation-data-type=uint16, transfer-property=PENDING
          signal CAN1_HPThermalRecoveryReq: start 55, 2 bit, big-endian, i-signal-type=PRIMITIVE, init-value=constant-reference=Init_CAN1_HPThermalRecoveryReq, base-type=uint8, implementation-data-type=uint8, transfer-property=PENDING
          signal CAN1_Rr_Coolantflow: start 150, 6 bit, big-endian, i-signal-type=PRIMITIVE, init-value=constant-reference=Init_CAN1_Rr_Coolantflow, base-type=uint8, implementation-data-type=uint8, transfer-property=PENDING
          signal CAN1_Rr_Coolanttemp: start 144, 9 bit, big-endian, i-signal-type=PRIMITIVE, init-value=constant-reference=Init_CAN1_Rr_Coolanttemp, base-type=uint16, implementation-data-type=uint16, transfer-property=PENDING
          signal CAN1_sigAirIntenZon1St: start 31, 4 bit, big-endian, i-signal-type=PRIMITIVE, init-value=constant-reference=Init_CAN1_sigAirIntenZon1St, base-type=uint8, implementation-data-type=uint8, transfer-property=PENDING
          signal CAN1_sigAirIntenZon3St: start 27, 4 bit, big-endian, i-signal-type=PRIMITIVE, init-value=constant-reference=Init_CAN1_sigAirIntenZon3St, base-type=uint8, implementation-data-type=uint8, transfer-property=PENDING
          signal CAN1_sigAmbAirT: start 95, 8 bit, big-endian, i-signal-type=PRIMITIVE, init-value=constant-reference=Init_CAN1_sigAmbAirT, base-type=uint8, implementation-data-type=uint8, transfer-property=PENDING
          signal CAN1_sigCbnAirT: start 87, 8 bit, big-endian, i-signal-type=PRIMITIVE, init-value=constant-reference=Init_CAN1_sigCbnAirT, base-type=uint8, implementation-data-type=uint8, transfer-property=PENDING
          signal CAN1_sigCbnPTCPwrAct: start 79, 8 bit, big-endian, i-signal-type=PRIMITIVE, init-value=constant-reference=Init_CAN1_sigCbnPTCPwrAct, base-type=uint8, implementation-data-type=uint8, transfer-property=PENDING
          signal CAN1_sigCbnSolarLeft: start 127, 8 bit, big-endian, i-signal-type=PRIMITIVE, init-value=constant-reference=Init_CAN1_sigCbnSolarLeft, base-type=uint8, implementation-data-type=uint8, transfer-property=PENDING
          signal CAN1_sigCbnSolarRight: start 103, 8 bit, big-endian, i-signal-type=PRIMITIVE, init-value=constant-reference=Init_CAN1_sigCbnSolarRight, base-type=uint8, implementation-data-type=uint8, transfer-property=PENDING
          signal CAN1_sigClmtCmprPwrAct: start 71, 8 bit, big-endian, i-signal-type=PRIMITIVE, init-value=constant-reference=Init_CAN1_sigClmtCmprPwrAct, base-type=uint8, implementation-data-type=uint8, transfer-property=PENDING
          signal CAN1_sigClntTHvBattOut: start 135, 8 bit, big-endian, i-signal-type=PRIMITIVE, init-value=constant-reference=Init_CAN1_sigClntTHvBattOut, base-type=uint8, implementation-data-type=uint8, transfer-property=PENDING
          signal CAN1_sigDfrstSt: start 38, 1 bit, big-endian, i-signal-type=PRIMITIVE, init-value=constant-reference=Init_CAN1_sigDfrstSt, base-type=uint8, implementation-data-type=uint8, transfer-property=PENDING
          signal CAN1_sigHvacSt: start 46, 1 bit, big-endian, i-signal-type=PRIMITIVE, init-value=constant-reference=Init_CAN1_sigHvacSt, base-type=uint8, implementation-data-type=uint8, transfer-property=PENDING
          signal CAN1_sigRecircSt: start 47, 1 bit, big-endian, i-signal-type=PRIMITIVE, init-value=constant-reference=Init_CAN1_sigRecircSt, base-type=uint8, implementation-data-type=uint8, transfer-property=PENDING
          signal CAN1_sigSetTempZon1St: start 53, 6 bit, big-endian, i-signal-type=PRIMITIVE, init-value=constant-reference=Init_CAN1_sigSetTempZon1St, base-type=uint8, implementation-data-type=uint8, transfer-property=PENDING
          signal CAN1_sigSetTempZon2St: start 45, 6 bit, big-endian, i-signal-type=PRIMITIVE, init-value=constant-reference=Init_CAN1_sigSetTempZon2St, base-type=uint8, implementation-data-type=uint8, transfer-property=PENDING
          signal CAN1_sigSetTempZon3St: start 37, 6 bit, big-endian, i-signal-type=PRIMITIVE, init-value=constant-reference=Init_CAN1_sigSetTempZon3St, base-type=uint8, implementation-data-type=uint8, transfer-property=PENDING
          signal CAN1_sigWindDirZon1St: start 22, 3 bit, big-endian, i-signal-type=PRIMITIVE, init-value=constant-reference=Init_CAN1_sigWindDirZon1St, base-type=uint8, implementation-data-type=uint8, transfer-property=PENDING
          signal CAN1_sigWindDirZon3St: start 18, 3 bit, big-endian, i-signal-type=PRIMITIVE, init-value=constant-reference=Init_CAN1_sigWindDirZon3St, base-type=uint8, implementation-data-type=uint8, transfer-property=PENDING
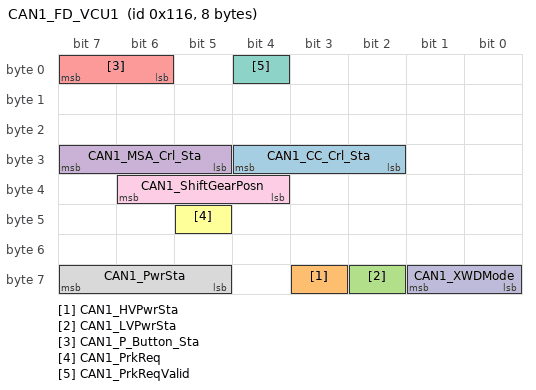
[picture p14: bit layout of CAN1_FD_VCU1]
      frame CAN1_FD_VCU1: id 0x116, frame-length=8, can-addressing-mode=STANDARD, can-fd-frame-support=true, can-frame-rx-behavior=CAN-FD, can-frame-tx-behavior=CAN-FD
        pdu CAN1_FD_VCU1: length=8, minimum-delay=0.0, transmission-mode-true-timing={cyclic-timing=time-period=0.1, event-controlled-timing={number-of-repetitions=0, repetition-period=0.01}}, unused-bit-pattern=0
          mapping CAN1_SG_FD_VCU1: i-signal-group=CAN1_SG_FD_VCU1, start-position=0, transfer-property=TRIGGERED-ON-CHANGE
          signal CAN1_CC_Crl_Sta: start 28, 3 bit, big-endian, i-signal-type=PRIMITIVE, init-value=constant-reference=Init_CAN1_CC_Crl_Sta, base-type=uint8, implementation-data-type=uint8, transfer-property=TRIGGERED-ON-CHANGE
          signal CAN1_HVPwrSta: start 59, 1 bit, big-endian, i-signal-type=PRIMITIVE, init-value=constant-reference=Init_CAN1_HVPwrSta, base-type=uint8, implementation-data-type=uint8, transfer-property=TRIGGERED-ON-CHANGE
          signal CAN1_LVPwrSta: start 58, 1 bit, big-endian, i-signal-type=PRIMITIVE, init-value=constant-reference=Init_CAN1_LVPwrSta, base-type=uint8, implementation-data-type=uint8, transfer-property=TRIGGERED-ON-CHANGE
          signal CAN1_MSA_Crl_Sta: start 31, 3 bit, big-endian, i-signal-type=PRIMITIVE, init-value=constant-reference=Init_CAN1_MSA_Crl_Sta, base-type=uint8, implementation-data-type=uint8, transfer-property=TRIGGERED-ON-CHANGE
          signal CAN1_P_Button_Sta: start 7, 2 bit, big-endian, i-signal-type=PRIMITIVE, init-value=constant-reference=Init_CAN1_P_Button_Sta, base-type=uint8, implementation-data-type=uint8, transfer-property=PENDING
          signal CAN1_PrkReq: start 45, 1 bit, big-endian, i-signal-type=PRIMITIVE, init-value=constant-reference=Init_CAN1_PrkReq, base-type=uint8, implementation-data-type=uint8, transfer-property=TRIGGERED-ON-CHANGE
          signal CAN1_PrkReqValid: start 4, 1 bit, big-endian, i-signal-type=PRIMITIVE, init-value=constant-reference=Init_CAN1_PrkReqValid, base-type=uint8, implementation-data-type=uint8, transfer-property=TRIGGERED-ON-CHANGE
          signal CAN1_PwrSta: start 63, 3 bit, big-endian, i-signal-type=PRIMITIVE, init-value=constant-reference=Init_CAN1_PwrSta, base-type=uint8, implementation-data-type=uint8, transfer-property=TRIGGERED-ON-CHANGE
          signal CAN1_ShiftGearPosn: start 38, 3 bit, big-endian, i-signal-type=PRIMITIVE, init-value=constant-reference=Init_CAN1_ShiftGearPosn, base-type=uint8, implementation-data-type=uint8, transfer-property=TRIGGERED-ON-CHANGE
          signal CAN1_XWDMode: start 57, 2 bit, big-endian, i-signal-type=PRIMITIVE, init-value=constant-reference=Init_CAN1_XWDMode, base-type=uint8, implementation-data-type=uint8, transfer-property=TRIGGERED-ON-CHANGE
      frame CAN1_FD_VCU2: id 0x154, frame-length=16, can-addressing-mode=STANDARD, can-fd-frame-support=true, can-frame-rx-behavior=CAN-FD, can-frame-tx-behavior=CAN-FD
        pdu CAN1_FD_VCU2: length=16, minimum-delay=0.0, transmission-mode-true-timing=cyclic-timing=time-period=0.01, unused-bit-pattern=0
          mapping CAN1_SG_FD_VCU2: i-signal-group=CAN1_SG_FD_VCU2, start-position=0, transfer-property=PENDING
          signal CAN1_ACC_CtrlAvail: start 15, 1 bit, big-endian, i-signal-type=PRIMITIVE, init-value=constant-reference=Init_CAN1_ACC_CtrlAvail, base-type=uint8, implementation-data-type=uint8, transfer-property=PENDING
          signal CAN1_AccPedal_Override: start 14, 1 bit, big-endian, i-signal-type=PRIMITIVE, init-value=constant-reference=Init_CAN1_AccPedal_Override, base-type=uint8, implementation-data-type=uint8, transfer-property=PENDING
          signal CAN1_ActAPSPosn: start 127, 8 bit, big-endian, i-signal-type=PRIMITIVE, init-value=constant-reference=Init_CAN1_ActAPSPosn, base-type=uint8, implementation-data-type=uint8, transfer-property=PENDING
          signal CAN1_CS_VCU2_CAN1: start 7, 8 bit, big-endian, i-signal-type=PRIMITIVE, init-value=constant-reference=Init_CAN1_CS_VCU2_CAN1, base-type=uint8, implementation-data-type=uint8, transfer-property=PENDING
          signal CAN1_DriverTq: start 111, 16 bit, big-endian, i-signal-type=PRIMITIVE, init-value=constant-reference=Init_CAN1_DriverTq, base-type=uint16, implementation-data-type=uint16, transfer-property=PENDING
          signal CAN1_Fr_DriverTq: start 23, 16 bit, big-endian, i-signal-type=PRIMITIVE, init-value=constant-reference=Init_CAN1_Fr_DriverTq, base-type=uint16, implementation-data-type=uint16, transfer-property=PENDING
          signal CAN1_RC_VCU2_CAN1: start 11, 4 bit, big-endian, i-signal-type=PRIMITIVE, init-value=constant-reference=Init_CAN1_RC_VCU2_CAN1, base-type=uint8, implementation-data-type=uint8, transfer-property=PENDING
          signal CAN1_Rr_DriverTq: start 39, 16 bit, big-endian, i-signal-type=PRIMITIVE, init-value=constant-reference=Init_CAN1_Rr_DriverTq, base-type=uint16, implementation-data-type=uint16, transfer-property=PENDING
          signal CAN1_VehActPwr: start 87, 24 bit, big-endian, i-signal-type=PRIMITIVE, init-value=constant-reference=Init_CAN1_VehActPwr, base-type=uint32, implementation-data-type=uint32, transfer-property=PENDING
      frame CAN1_FD_VCU3: id 0x159, frame-length=20, can-addressing-mode=STANDARD, can-fd-frame-support=true, can-frame-rx-behavior=CAN-FD, can-frame-tx-behavior=CAN-FD
        pdu CAN1_FD_VCU3: length=20, minimum-delay=0.0, transmission-mode-true-timing=cyclic-timing=time-period=0.01, unused-bit-pattern=0
          mapping CAN1_SG_FD_VCU3: i-signal-group=CAN1_SG_FD_VCU3, start-position=0, transfer-property=PENDING
          signal CAN1_CS_VCU3_CAN1: start 7, 8 bit, big-endian, i-signal-type=PRIMITIVE, init-value=constant-reference=Init_CAN1_CS_VCU3_CAN1, base-type=uint8, implementation-data-type=uint8, transfer-property=PENDING
          signal CAN1_EquivAccPedalSWSta: start 38, 1 bit, big-endian, i-signal-type=PRIMITIVE, init-value=constant-reference=Init_CAN1_EquivAccPedalSWSta, base-type=uint8, implementation-data-type=uint8, transfer-property=PENDING
          signal CAN1_Fr_EDUAvailBrkRgnTq: start 135, 16 bit, big-endian, i-signal-type=PRIMITIVE, init-value=constant-reference=Init_CAN1_Fr_EDUAvailBrkRgnTq, base-type=uint16, implementation-data-type=uint16, transfer-property=PENDING
          signal CAN1_Fr_EDUAvailBrkRgnTqValid: start 102, 1 bit, big-endian, i-signal-type=PRIMITIVE, init-value=constant-reference=Init_CAN1_Fr_EDUAvailBrkRgnTqValid, base-type=uint8, implementation-data-type=uint8, transfer-property=PENDING
          signal CAN1_Fr_EDURealARgnTq: start 119, 16 bit, big-endian, i-signal-type=PRIMITIVE, init-value=constant-reference=Init_CAN1_Fr_EDURealARgnTq, base-type=uint16, implementation-data-type=uint16, transfer-property=PENDING
          signal CAN1_Fr_EDURealDrvOrBRgnTq: start 151, 16 bit, big-endian, i-signal-type=PRIMITIVE, init-value=constant-reference=Init_CAN1_Fr_EDURealDrvOrBRgnTq, base-type=uint16, implementation-data-type=uint16, transfer-property=PENDING
          signal CAN1_Fr_EDUSpd: start 99, 12 bit, big-endian, i-signal-type=PRIMITIVE, init-value=constant-reference=Init_CAN1_Fr_EDUSpd, base-type=uint16, implementation-data-type=uint16, transfer-property=PENDING
          signal CAN1_Fr_EDUSpdValid: start 30, 1 bit, big-endian, i-signal-type=PRIMITIVE, init-value=constant-reference=Init_CAN1_Fr_EDUSpdValid, base-type=uint8, implementation-data-type=uint8, transfer-property=PENDING
          signal CAN1_Fr_RgnDecrSta: start 27, 1 bit, big-endian, i-signal-type=PRIMITIVE, init-value=constant-reference=Init_CAN1_Fr_RgnDecrSta, base-type=uint8, implementation-data-type=uint8, transfer-property=PENDING
          signal CAN1_Fr_RgnPermSta: start 25, 1 bit, big-endian, i-signal-type=PRIMITIVE, init-value=constant-reference=Init_CAN1_Fr_RgnPermSta, base-type=uint8, implementation-data-type=uint8, transfer-property=PENDING
          signal CAN1_PTCS_PermSta: start 39, 1 bit, big-endian, i-signal-type=PRIMITIVE, init-value=constant-reference=Init_CAN1_PTCS_PermSta, base-type=uint8, implementation-data-type=uint8, transfer-property=PENDING
          signal CAN1_RC_VCU3_CAN1: start 15, 4 bit, big-endian, i-signal-type=PRIMITIVE, init-value=constant-reference=Init_CAN1_RC_VCU3_CAN1, base-type=uint8, implementation-data-type=uint8, transfer-property=PENDING
          signal CAN1_RgnAbnorSta: start 28, 1 bit, big-endian, i-signal-type=PRIMITIVE, init-value=constant-reference=Init_CAN1_RgnAbnorSta, base-type=uint8, implementation-data-type=uint8, transfer-property=PENDING
          signal CAN1_Rr_EDUAvailBrkRgnTq: start 71, 16 bit, big-endian, i-signal-type=PRIMITIVE, init-value=constant-reference=Init_CAN1_Rr_EDUAvailBrkRgnTq, base-type=uint16, implementation-data-type=uint16, transfer-property=PENDING
          signal CAN1_Rr_EDUAvailBrkRgnTqValid: start 103, 1 bit, big-endian, i-signal-type=PRIMITIVE, init-value=constant-reference=Init_CAN1_Rr_EDUAvailBrkRgnTqValid, base-type=uint8, implementation-data-type=uint8, transfer-property=PENDING
          signal CAN1_Rr_EDURealARgnTq: start 55, 16 bit, big-endian, i-signal-type=PRIMITIVE, init-value=constant-reference=Init_CAN1_Rr_EDURealARgnTq, base-type=uint16, implementation-data-type=uint16, transfer-property=PENDING
          signal CAN1_Rr_EDURealDrvOrBRgnTq: start 87, 16 bit, big-endian, i-signal-type=PRIMITIVE, init-value=constant-reference=Init_CAN1_Rr_EDURealDrvOrBRgnTq, base-type=uint16, implementation-data-type=uint16, transfer-property=PENDING
          signal CAN1_Rr_EDUSpd: start 35, 12 bit, big-endian, i-signal-type=PRIMITIVE, init-value=constant-reference=Init_CAN1_Rr_EDUSpd, base-type=uint16, implementation-data-type=uint16, transfer-property=PENDING
          signal CAN1_Rr_EDUSpdValid: start 29, 1 bit, big-endian, i-signal-type=PRIMITIVE, init-value=constant-reference=Init_CAN1_Rr_EDUSpdValid, base-type=uint8, implementation-data-type=uint8, transfer-property=PENDING
          signal CAN1_Rr_RgnDecrSta: start 26, 1 bit, big-endian, i-signal-type=PRIMITIVE, init-value=constant-reference=Init_CAN1_Rr_RgnDecrSta, base-type=uint8, implementation-data-type=uint8, transfer-property=PENDING
          signal CAN1_Rr_RgnPermSta: start 24, 1 bit, big-endian, i-signal-type=PRIMITIVE, init-value=constant-reference=Init_CAN1_Rr_RgnPermSta, base-type=uint8, implementation-data-type=uint8, transfer-property=PENDING
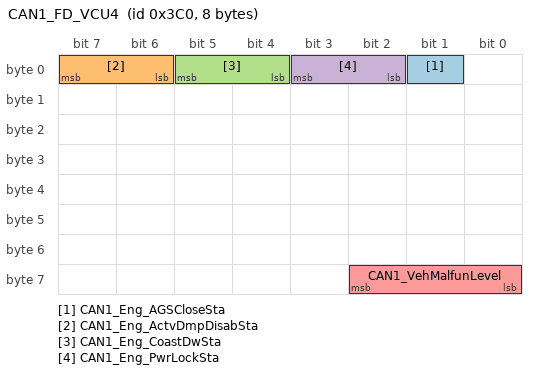
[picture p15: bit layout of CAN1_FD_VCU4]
      frame CAN1_FD_VCU4: id 0x3C0, frame-length=8, can-addressing-mode=STANDARD, can-fd-frame-support=true, can-frame-rx-behavior=CAN-FD, can-frame-tx-behavior=CAN-FD
        pdu CAN1_FD_VCU4: length=8, minimum-delay=0.0, transmission-mode-true-timing={cyclic-timing=time-period=0.2, event-controlled-timing={number-of-repetitions=0, repetition-period=0.05}}, unused-bit-pattern=0
          mapping CAN1_SG_FD_VCU4: i-signal-group=CAN1_SG_FD_VCU4, start-position=0, transfer-property=TRIGGERED-ON-CHANGE
          signal CAN1_Eng_AGSCloseSta: start 1, 1 bit, big-endian, i-signal-type=PRIMITIVE, init-value=constant-reference=Init_CAN1_Eng_AGSCloseSta, base-type=uint8, implementation-data-type=uint8, transfer-property=TRIGGERED-ON-CHANGE
          signal CAN1_Eng_ActvDmpDisabSta: start 7, 2 bit, big-endian, i-signal-type=PRIMITIVE, init-value=constant-reference=Init_CAN1_Eng_ActvDmpDisabSta, base-type=uint8, implementation-data-type=uint8, transfer-property=TRIGGERED-ON-CHANGE
          signal CAN1_Eng_CoastDwSta: start 5, 2 bit, big-endian, i-signal-type=PRIMITIVE, init-value=constant-reference=Init_CAN1_Eng_CoastDwSta, base-type=uint8, implementation-data-type=uint8, transfer-property=TRIGGERED-ON-CHANGE
          signal CAN1_Eng_PwrLockSta: start 3, 2 bit, big-endian, i-signal-type=PRIMITIVE, init-value=constant-reference=Init_CAN1_Eng_PwrLockSta, base-type=uint8, implementation-data-type=uint8, transfer-property=TRIGGERED-ON-CHANGE
          signal CAN1_VehMalfunLevel: start 58, 3 bit, big-endian, i-signal-type=PRIMITIVE, init-value=constant-reference=Init_CAN1_VehMalfunLevel, base-type=uint8, implementation-data-type=uint8, transfer-property=TRIGGERED-ON-CHANGE
      frame CAN1_SRR1: id 0x205, frame-length=8, can-addressing-mode=STANDARD, can-fd-frame-support=true, can-frame-rx-behavior=CAN-FD, can-frame-tx-behavior=CAN-FD
        pdu CAN1_SRR1: length=8, minimum-delay=0.0, transmission-mode-true-timing=cyclic-timing=time-period=0.1, unused-bit-pattern=0
          mapping CAN1_SG_SRR1: i-signal-group=CAN1_SG_SRR1, start-position=0, transfer-property=PENDING
          signal CAN1_SRR1_Chksum: start 63, 8 bit, big-endian, i-signal-type=PRIMITIVE, init-value=constant-reference=Init_CAN1_SRR1_Chksum, base-type=uint8, implementation-data-type=uint8, transfer-property=PENDING
          signal CAN1_SRR1_LifeCount: start 7, 4 bit, big-endian, i-signal-type=PRIMITIVE, init-value=constant-reference=Init_CAN1_SRR1_LifeCount, base-type=uint8, implementation-data-type=uint8, transfer-property=PENDING
          signal CAN1_SRR_BSD_Mute: start 46, 1 bit, big-endian, i-signal-type=PRIMITIVE, init-value=constant-reference=Init_CAN1_SRR_BSD_Mute, base-type=uint8, implementation-data-type=uint8, transfer-property=PENDING
          signal CAN1_SRR_BSD_SoundL: start 45, 1 bit, big-endian, i-signal-type=PRIMITIVE, init-value=constant-reference=Init_CAN1_SRR_BSD_SoundL, base-type=uint8, implementation-data-type=uint8, transfer-property=PENDING
          signal CAN1_SRR_BSD_SoundR: start 44, 1 bit, big-endian, i-signal-type=PRIMITIVE, init-value=constant-reference=Init_CAN1_SRR_BSD_SoundR, base-type=uint8, implementation-data-type=uint8, transfer-property=PENDING
          signal CAN1_SRR_BSD_Sta: start 10, 3 bit, big-endian, i-signal-type=PRIMITIVE, init-value=constant-reference=Init_CAN1_SRR_BSD_Sta, base-type=uint8, implementation-data-type=uint8, transfer-property=PENDING
          signal CAN1_SRR_BSD_WarnL: start 43, 2 bit, big-endian, i-signal-type=PRIMITIVE, init-value=constant-reference=Init_CAN1_SRR_BSD_WarnL, base-type=uint8, implementation-data-type=uint8, transfer-property=PENDING
          signal CAN1_SRR_BSD_WarnR: start 41, 2 bit, big-endian, i-signal-type=PRIMITIVE, init-value=constant-reference=Init_CAN1_SRR_BSD_WarnR, base-type=uint8, implementation-data-type=uint8, transfer-property=PENDING
          signal CAN1_SRR_FltWrnReq: start 15, 1 bit, big-endian, i-signal-type=PRIMITIVE, init-value=constant-reference=Init_CAN1_SRR_FltWrnReq, base-type=uint8, implementation-data-type=uint8, transfer-property=PENDING
          signal CAN1_SRR_ODA_Mute: start 38, 1 bit, big-endian, i-signal-type=PRIMITIVE, init-value=constant-reference=Init_CAN1_SRR_ODA_Mute, base-type=uint8, implementation-data-type=uint8, transfer-property=PENDING
          signal CAN1_SRR_ODA_SoundL: start 37, 1 bit, big-endian, i-signal-type=PRIMITIVE, init-value=constant-reference=Init_CAN1_SRR_ODA_SoundL, base-type=uint8, implementation-data-type=uint8, transfer-property=PENDING
          signal CAN1_SRR_ODA_SoundR: start 36, 1 bit, big-endian, i-signal-type=PRIMITIVE, init-value=constant-reference=Init_CAN1_SRR_ODA_SoundR, base-type=uint8, implementation-data-type=uint8, transfer-property=PENDING
          signal CAN1_SRR_ODA_Sta: start 18, 3 bit, big-endian, i-signal-type=PRIMITIVE, init-value=constant-reference=Init_CAN1_SRR_ODA_Sta, base-type=uint8, implementation-data-type=uint8, transfer-property=PENDING
          signal CAN1_SRR_ODA_WarnL: start 35, 2 bit, big-endian, i-signal-type=PRIMITIVE, init-value=constant-reference=Init_CAN1_SRR_ODA_WarnL, base-type=uint8, implementation-data-type=uint8, transfer-property=PENDING
          signal CAN1_SRR_ODA_WarnR: start 33, 2 bit, big-endian, i-signal-type=PRIMITIVE, init-value=constant-reference=Init_CAN1_SRR_ODA_WarnR, base-type=uint8, implementation-data-type=uint8, transfer-property=PENDING
          signal CAN1_SRR_RCTA_Sta: start 14, 3 bit, big-endian, i-signal-type=PRIMITIVE, init-value=constant-reference=Init_CAN1_SRR_RCTA_Sta, base-type=uint8, implementation-data-type=uint8, transfer-property=PENDING
          signal CAN1_SRR_RCTA_WarnL: start 49, 1 bit, big-endian, i-signal-type=PRIMITIVE, init-value=constant-reference=Init_CAN1_SRR_RCTA_WarnL, base-type=uint8, implementation-data-type=uint8, transfer-property=PENDING
          signal CAN1_SRR_RCTA_WarnR: start 48, 1 bit, big-endian, i-signal-type=PRIMITIVE, init-value=constant-reference=Init_CAN1_SRR_RCTA_WarnR, base-type=uint8, implementation-data-type=uint8, transfer-property=PENDING
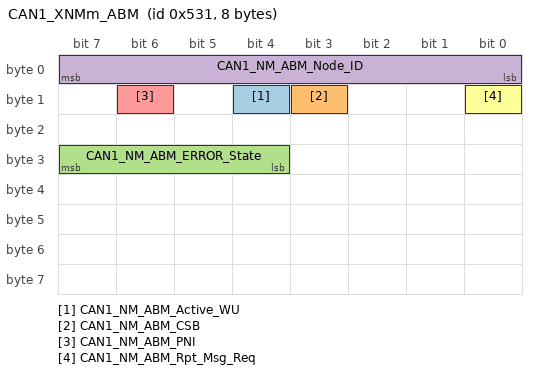
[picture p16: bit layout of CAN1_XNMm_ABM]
      frame CAN1_XNMm_ABM: id 0x531, frame-length=8, can-addressing-mode=STANDARD, can-fd-frame-support=false, can-frame-rx-behavior=CAN-20, can-frame-tx-behavior=CAN-20
        pdu CAN1_XNMm_ABM: length=8, minimum-delay=0.0, transmission-mode-true-timing=cyclic-timing=time-period=0.7, unused-bit-pattern=0
          mapping CAN1_SG_XNMm_ABM: i-signal-group=CAN1_SG_XNMm_ABM, start-position=0, transfer-property=PENDING
          signal CAN1_NM_ABM_Active_WU: start 12, 1 bit, big-endian, i-signal-type=PRIMITIVE, init-value=constant-reference=Init_CAN1_NM_ABM_Active_WU, base-type=uint8, implementation-data-type=uint8, transfer-property=PENDING
          signal CAN1_NM_ABM_CSB: start 11, 1 bit, big-endian, i-signal-type=PRIMITIVE, init-value=constant-reference=Init_CAN1_NM_ABM_CSB, base-type=uint8, implementation-data-type=uint8, transfer-property=PENDING
          signal CAN1_NM_ABM_ERROR_State: start 31, 4 bit, big-endian, i-signal-type=PRIMITIVE, init-value=constant-reference=Init_CAN1_NM_ABM_ERROR_State, base-type=uint8, implementation-data-type=uint8, transfer-property=PENDING
          signal CAN1_NM_ABM_Node_ID: start 7, 8 bit, big-endian, i-signal-type=PRIMITIVE, init-value=constant-reference=Init_CAN1_NM_ABM_Node_ID, base-type=uint8, implementation-data-type=uint8, transfer-property=PENDING
          signal CAN1_NM_ABM_PNI: start 14, 1 bit, big-endian, i-signal-type=PRIMITIVE, init-value=constant-reference=Init_CAN1_NM_ABM_PNI, base-type=uint8, implementation-data-type=uint8, transfer-property=PENDING
          signal CAN1_NM_ABM_Rpt_Msg_Req: start 8, 1 bit, big-endian, i-signal-type=PRIMITIVE, init-value=constant-reference=Init_CAN1_NM_ABM_Rpt_Msg_Req, base-type=uint8, implementation-data-type=uint8, transfer-property=PENDING
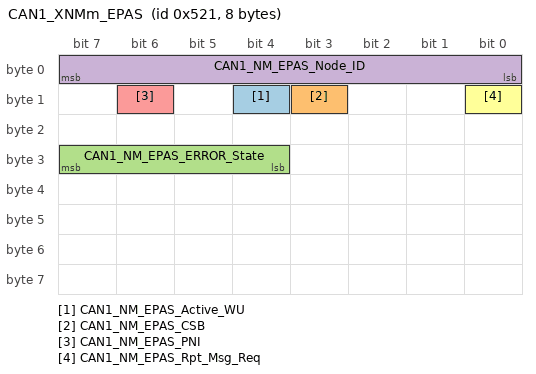
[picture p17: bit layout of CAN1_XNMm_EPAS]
      frame CAN1_XNMm_EPAS: id 0x521, frame-length=8, can-addressing-mode=STANDARD, can-fd-frame-support=false, can-frame-rx-behavior=CAN-20, can-frame-tx-behavior=CAN-20
        pdu CAN1_XNMm_EPAS: length=8, minimum-delay=0.0, transmission-mode-true-timing=cyclic-timing=time-period=0.7, unused-bit-pattern=0
          mapping CAN1_SG_XNMm_EPAS: i-signal-group=CAN1_SG_XNMm_EPAS, start-position=0, transfer-property=PENDING
          signal CAN1_NM_EPAS_Active_WU: start 12, 1 bit, big-endian, i-signal-type=PRIMITIVE, init-value=constant-reference=Init_CAN1_NM_EPAS_Active_WU, base-type=uint8, implementation-data-type=uint8, transfer-property=PENDING
          signal CAN1_NM_EPAS_CSB: start 11, 1 bit, big-endian, i-signal-type=PRIMITIVE, init-value=constant-reference=Init_CAN1_NM_EPAS_CSB, base-type=uint8, implementation-data-type=uint8, transfer-property=PENDING
          signal CAN1_NM_EPAS_ERROR_State: start 31, 4 bit, big-endian, i-signal-type=PRIMITIVE, init-value=constant-reference=Init_CAN1_NM_EPAS_ERROR_State, base-type=uint8, implementation-data-type=uint8, transfer-property=PENDING
          signal CAN1_NM_EPAS_Node_ID: start 7, 8 bit, big-endian, i-signal-type=PRIMITIVE, init-value=constant-reference=Init_CAN1_NM_EPAS_Node_ID, base-type=uint8, implementation-data-type=uint8, transfer-property=PENDING
          signal CAN1_NM_EPAS_PNI: start 14, 1 bit, big-endian, i-signal-type=PRIMITIVE, init-value=constant-reference=Init_CAN1_NM_EPAS_PNI, base-type=uint8, implementation-data-type=uint8, transfer-property=PENDING
          signal CAN1_NM_EPAS_Rpt_Msg_Req: start 8, 1 bit, big-endian, i-signal-type=PRIMITIVE, init-value=constant-reference=Init_CAN1_NM_EPAS_Rpt_Msg_Req, base-type=uint8, implementation-data-type=uint8, transfer-property=PENDING
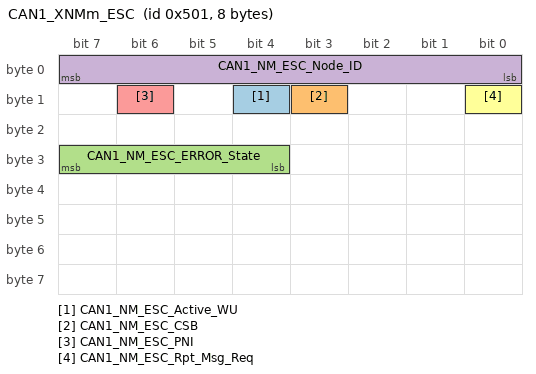
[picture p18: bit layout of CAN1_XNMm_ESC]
      frame CAN1_XNMm_ESC: id 0x501, frame-length=8, can-addressing-mode=STANDARD, can-fd-frame-support=false, can-frame-rx-behavior=CAN-20, can-frame-tx-behavior=CAN-20
        pdu CAN1_XNMm_ESC: length=8, minimum-delay=0.0, transmission-mode-true-timing=cyclic-timing=time-period=0.7, unused-bit-pattern=0
          mapping CAN1_SG_XNMm_ESC: i-signal-group=CAN1_SG_XNMm_ESC, start-position=0, transfer-property=PENDING
          signal CAN1_NM_ESC_Active_WU: start 12, 1 bit, big-endian, i-signal-type=PRIMITIVE, init-value=constant-reference=Init_CAN1_NM_ESC_Active_WU, base-type=uint8, implementation-data-type=uint8, transfer-property=PENDING
          signal CAN1_NM_ESC_CSB: start 11, 1 bit, big-endian, i-signal-type=PRIMITIVE, init-value=constant-reference=Init_CAN1_NM_ESC_CSB, base-type=uint8, implementation-data-type=uint8, transfer-property=PENDING
          signal CAN1_NM_ESC_ERROR_State: start 31, 4 bit, big-endian, i-signal-type=PRIMITIVE, init-value=constant-reference=Init_CAN1_NM_ESC_ERROR_State, base-type=uint8, implementation-data-type=uint8, transfer-property=PENDING
          signal CAN1_NM_ESC_Node_ID: start 7, 8 bit, big-endian, i-signal-type=PRIMITIVE, init-value=constant-reference=Init_CAN1_NM_ESC_Node_ID, base-type=uint8, implementation-data-type=uint8, transfer-property=PENDING
          signal CAN1_NM_ESC_PNI: start 14, 1 bit, big-endian, i-signal-type=PRIMITIVE, init-value=constant-reference=Init_CAN1_NM_ESC_PNI, base-type=uint8, implementation-data-type=uint8, transfer-property=PENDING
          signal CAN1_NM_ESC_Rpt_Msg_Req: start 8, 1 bit, big-endian, i-signal-type=PRIMITIVE, init-value=constant-reference=Init_CAN1_NM_ESC_Rpt_Msg_Req, base-type=uint8, implementation-data-type=uint8, transfer-property=PENDING
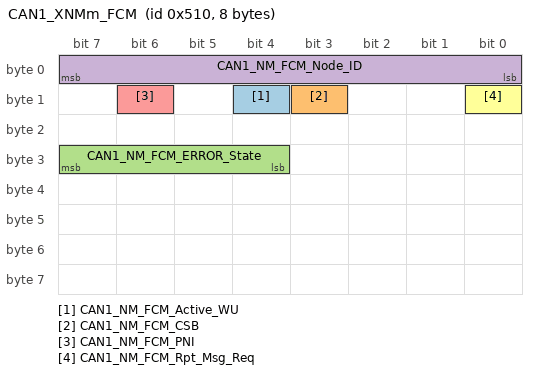
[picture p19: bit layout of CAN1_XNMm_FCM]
      frame CAN1_XNMm_FCM: id 0x510, frame-length=8, can-addressing-mode=STANDARD, can-fd-frame-support=false, can-frame-rx-behavior=CAN-20, can-frame-tx-behavior=CAN-20
        pdu CAN1_XNMm_FCM: length=8, minimum-delay=0.0, transmission-mode-true-timing=cyclic-timing=time-period=0.7, unused-bit-pattern=0
          mapping CAN1_SG_XNMm_FCM: i-signal-group=CAN1_SG_XNMm_FCM, start-position=0, transfer-property=PENDING
          signal CAN1_NM_FCM_Active_WU: start 12, 1 bit, big-endian, i-signal-type=PRIMITIVE, init-value=constant-reference=Init_CAN1_NM_FCM_Active_WU, base-type=uint8, implementation-data-type=uint8, transfer-property=PENDING
          signal CAN1_NM_FCM_CSB: start 11, 1 bit, big-endian, i-signal-type=PRIMITIVE, init-value=constant-reference=Init_CAN1_NM_FCM_CSB, base-type=uint8, implementation-data-type=uint8, transfer-property=PENDING
          signal CAN1_NM_FCM_ERROR_State: start 31, 4 bit, big-endian, i-signal-type=PRIMITIVE, init-value=constant-reference=Init_CAN1_NM_FCM_ERROR_State, base-type=uint8, implementation-data-type=uint8, transfer-property=PENDING
          signal CAN1_NM_FCM_Node_ID: start 7, 8 bit, big-endian, i-signal-type=PRIMITIVE, init-value=constant-reference=Init_CAN1_NM_FCM_Node_ID, base-type=uint8, implementation-data-type=uint8, transfer-property=PENDING
          signal CAN1_NM_FCM_PNI: start 14, 1 bit, big-endian, i-signal-type=PRIMITIVE, init-value=constant-reference=Init_CAN1_NM_FCM_PNI, base-type=uint8, implementation-data-type=uint8, transfer-property=PENDING
          signal CAN1_NM_FCM_Rpt_Msg_Req: start 8, 1 bit, big-endian, i-signal-type=PRIMITIVE, init-value=constant-reference=Init_CAN1_NM_FCM_Rpt_Msg_Req, base-type=uint8, implementation-data-type=uint8, transfer-property=PENDING
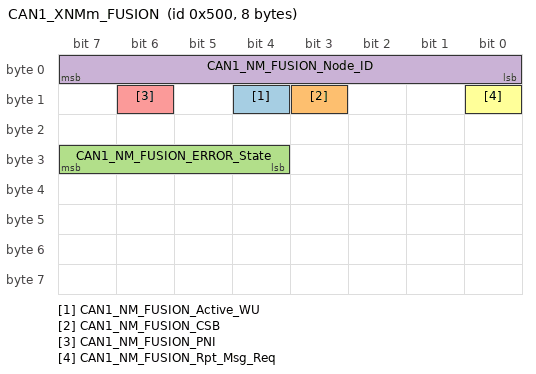
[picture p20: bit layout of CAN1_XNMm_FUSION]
      frame CAN1_XNMm_FUSION: id 0x500, frame-length=8, can-addressing-mode=STANDARD, can-fd-frame-support=false, can-frame-rx-behavior=CAN-20, can-frame-tx-behavior=CAN-20
        pdu CAN1_XNMm_FUSION: length=8, minimum-delay=0.0, transmission-mode-true-timing=cyclic-timing=time-period=0.7, unused-bit-pattern=0
          mapping CAN1_SG_XNMm_FUSION: i-signal-group=CAN1_SG_XNMm_FUSION, start-position=0, transfer-property=PENDING
          signal CAN1_NM_FUSION_Active_WU: start 12, 1 bit, big-endian, i-signal-type=PRIMITIVE, init-value=constant-reference=Init_CAN1_NM_FUSION_Active_WU, base-type=uint8, implementation-data-type=uint8, transfer-property=PENDING
          signal CAN1_NM_FUSION_CSB: start 11, 1 bit, big-endian, i-signal-type=PRIMITIVE, init-value=constant-reference=Init_CAN1_NM_FUSION_CSB, base-type=uint8, implementation-data-type=uint8, transfer-property=PENDING
          signal CAN1_NM_FUSION_ERROR_State: start 31, 4 bit, big-endian, i-signal-type=PRIMITIVE, init-value=constant-reference=Init_CAN1_NM_FUSION_ERROR_State, base-type=uint8, implementation-data-type=uint8, transfer-property=PENDING
          signal CAN1_NM_FUSION_Node_ID: start 7, 8 bit, big-endian, i-signal-type=PRIMITIVE, init-value=constant-reference=Init_CAN1_NM_FUSION_Node_ID, base-type=uint8, implementation-data-type=uint8, transfer-property=PENDING
          signal CAN1_NM_FUSION_PNI: start 14, 1 bit, big-endian, i-signal-type=PRIMITIVE, init-value=constant-reference=Init_CAN1_NM_FUSION_PNI, base-type=uint8, implementation-data-type=uint8, transfer-property=PENDING
          signal CAN1_NM_FUSION_Rpt_Msg_Req: start 8, 1 bit, big-endian, i-signal-type=PRIMITIVE, init-value=constant-reference=Init_CAN1_NM_FUSION_Rpt_Msg_Req, base-type=uint8, implementation-data-type=uint8, transfer-property=PENDING
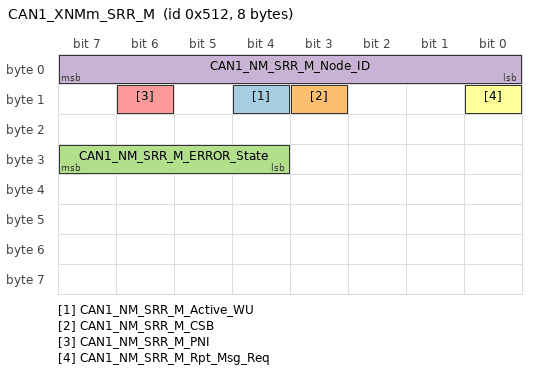
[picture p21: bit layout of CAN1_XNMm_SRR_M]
      frame CAN1_XNMm_SRR_M: id 0x512, frame-length=8, can-addressing-mode=STANDARD, can-fd-frame-support=false, can-frame-rx-behavior=CAN-20, can-frame-tx-behavior=CAN-20
        pdu CAN1_XNMm_SRR_M: length=8, minimum-delay=0.0, transmission-mode-true-timing=cyclic-timing=time-period=0.7, unused-bit-pattern=0
          mapping CAN1_SG_XNMm_SRR_M: i-signal-group=CAN1_SG_XNMm_SRR_M, start-position=0, transfer-property=PENDING
          signal CAN1_NM_SRR_M_Active_WU: start 12, 1 bit, big-endian, i-signal-type=PRIMITIVE, init-value=constant-reference=Init_CAN1_NM_SRR_M_Active_WU, base-type=uint8, implementation-data-type=uint8, transfer-property=PENDING
          signal CAN1_NM_SRR_M_CSB: start 11, 1 bit, big-endian, i-signal-type=PRIMITIVE, init-value=constant-reference=Init_CAN1_NM_SRR_M_CSB, base-type=uint8, implementation-data-type=uint8, transfer-property=PENDING
          signal CAN1_NM_SRR_M_ERROR_State: start 31, 4 bit, big-endian, i-signal-type=PRIMITIVE, init-value=constant-reference=Init_CAN1_NM_SRR_M_ERROR_State, base-type=uint8, implementation-data-type=uint8, transfer-property=PENDING
          signal CAN1_NM_SRR_M_Node_ID: start 7, 8 bit, big-endian, i-signal-type=PRIMITIVE, init-value=constant-reference=Init_CAN1_NM_SRR_M_Node_ID, base-type=uint8, implementation-data-type=uint8, transfer-property=PENDING
          signal CAN1_NM_SRR_M_PNI: start 14, 1 bit, big-endian, i-signal-type=PRIMITIVE, init-value=constant-reference=Init_CAN1_NM_SRR_M_PNI, base-type=uint8, implementation-data-type=uint8, transfer-property=PENDING
          signal CAN1_NM_SRR_M_Rpt_Msg_Req: start 8, 1 bit, big-endian, i-signal-type=PRIMITIVE, init-value=constant-reference=Init_CAN1_NM_SRR_M_Rpt_Msg_Req, base-type=uint8, implementation-data-type=uint8, transfer-property=PENDING
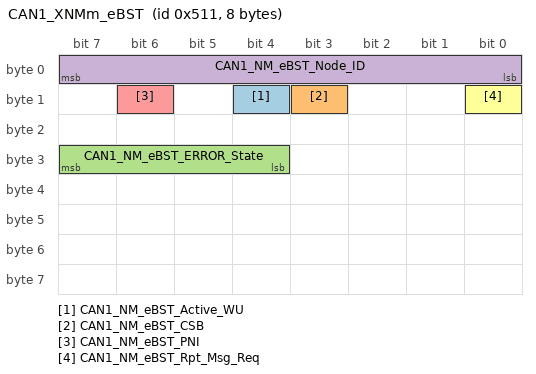
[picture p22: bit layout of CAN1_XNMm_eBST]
      frame CAN1_XNMm_eBST: id 0x511, frame-length=8, can-addressing-mode=STANDARD, can-fd-frame-support=false, can-frame-rx-behavior=CAN-20, can-frame-tx-behavior=CAN-20
        pdu CAN1_XNMm_eBST: length=8, minimum-delay=0.0, transmission-mode-true-timing=cyclic-timing=time-period=0.7, unused-bit-pattern=0
          mapping CAN1_SG_XNMm_eBST: i-signal-group=CAN1_SG_XNMm_eBST, start-position=0, transfer-property=PENDING
          signal CAN1_NM_eBST_Active_WU: start 12, 1 bit, big-endian, i-signal-type=PRIMITIVE, init-value=constant-reference=Init_CAN1_NM_eBST_Active_WU, base-type=uint8, implementation-data-type=uint8, transfer-property=PENDING
          signal CAN1_NM_eBST_CSB: start 11, 1 bit, big-endian, i-signal-type=PRIMITIVE, init-value=constant-reference=Init_CAN1_NM_eBST_CSB, base-type=uint8, implementation-data-type=uint8, transfer-property=PENDING
          signal CAN1_NM_eBST_ERROR_State: start 31, 4 bit, big-endian, i-signal-type=PRIMITIVE, init-value=constant-reference=Init_CAN1_NM_eBST_ERROR_State, base-type=uint8, implementation-data-type=uint8, transfer-property=PENDING
          signal CAN1_NM_eBST_Node_ID: start 7, 8 bit, big-endian, i-signal-type=PRIMITIVE, init-value=constant-reference=Init_CAN1_NM_eBST_Node_ID, base-type=uint8, implementation-data-type=uint8, transfer-property=PENDING
          signal CAN1_NM_eBST_PNI: start 14, 1 bit, big-endian, i-signal-type=PRIMITIVE, init-value=constant-reference=Init_CAN1_NM_eBST_PNI, base-type=uint8, implementation-data-type=uint8, transfer-property=PENDING
          signal CAN1_NM_eBST_Rpt_Msg_Req: start 8, 1 bit, big-endian, i-signal-type=PRIMITIVE, init-value=constant-reference=Init_CAN1_NM_eBST_Rpt_Msg_Req, base-type=uint8, implementation-data-type=uint8, transfer-property=PENDING
package /CAN1/ConstantSpecification
  445 x constant specification:
    Init_CAN1_AirBagFailCmd: value-spec=0
    Init_CAN1_Checksum_ABM1: value-spec=0
    Init_CAN1_CrashOutputSts: value-spec=0
    Init_CAN1_DriverSeatBeltCmd: value-spec=0
    Init_CAN1_LifeCount_ABM1: value-spec=0
    Init_CAN1_PABSwitchCmd: value-spec=0
    Init_CAN1_PsngrSeatBeltCmd: value-spec=0
    Init_CAN1_RCenterSeatBeltCmd: value-spec=0
    Init_CAN1_RDriverSeatBeltCmd: value-spec=0
    Init_CAN1_RPsngrSeatBeltCmd: value-spec=0
    Init_CAN1_TLHPsngrSeatBeltCmd: value-spec=0
    Init_CAN1_TRHPsngrSeatBeltCmd: value-spec=0
    Init_CAN1_SG_ABM1: value-spec=fields=[Init_CAN1_AirBagFailCmd, Init_CAN1_Checksum_ABM1, Init_CAN1_CrashOutputSts, Init_CAN1_DriverSeatBeltCmd, Init_CAN1_LifeCount_ABM1, Init_CAN1_PABSwitchCmd, Init_CAN1_PsngrSeatBeltCmd, Init_CAN1_RCenterSeatBeltCmd, Init_CAN1_RDriverSeatBeltCmd, Init_CAN1_RPsngrSeatBeltCmd, Init_CAN1_TLHPsngrSeatBeltCmd, Init_CAN1_TRHPsngrSeatBeltCmd]
    Init_CAN1_DriIntend: value-spec=0
    Init_CAN1_EPAS1_Checksum: value-spec=0
    Init_CAN1_EPAS1_LifeCount: value-spec=0
    Init_CAN1_EPS_AOI_Control: value-spec=0
    Init_CAN1_EPS_TOI_Fault: value-spec=0
    Init_CAN1_SG_EPAS1: value-spec=fields=[Init_CAN1_DriIntend, Init_CAN1_EPAS1_Checksum, Init_CAN1_EPAS1_LifeCount, Init_CAN1_EPS_AOI_Control, Init_CAN1_EPS_TOI_Fault]
    Init_CAN1_SAS_Angle: value-spec=9000
    Init_CAN1_SAS_CAL: value-spec=0
    Init_CAN1_SAS_CheckSum: value-spec=0
    Init_CAN1_SAS_MsgCount: value-spec=0
    Init_CAN1_SAS_Speed: value-spec=0
    Init_CAN1_SAS_Speed_Valid: value-spec=0
    Init_CAN1_SAS_V: value-spec=0
    Init_CAN1_SG_EPAS2: value-spec=fields=[Init_CAN1_SAS_Angle, Init_CAN1_SAS_CAL, Init_CAN1_SAS_CheckSum, Init_CAN1_SAS_MsgCount, Init_CAN1_SAS_Speed, Init_CAN1_SAS_Speed_Valid, Init_CAN1_SAS_V]
    Init_CAN1_DOA_Sta: value-spec=0
    Init_CAN1_EPB1_CS: value-spec=0
    Init_CAN1_EPB1_RC: value-spec=0
    Init_CAN1_EPBCarWashMode: value-spec=0
    Init_CAN1_EPBErrSta: value-spec=0
    Init_CAN1_EPBExtApplyAvail: value-spec=0
    Init_CAN1_EPBExtReleaseAvail: value-spec=0
    Init_CAN1_EPBMsg: value-spec=0
    Init_CAN1_EPBRLampSta: value-spec=0
    Init_CAN1_EPBSta: value-spec=0
    Init_CAN1_EPBStaL: value-spec=0
    Init_CAN1_EPBStaR: value-spec=0
    Init_CAN1_TakeOverReq: value-spec=0
    Init_CAN1_SG_EPB1: value-spec=fields=[Init_CAN1_DOA_Sta, Init_CAN1_EPB1_CS, Init_CAN1_EPB1_RC, Init_CAN1_EPBCarWashMode, Init_CAN1_EPBErrSta, Init_CAN1_EPBExtApplyAvail, Init_CAN1_EPBExtReleaseAvail, Init_CAN1_EPBMsg, Init_CAN1_EPBRLampSta, Init_CAN1_EPBSta, Init_CAN1_EPBStaL, Init_CAN1_EPBStaR, Init_CAN1_TakeOverReq]
    Init_CAN1_ESC1_CS: value-spec=0
    Init_CAN1_ESC1_RC: value-spec=0
    Init_CAN1_Fr_PTCS_Active: value-spec=0
    Init_CAN1_FrntAxlTrqReq_Drv: value-spec=10600
    Init_CAN1_RearAxlTrqReq_Drv: value-spec=10600
    Init_CAN1_Rr_PTCS_Active: value-spec=0
    Init_CAN1_VehSpeed: value-spec=0
    Init_CAN1_SG_ESC1: value-spec=fields=[Init_CAN1_ESC1_CS, Init_CAN1_ESC1_RC, Init_CAN1_Fr_PTCS_Active, Init_CAN1_FrntAxlTrqReq_Drv, Init_CAN1_RearAxlTrqReq_Drv, Init_CAN1_Rr_PTCS_Active, Init_CAN1_VehSpeed]
    Init_CAN1_F_WhlSpeed_CRC_8: value-spec=0
    Init_CAN1_F_WhlSpeed_Count: value-spec=0
    Init_CAN1_LF_PulseCount: value-spec=0
    Init_CAN1_LF_PulseCount_V: value-spec=0
    Init_CAN1_LF_RawWhlSpeed: value-spec=0
    Init_CAN1_LF_RawWhlSpeed_V: value-spec=0
    Init_CAN1_LF_WhlRotDir: value-spec=0
    Init_CAN1_RF_PulseCount: value-spec=0
    Init_CAN1_RF_PulseCount_V: value-spec=0
    Init_CAN1_RF_RawWhlSpeed: value-spec=0
    Init_CAN1_RF_RawWhlSpeed_V: value-spec=0
    Init_CAN1_RF_WhlRotDir: value-spec=0
    Init_CAN1_SG_ESC2: value-spec=fields=[Init_CAN1_F_WhlSpeed_CRC_8, Init_CAN1_F_WhlSpeed_Count, Init_CAN1_LF_PulseCount, Init_CAN1_LF_PulseCount_V, Init_CAN1_LF_RawWhlSpeed, Init_CAN1_LF_RawWhlSpeed_V, Init_CAN1_LF_WhlRotDir, Init_CAN1_RF_PulseCount, Init_CAN1_RF_PulseCount_V, Init_CAN1_RF_RawWhlSpeed, Init_CAN1_RF_RawWhlSpeed_V, Init_CAN1_RF_WhlRotDir]
    Init_CAN1_LR_PulseCount: value-spec=0
    Init_CAN1_LR_PulseCount_V: value-spec=0
    Init_CAN1_LR_RawWhlSpeed: value-spec=0
    Init_CAN1_LR_RawWhlSpeed_V: value-spec=0
    Init_CAN1_LR_WhlRotDir: value-spec=0
    Init_CAN1_RR_PulseCount: value-spec=0
    Init_CAN1_RR_PulseCount_V: value-spec=0
    Init_CAN1_RR_RawWhlSpeed: value-spec=0
    Init_CAN1_RR_RawWhlSpeed_V: value-spec=0
    Init_CAN1_RR_WhlRotDir: value-spec=0
    Init_CAN1_R_WhlSpeed_CRC_8: value-spec=0
    Init_CAN1_R_WhlSpeed_Count: value-spec=0
    Init_CAN1_SG_ESC3: value-spec=fields=[Init_CAN1_LR_PulseCount, Init_CAN1_LR_PulseCount_V, Init_CAN1_LR_RawWhlSpeed, Init_CAN1_LR_RawWhlSpeed_V, Init_CAN1_LR_WhlRotDir, Init_CAN1_RR_PulseCount, Init_CAN1_RR_PulseCount_V, Init_CAN1_RR_RawWhlSpeed, Init_CAN1_RR_RawWhlSpeed_V, Init_CAN1_RR_WhlRotDir, Init_CAN1_R_WhlSpeed_CRC_8, Init_CAN1_R_WhlSpeed_Count]
    Init_CAN1_ABS_Active: value-spec=0
    Init_CAN1_ABS_Failed: value-spec=0
    Init_CAN1_ABS_WnlmpSta: value-spec=0
    Init_CAN1_AVH_Active: value-spec=0
    Init_CAN1_AVH_Failed: value-spec=0
    Init_CAN1_Amber_WnlmpSta: value-spec=0
    Init_CAN1_BTCS_Active: value-spec=0
    Init_CAN1_EBD_Active: value-spec=0
    Init_CAN1_EBD_Failed: value-spec=0
    Init_CAN1_ESC_Active: value-spec=0
    Init_CAN1_ESC_BeepReq: value-spec=0
    Init_CAN1_ESC_Failed: value-spec=0
    Init_CAN1_ESC_OFF_Status: value-spec=0
    Init_CAN1_ESC_Off_lmpSta: value-spec=0
    Init_CAN1_ESC_WnlmpSta: value-spec=0
    Init_CAN1_ESS_Active: value-spec=0
    Init_CAN1_GRADE: value-spec=127
    Init_CAN1_HBB_Active: value-spec=0
    Init_CAN1_HBB_Failed: value-spec=0
    Init_CAN1_HDD_Active: value-spec=0
    Init_CAN1_HDD_Failed: value-spec=0
    Init_CAN1_HSA_Active: value-spec=0
    Init_CAN1_HSA_Failed: value-spec=0
    Init_CAN1_PBA_Active: value-spec=0
    Init_CAN1_PBA_Failed: value-spec=0
    Init_CAN1_Red_WnlmpSta: value-spec=0
    Init_CAN1_SystemVoltage: value-spec=0
    Init_CAN1_TCS_Active: value-spec=0
    Init_CAN1_TCS_Failed: value-spec=0
    Init_CAN1_SG_ESC4: value-spec=fields=[Init_CAN1_ABS_Active, Init_CAN1_ABS_Failed, Init_CAN1_ABS_WnlmpSta, Init_CAN1_AVH_Active, Init_CAN1_AVH_Failed, Init_CAN1_Amber_WnlmpSta, Init_CAN1_BTCS_Active, Init_CAN1_EBD_Active, Init_CAN1_EBD_Failed, Init_CAN1_ESC_Active, Init_CAN1_ESC_BeepReq, Init_CAN1_ESC_Failed, Init_CAN1_ESC_OFF_Status, Init_CAN1_ESC_Off_lmpSta, Init_CAN1_ESC_WnlmpSta, Init_CAN1_ESS_Active, Init_CAN1_GRADE, Init_CAN1_HBB_Active, Init_CAN1_HBB_Failed, Init_CAN1_HDD_Active, Init_CAN1_HDD_Failed, Init_CAN1_HSA_Active, Init_CAN1_HSA_Failed, Init_CAN1_PBA_Active, Init_CAN1_PBA_Failed, Init_CAN1_Red_WnlmpSta, Init_CAN1_SystemVoltage, Init_CAN1_TCS_Active, Init_CAN1_TCS_Failed]
    Init_CAN1_BrkSw_Sta: value-spec=0
    Init_CAN1_BrkSw_V: value-spec=0
    Init_CAN1_ESC5_CRC8: value-spec=0
    Init_CAN1_ESC5_RC: value-spec=0
    Init_CAN1_LatAccel: value-spec=127
    Init_CAN1_LatAccel_V: value-spec=0
    Init_CAN1_LongAccel: value-spec=127
    Init_CAN1_LongAccel_V: value-spec=0
    Init_CAN1_MCPressure: value-spec=97
    Init_CAN1_MCPressure_V: value-spec=0
    Init_CAN1_YawRate: value-spec=1000
    Init_CAN1_YawRate_V: value-spec=0
    Init_CAN1_SG_ESC5: value-spec=fields=[Init_CAN1_BrkSw_Sta, Init_CAN1_BrkSw_V, Init_CAN1_ESC5_CRC8, Init_CAN1_ESC5_RC, Init_CAN1_LatAccel, Init_CAN1_LatAccel_V, Init_CAN1_LongAccel, Init_CAN1_LongAccel_V, Init_CAN1_MCPressure, Init_CAN1_MCPressure_V, Init_CAN1_YawRate, Init_CAN1_YawRate_V]
    Init_CAN1_ACCAvail: value-spec=0
    Init_CAN1_AEBAvail: value-spec=0
    Init_CAN1_ActBrkLamp_Sta: value-spec=0
    Init_CAN1_BrkDiscTempSta: value-spec=0
    Init_CAN1_DecErrSta: value-spec=0
    Init_CAN1_ESC6_CS: value-spec=0
    Init_CAN1_ESC6_RC: value-spec=0
    Init_CAN1_ESC_ADAS_Sta: value-spec=0
    Init_CAN1_ESC_APS_Sta: value-spec=0
    Init_CAN1_ESC_Standstill: value-spec=0
    Init_CAN1_Meter_Ind_VehSpeed: value-spec=0
    Init_CAN1_SG_ESC6: value-spec=fields=[Init_CAN1_ACCAvail, Init_CAN1_AEBAvail, Init_CAN1_ActBrkLamp_Sta, Init_CAN1_BrkDiscTempSta, Init_CAN1_DecErrSta, Init_CAN1_ESC6_CS, Init_CAN1_ESC6_RC, Init_CAN1_ESC_ADAS_Sta, Init_CAN1_ESC_APS_Sta, Init_CAN1_ESC_Standstill, Init_CAN1_Meter_Ind_VehSpeed]
    Init_CAN1_BrkPedalPos: value-spec=0
    Init_CAN1_BrkPedalPos_Sta: value-spec=0
    Init_CAN1_ESC7_CS: value-spec=0
    Init_CAN1_ESC7_RC: value-spec=0
    Init_CAN1_Fr_RBC_Active: value-spec=0
    Init_CAN1_FrntAxlTrqReq_Brk: value-spec=10600
    Init_CAN1_RDC_Active: value-spec=0
    Init_CAN1_RearAxlTrqReq_Brk: value-spec=10600
    Init_CAN1_Rr_RBC_Active: value-spec=0
    Init_CAN1_SG_ESC7: value-spec=fields=[Init_CAN1_BrkPedalPos, Init_CAN1_BrkPedalPos_Sta, Init_CAN1_ESC7_CS, Init_CAN1_ESC7_RC, Init_CAN1_Fr_RBC_Active, Init_CAN1_FrntAxlTrqReq_Brk, Init_CAN1_RDC_Active, Init_CAN1_RearAxlTrqReq_Brk, Init_CAN1_Rr_RBC_Active]
    Init_CAN1_ACC_ComfortBandLower: value-spec=0
    Init_CAN1_ACC_ComfortBandUpper: value-spec=0
    Init_CAN1_ACC_JerkLowerLimit: value-spec=0
    Init_CAN1_ACC_JerkUpperLimit: value-spec=0
    Init_CAN1_ACC_RequiredAccel: value-spec=0
    Init_CAN1_ACC_VehHoldReq: value-spec=0
    Init_CAN1_ADAS_AEBReq: value-spec=0
    Init_CAN1_ADAS_DBSReq: value-spec=0
    Init_CAN1_ADAS_FaultSta: value-spec=0
    Init_CAN1_AEB_VehHoldReq: value-spec=0
    Init_CAN1_FCM2_Checksum: value-spec=0
    Init_CAN1_FCM2_LifeCount: value-spec=0
    Init_CAN1_SG_FCM2: value-spec=fields=[Init_CAN1_ACC_ComfortBandLower, Init_CAN1_ACC_ComfortBandUpper, Init_CAN1_ACC_JerkLowerLimit, Init_CAN1_ACC_JerkUpperLimit, Init_CAN1_ACC_RequiredAccel, Init_CAN1_ACC_VehHoldReq, Init_CAN1_ADAS_AEBReq, Init_CAN1_ADAS_DBSReq, Init_CAN1_ADAS_FaultSta, Init_CAN1_AEB_VehHoldReq, Init_CAN1_FCM2_Checksum, Init_CAN1_FCM2_LifeCount]
    Init_CAN1_ACC_ObjDist: value-spec=2046
    Init_CAN1_ACC_ObjRelSpd: value-spec=0
    Init_CAN1_ADAS_ForceIdle: value-spec=0
    Init_CAN1_ADAS_ShftPosnReq: value-spec=0
    Init_CAN1_ADAS_ShftPosnReq_A: value-spec=0
    Init_CAN1_ADAS_VehSpdLim: value-spec=0
    Init_CAN1_FCM3_Checksum: value-spec=0
    Init_CAN1_FCM3_LifeCount: value-spec=0
    Init_CAN1_SG_FCM3: value-spec=fields=[Init_CAN1_ACC_ObjDist, Init_CAN1_ACC_ObjRelSpd, Init_CAN1_ADAS_ForceIdle, Init_CAN1_ADAS_ShftPosnReq, Init_CAN1_ADAS_ShftPosnReq_A, Init_CAN1_ADAS_VehSpdLim, Init_CAN1_FCM3_Checksum, Init_CAN1_FCM3_LifeCount]
    Init_CAN1_ACCSetSpeed: value-spec=0
    Init_CAN1_ACCSetSpeed_Disp: value-spec=0
    Init_CAN1_ACC_ObjDstLvl: value-spec=0
    Init_CAN1_ACC_TakeoverReq: value-spec=0
    Init_CAN1_ADAS_ACC_Sta: value-spec=0
    Init_CAN1_ADAS_AEB_Sta: value-spec=0
    Init_CAN1_ADAS_CAM_SpdLim: value-spec=0
    Init_CAN1_ADAS_FCW_Sta: value-spec=0
    Init_CAN1_ADAS_FltWrnReq: value-spec=0
    Init_CAN1_ADAS_LDW_Sta: value-spec=0
    Init_CAN1_ADAS_SLIF_SpdLim: value-spec=0
    Init_CAN1_ADAS_WarningMsg: value-spec=0
    Init_CAN1_FCM4_Checksum: value-spec=0
    Init_CAN1_ForceLowBeam: value-spec=0
    Init_CAN1_HazardWarningReq: value-spec=0
    Init_CAN1_LeftTurnLightReq: value-spec=0
    Init_CAN1_RightTurnLightReq: value-spec=0
    Init_CAN1_Target_Type: value-spec=0
    Init_CAN1_TimeGapLevel: value-spec=0
    Init_CAN1_SG_FCM4: value-spec=fields=[Init_CAN1_ACCSetSpeed, Init_CAN1_ACCSetSpeed_Disp, Init_CAN1_ACC_ObjDstLvl, Init_CAN1_ACC_TakeoverReq, Init_CAN1_ADAS_ACC_Sta, Init_CAN1_ADAS_AEB_Sta, Init_CAN1_ADAS_CAM_SpdLim, Init_CAN1_ADAS_FCW_Sta, Init_CAN1_ADAS_FltWrnReq, Init_CAN1_ADAS_LDW_Sta, Init_CAN1_ADAS_SLIF_SpdLim, Init_CAN1_ADAS_WarningMsg, Init_CAN1_FCM4_Checksum, Init_CAN1_ForceLowBeam, Init_CAN1_HazardWarningReq, Init_CAN1_LeftTurnLightReq, Init_CAN1_RightTurnLightReq, Init_CAN1_Target_Type, Init_CAN1_TimeGapLevel]
    Init_CAN1_APS_Angle_Target: value-spec=0
    Init_CAN1_APS_Rq_EPAS_Ctrl: value-spec=0
    Init_CAN1_APS_Sta_System: value-spec=0
    Init_CAN1_APS_V_Rq_EPAS_Ctrl: value-spec=0
    Init_CAN1_SG_FD_APS1: value-spec=fields=[Init_CAN1_APS_Angle_Target, Init_CAN1_APS_Rq_EPAS_Ctrl, Init_CAN1_APS_Sta_System, Init_CAN1_APS_V_Rq_EPAS_Ctrl]
    Init_CAN1_APS_D_FLL: value-spec=0
    Init_CAN1_APS_D_FLR: value-spec=0
    Init_CAN1_APS_D_RLL: value-spec=0
    Init_CAN1_APS_D_RLR: value-spec=0
    Init_CAN1_APS_ExitCondition: value-spec=0
    Init_CAN1_APS_HW_Ver: value-spec=0
    Init_CAN1_APS_Progress_PCT: value-spec=0
    Init_CAN1_APS_RQ_Display: value-spec=0
    Init_CAN1_APS_SW_Ver: value-spec=0
    Init_CAN1_PAS_A_FCL: value-spec=0
    Init_CAN1_PAS_A_FCR: value-spec=0
    Init_CAN1_PAS_A_FML: value-spec=0
    Init_CAN1_PAS_A_FMR: value-spec=0
    Init_CAN1_PAS_A_RCL: value-spec=0
    Init_CAN1_PAS_A_RCR: value-spec=0
    Init_CAN1_PAS_A_RML: value-spec=0
    Init_CAN1_PAS_A_RMR: value-spec=0
    Init_CAN1_PAS_Chime: value-spec=0
    Init_CAN1_PAS_D_FCL: value-spec=0
    Init_CAN1_PAS_D_FCR: value-spec=0
    Init_CAN1_PAS_D_FML: value-spec=0
    Init_CAN1_PAS_D_FMR: value-spec=0
    Init_CAN1_PAS_D_RCL: value-spec=0
    Init_CAN1_PAS_D_RCR: value-spec=0
    Init_CAN1_PAS_D_RML: value-spec=0
    Init_CAN1_PAS_D_RMR: value-spec=0
    Init_CAN1_PAS_Mod_Operation: value-spec=0
    Init_CAN1_PAS_SNSR_Layout: value-spec=0
    Init_CAN1_PAS_Sta_F_Sys: value-spec=0
    Init_CAN1_USS_Sta_FCL: value-spec=0
    Init_CAN1_USS_Sta_FCR: value-spec=0
    Init_CAN1_USS_Sta_FLL: value-spec=0
    Init_CAN1_USS_Sta_FLR: value-spec=0
    Init_CAN1_USS_Sta_FML: value-spec=0
    Init_CAN1_USS_Sta_FMR: value-spec=0
    Init_CAN1_USS_Sta_RCL: value-spec=0
    Init_CAN1_USS_Sta_RCR: value-spec=0
    Init_CAN1_USS_Sta_RLL: value-spec=0
    Init_CAN1_USS_Sta_RLR: value-spec=0
    Init_CAN1_USS_Sta_RML: value-spec=0
    Init_CAN1_USS_Sta_RMR: value-spec=0
    Init_CAN1_SG_FD_APS2: value-spec=fields=[Init_CAN1_APS_D_FLL, Init_CAN1_APS_D_FLR, Init_CAN1_APS_D_RLL, Init_CAN1_APS_D_RLR, Init_CAN1_APS_ExitCondition, Init_CAN1_APS_HW_Ver, Init_CAN1_APS_Progress_PCT, Init_CAN1_APS_RQ_Display, Init_CAN1_APS_SW_Ver, Init_CAN1_PAS_A_FCL, Init_CAN1_PAS_A_FCR, Init_CAN1_PAS_A_FML, Init_CAN1_PAS_A_FMR, Init_CAN1_PAS_A_RCL, Init_CAN1_PAS_A_RCR, Init_CAN1_PAS_A_RML, Init_CAN1_PAS_A_RMR, Init_CAN1_PAS_Chime, Init_CAN1_PAS_D_FCL, Init_CAN1_PAS_D_FCR, Init_CAN1_PAS_D_FML, Init_CAN1_PAS_D_FMR, Init_CAN1_PAS_D_RCL, Init_CAN1_PAS_D_RCR, Init_CAN1_PAS_D_RML, Init_CAN1_PAS_D_RMR, Init_CAN1_PAS_Mod_Operation, Init_CAN1_PAS_SNSR_Layout, Init_CAN1_PAS_Sta_F_Sys, Init_CAN1_USS_Sta_FCL, Init_CAN1_USS_Sta_FCR, Init_CAN1_USS_Sta_FLL, Init_CAN1_USS_Sta_FLR, Init_CAN1_USS_Sta_FML, Init_CAN1_USS_Sta_FMR, Init_CAN1_USS_Sta_RCL, Init_CAN1_USS_Sta_RCR, Init_CAN1_USS_Sta_RLL, Init_CAN1_USS_Sta_RLR, Init_CAN1_USS_Sta_RML, Init_CAN1_USS_Sta_RMR]
    Init_CAN1_APS3_LifeCount: value-spec=0
    Init_CAN1_APS3_checksum: value-spec=0
    Init_CAN1_APSOpenPTG: value-spec=0
    Init_CAN1_APS_DecReq: value-spec=0
    Init_CAN1_APS_DecReq_A: value-spec=0
    Init_CAN1_APS_Req: value-spec=0
    Init_CAN1_CAAS_Sta: value-spec=0
    Init_CAN1_SPTGDet: value-spec=0
    Init_CAN1_SPTG_Sta: value-spec=0
    Init_CAN1_SG_FD_APS3: value-spec=fields=[Init_CAN1_APS3_LifeCount, Init_CAN1_APS3_checksum, Init_CAN1_APSOpenPTG, Init_CAN1_APS_DecReq, Init_CAN1_APS_DecReq_A, Init_CAN1_APS_Req, Init_CAN1_CAAS_Sta, Init_CAN1_SPTGDet, Init_CAN1_SPTG_Sta]
    Init_CAN1_AllDoorSW: value-spec=0
    Init_CAN1_AntiTheftSeatFold: value-spec=0
    Init_CAN1_AntitheftSta: value-spec=0
    Init_CAN1_BCM_Buzzer_Req: value-spec=0
    Init_CAN1_BCM_DoorLock_Sta: value-spec=0
    Init_CAN1_BrakeLamp: value-spec=0
    Init_CAN1_CTDCtrl: value-spec=0
    Init_CAN1_CTDLockSW: value-spec=0
    Init_CAN1_CTDUnlockSW: value-spec=0
    Init_CAN1_CrashDetd: value-spec=0
    Init_CAN1_Dimmer: value-spec=0
    Init_CAN1_DimmerEN: value-spec=0
    Init_CAN1_DoorLockIND: value-spec=0
    Init_CAN1_DrDoorSW: value-spec=0
    Init_CAN1_Fr_ChargingDoorCtrl: value-spec=0
    Init_CAN1_Fr_FogLamp: value-spec=0
    Init_CAN1_Fr_Wiper_H: value-spec=0
    Init_CAN1_Fr_Wiper_L: value-spec=0
    Init_CAN1_H_Beam: value-spec=0
    Init_CAN1_HazardSW: value-spec=0
    Init_CAN1_HoodSW: value-spec=0
    Init_CAN1_HornCtrl: value-spec=0
    Init_CAN1_LBSD: value-spec=0
    Init_CAN1_LDRL: value-spec=0
    Init_CAN1_LTurnLP: value-spec=0
    Init_CAN1_L_APM_WdwEnable: value-spec=0
    Init_CAN1_L_Beam: value-spec=0
    Init_CAN1_LockSetting: value-spec=0
    Init_CAN1_MirrorCtrl: value-spec=0
    Init_CAN1_MirrorDefog: value-spec=0
    Init_CAN1_PosLamp: value-spec=0
    Init_CAN1_PsDoorSW: value-spec=0
    Init_CAN1_RBSD: value-spec=0
    Init_CAN1_RDRL: value-spec=0
    Init_CAN1_RLDoorSW: value-spec=0
    Init_CAN1_RRDoorSW: value-spec=0
    Init_CAN1_RTurnLP: value-spec=0
    Init_CAN1_ReverseLamp: value-spec=0
    Init_CAN1_RoomLampH: value-spec=0
    Init_CAN1_RoomLampL: value-spec=0
    Init_CAN1_Rr_ChargingDoorCtrl: value-spec=0
    Init_CAN1_Rr_Defog: value-spec=0
    Init_CAN1_Rr_FogLamp: value-spec=0
    Init_CAN1_Rr_Wiper: value-spec=0
    Init_CAN1_TailgateHDSW: value-spec=0
    Init_CAN1_TailgateRemote: value-spec=0
    Init_CAN1_Tailgate_SW: value-spec=0
    Init_CAN1_TrunkRel: value-spec=0
    Init_CAN1_WasherCtrl: value-spec=0
    Init_CAN1_WiperFixMode: value-spec=0
    Init_CAN1_SG_FD_BCM1: value-spec=fields=[Init_CAN1_AllDoorSW, Init_CAN1_AntiTheftSeatFold, Init_CAN1_AntitheftSta, Init_CAN1_BCM_Buzzer_Req, Init_CAN1_BCM_DoorLock_Sta, Init_CAN1_BrakeLamp, Init_CAN1_CTDCtrl, Init_CAN1_CTDLockSW, Init_CAN1_CTDUnlockSW, Init_CAN1_CrashDetd, Init_CAN1_Dimmer, Init_CAN1_DimmerEN, Init_CAN1_DoorLockIND, Init_CAN1_DrDoorSW, Init_CAN1_Fr_ChargingDoorCtrl, Init_CAN1_Fr_FogLamp, Init_CAN1_Fr_Wiper_H, Init_CAN1_Fr_Wiper_L, Init_CAN1_H_Beam, Init_CAN1_HazardSW, Init_CAN1_HoodSW, Init_CAN1_HornCtrl, Init_CAN1_LBSD, Init_CAN1_LDRL, Init_CAN1_LTurnLP, Init_CAN1_L_APM_WdwEnable, Init_CAN1_L_Beam, Init_CAN1_LockSetting, Init_CAN1_MirrorCtrl, Init_CAN1_MirrorDefog, Init_CAN1_PosLamp, Init_CAN1_PsDoorSW, Init_CAN1_RBSD, Init_CAN1_RDRL, Init_CAN1_RLDoorSW, Init_CAN1_RRDoorSW, Init_CAN1_RTurnLP, Init_CAN1_ReverseLamp, Init_CAN1_RoomLampH, Init_CAN1_RoomLampL, Init_CAN1_Rr_ChargingDoorCtrl, Init_CAN1_Rr_Defog, Init_CAN1_Rr_FogLamp, Init_CAN1_Rr_Wiper, Init_CAN1_TailgateHDSW, Init_CAN1_TailgateRemote, Init_CAN1_Tailgate_SW, Init_CAN1_TrunkRel, Init_CAN1_WasherCtrl, Init_CAN1_WiperFixMode]
    Init_CAN1_BatteryMode: value-spec=0
    Init_CAN1_CCU_ACLampSts: value-spec=0
    Init_CAN1_CCU_ACMaxLampSts: value-spec=0
    Init_CAN1_CCU_AutoLampSts: value-spec=0
    Init_CAN1_CCU_AutoMidLampSts: value-spec=0
    Init_CAN1_CCU_Dispaly_Request: value-spec=0
    Init_CAN1_CCU_EcoSts: value-spec=0
    Init_CAN1_CCU_FrtOnOffLampSts: value-spec=0
    Init_CAN1_CCU_HEATMaxLampSts: value-spec=0
    Init_CAN1_CCU_RrOnOffLampSts: value-spec=0
    Init_CAN1_CCU_SyncLampSts: value-spec=0
    Init_CAN1_CabinMode: value-spec=0
    Init_CAN1_EDriveMode: value-spec=0
    Init_CAN1_FD_AGS_Cmd: value-spec=0
    Init_CAN1_FD_RecyAuto_Cmd: value-spec=0
    Init_CAN1_Fr_Coolantflow: value-spec=0
    Init_CAN1_Fr_Coolanttemp: value-spec=40
    Init_CAN1_HPThermalRecoveryReq: value-spec=0
    Init_CAN1_Rr_Coolantflow: value-spec=0
    Init_CAN1_Rr_Coolanttemp: value-spec=40
    Init_CAN1_sigAirIntenZon1St: value-spec=0
    Init_CAN1_sigAirIntenZon3St: value-spec=0
    Init_CAN1_sigAmbAirT: value-spec=0
    Init_CAN1_sigCbnAirT: value-spec=0
    Init_CAN1_sigCbnPTCPwrAct: value-spec=0
    Init_CAN1_sigCbnSolarLeft: value-spec=253
    Init_CAN1_sigCbnSolarRight: value-spec=253
    Init_CAN1_sigClmtCmprPwrAct: value-spec=0
    Init_CAN1_sigClntTHvBattOut: value-spec=120
    Init_CAN1_sigDfrstSt: value-spec=0
    Init_CAN1_sigHvacSt: value-spec=0
    Init_CAN1_sigRecircSt: value-spec=0
    Init_CAN1_sigSetTempZon{1..3}St: value-spec=0
    Init_CAN1_sigWindDirZon1St: value-spec=0
    Init_CAN1_sigWindDirZon3St: value-spec=0
    Init_CAN1_SG_FD_THCM1: value-spec=fields=[Init_CAN1_BatteryMode, Init_CAN1_CCU_ACLampSts, Init_CAN1_CCU_ACMaxLampSts, Init_CAN1_CCU_AutoLampSts, Init_CAN1_CCU_AutoMidLampSts, Init_CAN1_CCU_Dispaly_Request, Init_CAN1_CCU_EcoSts, Init_CAN1_CCU_FrtOnOffLampSts, Init_CAN1_CCU_HEATMaxLampSts, Init_CAN1_CCU_RrOnOffLampSts, Init_CAN1_CCU_SyncLampSts, Init_CAN1_CabinMode, Init_CAN1_EDriveMode, Init_CAN1_FD_AGS_Cmd, Init_CAN1_FD_RecyAuto_Cmd, Init_CAN1_Fr_Coolantflow, Init_CAN1_Fr_Coolanttemp, Init_CAN1_HPThermalRecoveryReq, Init_CAN1_Rr_Coolantflow, Init_CAN1_Rr_Coolanttemp, Init_CAN1_sigAirIntenZon1St, Init_CAN1_sigAirIntenZon3St, Init_CAN1_sigAmbAirT, Init_CAN1_sigCbnAirT, Init_CAN1_sigCbnPTCPwrAct, Init_CAN1_sigCbnSolarLeft, Init_CAN1_sigCbnSolarRight, Init_CAN1_sigClmtCmprPwrAct, Init_CAN1_sigClntTHvBattOut, Init_CAN1_sigDfrstSt, Init_CAN1_sigHvacSt, Init_CAN1_sigRecircSt, Init_CAN1_sigSetTempZon1St, Init_CAN1_sigSetTempZon2St, Init_CAN1_sigSetTempZon3St, Init_CAN1_sigWindDirZon1St, Init_CAN1_sigWindDirZon3St]
    Init_CAN1_CC_Crl_Sta: value-spec=0
    Init_CAN1_HVPwrSta: value-spec=0
    Init_CAN1_LVPwrSta: value-spec=0
    Init_CAN1_MSA_Crl_Sta: value-spec=0
    Init_CAN1_P_Button_Sta: value-spec=0
    Init_CAN1_PrkReq: value-spec=0
    Init_CAN1_PrkReqValid: value-spec=0
    Init_CAN1_PwrSta: value-spec=0
    Init_CAN1_ShiftGearPosn: value-spec=0
    Init_CAN1_XWDMode: value-spec=0
    Init_CAN1_SG_FD_VCU1: value-spec=fields=[Init_CAN1_CC_Crl_Sta, Init_CAN1_HVPwrSta, Init_CAN1_LVPwrSta, Init_CAN1_MSA_Crl_Sta, Init_CAN1_P_Button_Sta, Init_CAN1_PrkReq, Init_CAN1_PrkReqValid, Init_CAN1_PwrSta, Init_CAN1_ShiftGearPosn, Init_CAN1_XWDMode]
    Init_CAN1_ACC_CtrlAvail: value-spec=0
    Init_CAN1_AccPedal_Override: value-spec=0
    Init_CAN1_ActAPSPosn: value-spec=0
    Init_CAN1_CS_VCU2_CAN1: value-spec=0
    Init_CAN1_DriverTq: value-spec=4300
    Init_CAN1_Fr_DriverTq: value-spec=10600
    Init_CAN1_RC_VCU2_CAN1: value-spec=0
    Init_CAN1_Rr_DriverTq: value-spec=10600
    Init_CAN1_VehActPwr: value-spec=600000
    Init_CAN1_SG_FD_VCU2: value-spec=fields=[Init_CAN1_ACC_CtrlAvail, Init_CAN1_AccPedal_Override, Init_CAN1_ActAPSPosn, Init_CAN1_CS_VCU2_CAN1, Init_CAN1_DriverTq, Init_CAN1_Fr_DriverTq, Init_CAN1_RC_VCU2_CAN1, Init_CAN1_Rr_DriverTq, Init_CAN1_VehActPwr]
    Init_CAN1_CS_VCU3_CAN1: value-spec=0
    Init_CAN1_EquivAccPedalSWSta: value-spec=0
    Init_CAN1_Fr_EDUAvailBrkRgnTq: value-spec=10600
    Init_CAN1_Fr_EDUAvailBrkRgnTqValid: value-spec=0
    Init_CAN1_Fr_EDURealARgnTq: value-spec=5300
    Init_CAN1_Fr_EDURealDrvOrBRgnTq: value-spec=10600
    Init_CAN1_Fr_EDUSpd: value-spec=2000
    Init_CAN1_Fr_EDUSpdValid: value-spec=0
    Init_CAN1_Fr_RgnDecrSta: value-spec=0
    Init_CAN1_Fr_RgnPermSta: value-spec=0
    Init_CAN1_PTCS_PermSta: value-spec=0
    Init_CAN1_RC_VCU3_CAN1: value-spec=0
    Init_CAN1_RgnAbnorSta: value-spec=0
    Init_CAN1_Rr_EDUAvailBrkRgnTq: value-spec=10600
    Init_CAN1_Rr_EDUAvailBrkRgnTqValid: value-spec=0
    Init_CAN1_Rr_EDURealARgnTq: value-spec=5300
    Init_CAN1_Rr_EDURealDrvOrBRgnTq: value-spec=10600
    Init_CAN1_Rr_EDUSpd: value-spec=2000
    Init_CAN1_Rr_EDUSpdValid: value-spec=0
    Init_CAN1_Rr_RgnDecrSta: value-spec=0
    Init_CAN1_Rr_RgnPermSta: value-spec=0
    Init_CAN1_SG_FD_VCU3: value-spec=fields=[Init_CAN1_CS_VCU3_CAN1, Init_CAN1_EquivAccPedalSWSta, Init_CAN1_Fr_EDUAvailBrkRgnTq, Init_CAN1_Fr_EDUAvailBrkRgnTqValid, Init_CAN1_Fr_EDURealARgnTq, Init_CAN1_Fr_EDURealDrvOrBRgnTq, Init_CAN1_Fr_EDUSpd, Init_CAN1_Fr_EDUSpdValid, Init_CAN1_Fr_RgnDecrSta, Init_CAN1_Fr_RgnPermSta, Init_CAN1_PTCS_PermSta, Init_CAN1_RC_VCU3_CAN1, Init_CAN1_RgnAbnorSta, Init_CAN1_Rr_EDUAvailBrkRgnTq, Init_CAN1_Rr_EDUAvailBrkRgnTqValid, Init_CAN1_Rr_EDURealARgnTq, Init_CAN1_Rr_EDURealDrvOrBRgnTq, Init_CAN1_Rr_EDUSpd, Init_CAN1_Rr_EDUSpdValid, Init_CAN1_Rr_RgnDecrSta, Init_CAN1_Rr_RgnPermSta]
    Init_CAN1_Eng_AGSCloseSta: value-spec=0
    Init_CAN1_Eng_ActvDmpDisabSta: value-spec=0
    Init_CAN1_Eng_CoastDwSta: value-spec=0
    Init_CAN1_Eng_PwrLockSta: value-spec=0
    Init_CAN1_VehMalfunLevel: value-spec=0
    Init_CAN1_SG_FD_VCU4: value-spec=fields=[Init_CAN1_Eng_AGSCloseSta, Init_CAN1_Eng_ActvDmpDisabSta, Init_CAN1_Eng_CoastDwSta, Init_CAN1_Eng_PwrLockSta, Init_CAN1_VehMalfunLevel]
    Init_CAN1_SRR1_Chksum: value-spec=0
    Init_CAN1_SRR1_LifeCount: value-spec=0
    Init_CAN1_SRR_BSD_Mute: value-spec=0
    Init_CAN1_SRR_BSD_SoundL: value-spec=0
    Init_CAN1_SRR_BSD_SoundR: value-spec=0
    Init_CAN1_SRR_BSD_Sta: value-spec=0
    Init_CAN1_SRR_BSD_WarnL: value-spec=0
    Init_CAN1_SRR_BSD_WarnR: value-spec=0
    Init_CAN1_SRR_FltWrnReq: value-spec=0
    Init_CAN1_SRR_ODA_Mute: value-spec=0
    Init_CAN1_SRR_ODA_SoundL: value-spec=0
    Init_CAN1_SRR_ODA_SoundR: value-spec=0
    Init_CAN1_SRR_ODA_Sta: value-spec=0
    Init_CAN1_SRR_ODA_WarnL: value-spec=0
    Init_CAN1_SRR_ODA_WarnR: value-spec=0
    Init_CAN1_SRR_RCTA_Sta: value-spec=0
    Init_CAN1_SRR_RCTA_WarnL: value-spec=0
    Init_CAN1_SRR_RCTA_WarnR: value-spec=0
    Init_CAN1_SG_SRR1: value-spec=fields=[Init_CAN1_SRR1_Chksum, Init_CAN1_SRR1_LifeCount, Init_CAN1_SRR_BSD_Mute, Init_CAN1_SRR_BSD_SoundL, Init_CAN1_SRR_BSD_SoundR, Init_CAN1_SRR_BSD_Sta, Init_CAN1_SRR_BSD_WarnL, Init_CAN1_SRR_BSD_WarnR, Init_CAN1_SRR_FltWrnReq, Init_CAN1_SRR_ODA_Mute, Init_CAN1_SRR_ODA_SoundL, Init_CAN1_SRR_ODA_SoundR, Init_CAN1_SRR_ODA_Sta, Init_CAN1_SRR_ODA_WarnL, Init_CAN1_SRR_ODA_WarnR, Init_CAN1_SRR_RCTA_Sta, Init_CAN1_SRR_RCTA_WarnL, Init_CAN1_SRR_RCTA_WarnR]
    Init_CAN1_NM_ABM_Active_WU: value-spec=0
    Init_CAN1_NM_ABM_CSB: value-spec=0
    Init_CAN1_NM_ABM_ERROR_State: value-spec=0
    Init_CAN1_NM_ABM_Node_ID: value-spec=0
    Init_CAN1_NM_ABM_PNI: value-spec=0
    Init_CAN1_NM_ABM_Rpt_Msg_Req: value-spec=0
    Init_CAN1_SG_XNMm_ABM: value-spec=fields=[Init_CAN1_NM_ABM_Active_WU, Init_CAN1_NM_ABM_CSB, Init_CAN1_NM_ABM_ERROR_State, Init_CAN1_NM_ABM_Node_ID, Init_CAN1_NM_ABM_PNI, Init_CAN1_NM_ABM_Rpt_Msg_Req]
    Init_CAN1_NM_EPAS_Active_WU: value-spec=0
    Init_CAN1_NM_EPAS_CSB: value-spec=0
    Init_CAN1_NM_EPAS_ERROR_State: value-spec=0
    Init_CAN1_NM_EPAS_Node_ID: value-spec=0
    Init_CAN1_NM_EPAS_PNI: value-spec=0
    Init_CAN1_NM_EPAS_Rpt_Msg_Req: value-spec=0
    Init_CAN1_SG_XNMm_EPAS: value-spec=fields=[Init_CAN1_NM_EPAS_Active_WU, Init_CAN1_NM_EPAS_CSB, Init_CAN1_NM_EPAS_ERROR_State, Init_CAN1_NM_EPAS_Node_ID, Init_CAN1_NM_EPAS_PNI, Init_CAN1_NM_EPAS_Rpt_Msg_Req]
    Init_CAN1_NM_ESC_Active_WU: value-spec=0
    Init_CAN1_NM_ESC_CSB: value-spec=0
    Init_CAN1_NM_ESC_ERROR_State: value-spec=0
    Init_CAN1_NM_ESC_Node_ID: value-spec=0
    Init_CAN1_NM_ESC_PNI: value-spec=0
    Init_CAN1_NM_ESC_Rpt_Msg_Req: value-spec=0
    Init_CAN1_SG_XNMm_ESC: value-spec=fields=[Init_CAN1_NM_ESC_Active_WU, Init_CAN1_NM_ESC_CSB, Init_CAN1_NM_ESC_ERROR_State, Init_CAN1_NM_ESC_Node_ID, Init_CAN1_NM_ESC_PNI, Init_CAN1_NM_ESC_Rpt_Msg_Req]
    Init_CAN1_NM_FCM_Active_WU: value-spec=0
    Init_CAN1_NM_FCM_CSB: value-spec=0
    Init_CAN1_NM_FCM_ERROR_State: value-spec=0
    Init_CAN1_NM_FCM_Node_ID: value-spec=0
    Init_CAN1_NM_FCM_PNI: value-spec=0
    Init_CAN1_NM_FCM_Rpt_Msg_Req: value-spec=0
    Init_CAN1_SG_XNMm_FCM: value-spec=fields=[Init_CAN1_NM_FCM_Active_WU, Init_CAN1_NM_FCM_CSB, Init_CAN1_NM_FCM_ERROR_State, Init_CAN1_NM_FCM_Node_ID, Init_CAN1_NM_FCM_PNI, Init_CAN1_NM_FCM_Rpt_Msg_Req]
    Init_CAN1_NM_FUSION_Active_WU: value-spec=0
    Init_CAN1_NM_FUSION_CSB: value-spec=0
    Init_CAN1_NM_FUSION_ERROR_State: value-spec=0
    Init_CAN1_NM_FUSION_Node_ID: value-spec=0
    Init_CAN1_NM_FUSION_PNI: value-spec=0
    Init_CAN1_NM_FUSION_Rpt_Msg_Req: value-spec=0
    Init_CAN1_SG_XNMm_FUSION: value-spec=fields=[Init_CAN1_NM_FUSION_Active_WU, Init_CAN1_NM_FUSION_CSB, Init_CAN1_NM_FUSION_ERROR_State, Init_CAN1_NM_FUSION_Node_ID, Init_CAN1_NM_FUSION_PNI, Init_CAN1_NM_FUSION_Rpt_Msg_Req]
    Init_CAN1_NM_SRR_M_Active_WU: value-spec=0
    Init_CAN1_NM_SRR_M_CSB: value-spec=0
    Init_CAN1_NM_SRR_M_ERROR_State: value-spec=0
    Init_CAN1_NM_SRR_M_Node_ID: value-spec=0
    Init_CAN1_NM_SRR_M_PNI: value-spec=0
    Init_CAN1_NM_SRR_M_Rpt_Msg_Req: value-spec=0
    Init_CAN1_SG_XNMm_SRR_M: value-spec=fields=[Init_CAN1_NM_SRR_M_Active_WU, Init_CAN1_NM_SRR_M_CSB, Init_CAN1_NM_SRR_M_ERROR_State, Init_CAN1_NM_SRR_M_Node_ID, Init_CAN1_NM_SRR_M_PNI, Init_CAN1_NM_SRR_M_Rpt_Msg_Req]
    Init_CAN1_NM_eBST_Active_WU: value-spec=0
    Init_CAN1_NM_eBST_CSB: value-spec=0
    Init_CAN1_NM_eBST_ERROR_State: value-spec=0
    Init_CAN1_NM_eBST_Node_ID: value-spec=0
    Init_CAN1_NM_eBST_PNI: value-spec=0
    Init_CAN1_NM_eBST_Rpt_Msg_Req: value-spec=0
    Init_CAN1_SG_XNMm_eBST: value-spec=fields=[Init_CAN1_NM_eBST_Active_WU, Init_CAN1_NM_eBST_CSB, Init_CAN1_NM_eBST_ERROR_State, Init_CAN1_NM_eBST_Node_ID, Init_CAN1_NM_eBST_PNI, Init_CAN1_NM_eBST_Rpt_Msg_Req]
package /CAN1/ImplementationDataTypes
  31 x impl type, all with category=STRUCTURE:
    DT_CAN1_SG_ABM1
      12 x element, all with category=TYPE_REFERENCE, implementation-data-type=uint8:
        CAN1_AirBagFailCmd
        CAN1_Checksum_ABM1
        CAN1_CrashOutputSts
        CAN1_DriverSeatBeltCmd
        CAN1_LifeCount_ABM1
        CAN1_PABSwitchCmd
        CAN1_PsngrSeatBeltCmd
        CAN1_RCenterSeatBeltCmd
        CAN1_RDriverSeatBeltCmd
        CAN1_RPsngrSeatBeltCmd
        CAN1_TLHPsngrSeatBeltCmd
        CAN1_TRHPsngrSeatBeltCmd
    DT_CAN1_SG_EPAS1
      5 x element, all with category=TYPE_REFERENCE, implementation-data-type=uint8:
        CAN1_DriIntend
        CAN1_EPAS1_Checksum
        CAN1_EPAS1_LifeCount
        CAN1_EPS_AOI_Control
        CAN1_EPS_TOI_Fault
    DT_CAN1_SG_EPAS2
      7 x element, all with category=TYPE_REFERENCE:
        CAN1_SAS_Angle: implementation-data-type=uint16
        CAN1_SAS_CAL: implementation-data-type=uint8
        CAN1_SAS_CheckSum: implementation-data-type=uint8
        CAN1_SAS_MsgCount: implementation-data-type=uint8
        CAN1_SAS_Speed: implementation-data-type=uint8
        CAN1_SAS_Speed_Valid: implementation-data-type=uint8
        CAN1_SAS_V: implementation-data-type=uint8
    DT_CAN1_SG_EPB1
      13 x element, all with category=TYPE_REFERENCE, implementation-data-type=uint8:
        CAN1_DOA_Sta
        CAN1_EPB1_CS
        CAN1_EPB1_RC
        CAN1_EPBCarWashMode
        CAN1_EPBErrSta
        CAN1_EPBExtApplyAvail
        CAN1_EPBExtReleaseAvail
        CAN1_EPBMsg
        CAN1_EPBRLampSta
        CAN1_EPBSta
        CAN1_EPBStaL
        CAN1_EPBStaR
        CAN1_TakeOverReq
    DT_CAN1_SG_ESC1
      7 x element, all with category=TYPE_REFERENCE:
        CAN1_ESC1_CS: implementation-data-type=uint8
        CAN1_ESC1_RC: implementation-data-type=uint8
        CAN1_Fr_PTCS_Active: implementation-data-type=uint8
        CAN1_FrntAxlTrqReq_Drv: implementation-data-type=uint16
        CAN1_RearAxlTrqReq_Drv: implementation-data-type=uint16
        CAN1_Rr_PTCS_Active: implementation-data-type=uint8
        CAN1_VehSpeed: implementation-data-type=uint16
    DT_CAN1_SG_ESC2
      12 x element, all with category=TYPE_REFERENCE:
        CAN1_F_WhlSpeed_CRC_8: implementation-data-type=uint8
        CAN1_F_WhlSpeed_Count: implementation-data-type=uint8
        CAN1_LF_PulseCount: implementation-data-type=uint8
        CAN1_LF_PulseCount_V: implementation-data-type=uint8
        CAN1_LF_RawWhlSpeed: implementation-data-type=uint16
        CAN1_LF_RawWhlSpeed_V: implementation-data-type=uint8
        CAN1_LF_WhlRotDir: implementation-data-type=uint8
        CAN1_RF_PulseCount: implementation-data-type=uint8
        CAN1_RF_PulseCount_V: implementation-data-type=uint8
        CAN1_RF_RawWhlSpeed: implementation-data-type=uint16
        CAN1_RF_RawWhlSpeed_V: implementation-data-type=uint8
        CAN1_RF_WhlRotDir: implementation-data-type=uint8
    DT_CAN1_SG_ESC3
      12 x element, all with category=TYPE_REFERENCE:
        CAN1_LR_PulseCount: implementation-data-type=uint8
        CAN1_LR_PulseCount_V: implementation-data-type=uint8
        CAN1_LR_RawWhlSpeed: implementation-data-type=uint16
        CAN1_LR_RawWhlSpeed_V: implementation-data-type=uint8
        CAN1_LR_WhlRotDir: implementation-data-type=uint8
        CAN1_RR_PulseCount: implementation-data-type=uint8
        CAN1_RR_PulseCount_V: implementation-data-type=uint8
        CAN1_RR_RawWhlSpeed: implementation-data-type=uint16
        CAN1_RR_RawWhlSpeed_V: implementation-data-type=uint8
        CAN1_RR_WhlRotDir: implementation-data-type=uint8
        CAN1_R_WhlSpeed_CRC_8: implementation-data-type=uint8
        CAN1_R_WhlSpeed_Count: implementation-data-type=uint8
    DT_CAN1_SG_ESC4
      29 x element, all with category=TYPE_REFERENCE, implementation-data-type=uint8:
        CAN1_ABS_Active
        CAN1_ABS_Failed
        CAN1_ABS_WnlmpSta
        CAN1_AVH_Active
        CAN1_AVH_Failed
        CAN1_Amber_WnlmpSta
        CAN1_BTCS_Active
        CAN1_EBD_Active
        CAN1_EBD_Failed
        CAN1_ESC_Active
        CAN1_ESC_BeepReq
        CAN1_ESC_Failed
        CAN1_ESC_OFF_Status
        CAN1_ESC_Off_lmpSta
        CAN1_ESC_WnlmpSta
        CAN1_ESS_Active
        CAN1_GRADE
        CAN1_HBB_Active
        CAN1_HBB_Failed
        CAN1_HDD_Active
        CAN1_HDD_Failed
        CAN1_HSA_Active
        CAN1_HSA_Failed
        CAN1_PBA_Active
        CAN1_PBA_Failed
        CAN1_Red_WnlmpSta
        CAN1_SystemVoltage
        CAN1_TCS_Active
        CAN1_TCS_Failed
    DT_CAN1_SG_ESC5
      12 x element, all with category=TYPE_REFERENCE:
        CAN1_BrkSw_Sta: implementation-data-type=uint8
        CAN1_BrkSw_V: implementation-data-type=uint8
        CAN1_ESC5_CRC8: implementation-data-type=uint8
        CAN1_ESC5_RC: implementation-data-type=uint8
        CAN1_LatAccel: implementation-data-type=uint8
        CAN1_LatAccel_V: implementation-data-type=uint8
        CAN1_LongAccel: implementation-data-type=uint8
        CAN1_LongAccel_V: implementation-data-type=uint8
        CAN1_MCPressure: implementation-data-type=uint16
        CAN1_MCPressure_V: implementation-data-type=uint8
        CAN1_YawRate: implementation-data-type=uint16
        CAN1_YawRate_V: implementation-data-type=uint8
    DT_CAN1_SG_ESC6
      11 x element, all with category=TYPE_REFERENCE:
        CAN1_ACCAvail: implementation-data-type=uint8
        CAN1_AEBAvail: implementation-data-type=uint8
        CAN1_ActBrkLamp_Sta: implementation-data-type=uint8
        CAN1_BrkDiscTempSta: implementation-data-type=uint8
        CAN1_DecErrSta: implementation-data-type=uint8
        CAN1_ESC6_CS: implementation-data-type=uint8
        CAN1_ESC6_RC: implementation-data-type=uint8
        CAN1_ESC_ADAS_Sta: implementation-data-type=uint8
        CAN1_ESC_APS_Sta: implementation-data-type=uint8
        CAN1_ESC_Standstill: implementation-data-type=uint8
        CAN1_Meter_Ind_VehSpeed: implementation-data-type=uint16
    DT_CAN1_SG_ESC7
      9 x element, all with category=TYPE_REFERENCE:
        CAN1_BrkPedalPos: implementation-data-type=uint8
        CAN1_BrkPedalPos_Sta: implementation-data-type=uint8
        CAN1_ESC7_CS: implementation-data-type=uint8
        CAN1_ESC7_RC: implementation-data-type=uint8
        CAN1_Fr_RBC_Active: implementation-data-type=uint8
        CAN1_FrntAxlTrqReq_Brk: implementation-data-type=uint16
        CAN1_RDC_Active: implementation-data-type=uint8
        CAN1_RearAxlTrqReq_Brk: implementation-data-type=uint16
        CAN1_Rr_RBC_Active: implementation-data-type=uint8
    DT_CAN1_SG_FCM2
      12 x element, all with category=TYPE_REFERENCE:
        CAN1_ACC_ComfortBandLower: implementation-data-type=uint16
        CAN1_ACC_ComfortBandUpper: implementation-data-type=uint16
        CAN1_ACC_JerkLowerLimit: implementation-data-type=uint8
        CAN1_ACC_JerkUpperLimit: implementation-data-type=uint8
        CAN1_ACC_RequiredAccel: implementation-data-type=uint16
        CAN1_ACC_VehHoldReq: implementation-data-type=uint8
        CAN1_ADAS_AEBReq: implementation-data-type=uint8
        CAN1_ADAS_DBSReq: implementation-data-type=uint8
        CAN1_ADAS_FaultSta: implementation-data-type=uint8
        CAN1_AEB_VehHoldReq: implementation-data-type=uint8
        CAN1_FCM2_Checksum: implementation-data-type=uint8
        CAN1_FCM2_LifeCount: implementation-data-type=uint8
    DT_CAN1_SG_FCM3
      8 x element, all with category=TYPE_REFERENCE:
        CAN1_ACC_ObjDist: implementation-data-type=uint16
        CAN1_ACC_ObjRelSpd: implementation-data-type=uint16
        CAN1_ADAS_ForceIdle: implementation-data-type=uint8
        CAN1_ADAS_ShftPosnReq: implementation-data-type=uint8
        CAN1_ADAS_ShftPosnReq_A: implementation-data-type=uint8
        CAN1_ADAS_VehSpdLim: implementation-data-type=uint8
        CAN1_FCM3_Checksum: implementation-data-type=uint8
        CAN1_FCM3_LifeCount: implementation-data-type=uint8
    DT_CAN1_SG_FCM4
      19 x element, all with category=TYPE_REFERENCE, implementation-data-type=uint8:
        CAN1_ACCSetSpeed
        CAN1_ACCSetSpeed_Disp
        CAN1_ACC_ObjDstLvl
        CAN1_ACC_TakeoverReq
        CAN1_ADAS_ACC_Sta
        CAN1_ADAS_AEB_Sta
        CAN1_ADAS_CAM_SpdLim
        CAN1_ADAS_FCW_Sta
        CAN1_ADAS_FltWrnReq
        CAN1_ADAS_LDW_Sta
        CAN1_ADAS_SLIF_SpdLim
        CAN1_ADAS_WarningMsg
        CAN1_FCM4_Checksum
        CAN1_ForceLowBeam
        CAN1_HazardWarningReq
        CAN1_LeftTurnLightReq
        CAN1_RightTurnLightReq
        CAN1_Target_Type
        CAN1_TimeGapLevel
    DT_CAN1_SG_FD_APS1
      4 x element, all with category=TYPE_REFERENCE:
        CAN1_APS_Angle_Target: implementation-data-type=uint16
        CAN1_APS_Rq_EPAS_Ctrl: implementation-data-type=uint8
        CAN1_APS_Sta_System: implementation-data-type=uint8
        CAN1_APS_V_Rq_EPAS_Ctrl: implementation-data-type=uint8
    DT_CAN1_SG_FD_APS2
      41 x element, all with category=TYPE_REFERENCE:
        CAN1_APS_D_FLL: implementation-data-type=uint16
        CAN1_APS_D_FLR: implementation-data-type=uint16
        CAN1_APS_D_RLL: implementation-data-type=uint16
        CAN1_APS_D_RLR: implementation-data-type=uint16
        CAN1_APS_ExitCondition: implementation-data-type=uint8
        CAN1_APS_HW_Ver: implementation-data-type=uint8
        CAN1_APS_Progress_PCT: implementation-data-type=uint8
        CAN1_APS_RQ_Display: implementation-data-type=uint8
        CAN1_APS_SW_Ver: implementation-data-type=uint8
        CAN1_PAS_A_FCL: implementation-data-type=uint8
        CAN1_PAS_A_FCR: implementation-data-type=uint8
        CAN1_PAS_A_FML: implementation-data-type=uint8
        CAN1_PAS_A_FMR: implementation-data-type=uint8
        CAN1_PAS_A_RCL: implementation-data-type=uint8
        CAN1_PAS_A_RCR: implementation-data-type=uint8
        CAN1_PAS_A_RML: implementation-data-type=uint8
        CAN1_PAS_A_RMR: implementation-data-type=uint8
        CAN1_PAS_Chime: implementation-data-type=uint8
        CAN1_PAS_D_FCL: implementation-data-type=uint8
        CAN1_PAS_D_FCR: implementation-data-type=uint8
        CAN1_PAS_D_FML: implementation-data-type=uint8
        CAN1_PAS_D_FMR: implementation-data-type=uint8
        CAN1_PAS_D_RCL: implementation-data-type=uint8
        CAN1_PAS_D_RCR: implementation-data-type=uint8
        CAN1_PAS_D_RML: implementation-data-type=uint8
        CAN1_PAS_D_RMR: implementation-data-type=uint8
        CAN1_PAS_Mod_Operation: implementation-data-type=uint8
        CAN1_PAS_SNSR_Layout: implementation-data-type=uint8
        CAN1_PAS_Sta_F_Sys: implementation-data-type=uint8
        CAN1_USS_Sta_FCL: implementation-data-type=uint8
        CAN1_USS_Sta_FCR: implementation-data-type=uint8
        CAN1_USS_Sta_FLL: implementation-data-type=uint8
        CAN1_USS_Sta_FLR: implementation-data-type=uint8
        CAN1_USS_Sta_FML: implementation-data-type=uint8
        CAN1_USS_Sta_FMR: implementation-data-type=uint8
        CAN1_USS_Sta_RCL: implementation-data-type=uint8
        CAN1_USS_Sta_RCR: implementation-data-type=uint8
        CAN1_USS_Sta_RLL: implementation-data-type=uint8
        CAN1_USS_Sta_RLR: implementation-data-type=uint8
        CAN1_USS_Sta_RML: implementation-data-type=uint8
        CAN1_USS_Sta_RMR: implementation-data-type=uint8
    DT_CAN1_SG_FD_APS3
      9 x element, all with category=TYPE_REFERENCE, implementation-data-type=uint8:
        CAN1_APS3_LifeCount
        CAN1_APS3_checksum
        CAN1_APSOpenPTG
        CAN1_APS_DecReq
        CAN1_APS_DecReq_A
        CAN1_APS_Req
        CAN1_CAAS_Sta
        CAN1_SPTGDet
        CAN1_SPTG_Sta
    DT_CAN1_SG_FD_BCM1
      50 x element, all with category=TYPE_REFERENCE, implementation-data-type=uint8:
        CAN1_AllDoorSW
        CAN1_AntiTheftSeatFold
        CAN1_AntitheftSta
        CAN1_BCM_Buzzer_Req
        CAN1_BCM_DoorLock_Sta
        CAN1_BrakeLamp
        CAN1_CTDCtrl
        CAN1_CTDLockSW
        CAN1_CTDUnlockSW
        CAN1_CrashDetd
        CAN1_Dimmer
        CAN1_DimmerEN
        CAN1_DoorLockIND
        CAN1_DrDoorSW
        CAN1_Fr_ChargingDoorCtrl
        CAN1_Fr_FogLamp
        CAN1_Fr_Wiper_H
        CAN1_Fr_Wiper_L
        CAN1_H_Beam
        CAN1_HazardSW
        CAN1_HoodSW
        CAN1_HornCtrl
        CAN1_LBSD
        CAN1_LDRL
        CAN1_LTurnLP
        CAN1_L_APM_WdwEnable
        CAN1_L_Beam
        CAN1_LockSetting
        CAN1_MirrorCtrl
        CAN1_MirrorDefog
        CAN1_PosLamp
        CAN1_PsDoorSW
        CAN1_RBSD
        CAN1_RDRL
        CAN1_RLDoorSW
        CAN1_RRDoorSW
        CAN1_RTurnLP
        CAN1_ReverseLamp
        CAN1_RoomLampH
        CAN1_RoomLampL
        CAN1_Rr_ChargingDoorCtrl
        CAN1_Rr_Defog
        CAN1_Rr_FogLamp
        CAN1_Rr_Wiper
        CAN1_TailgateHDSW
        CAN1_TailgateRemote
        CAN1_Tailgate_SW
        CAN1_TrunkRel
        CAN1_WasherCtrl
        CAN1_WiperFixMode
    DT_CAN1_SG_FD_THCM1
      37 x element, all with category=TYPE_REFERENCE:
        CAN1_BatteryMode: implementation-data-type=uint8
        CAN1_CCU_ACLampSts: implementation-data-type=uint8
        CAN1_CCU_ACMaxLampSts: implementation-data-type=uint8
        CAN1_CCU_AutoLampSts: implementation-data-type=uint8
        CAN1_CCU_AutoMidLampSts: implementation-data-type=uint8
        CAN1_CCU_Dispaly_Request: implementation-data-type=uint8
        CAN1_CCU_EcoSts: implementation-data-type=uint8
        CAN1_CCU_FrtOnOffLampSts: implementation-data-type=uint8
        CAN1_CCU_HEATMaxLampSts: implementation-data-type=uint8
        CAN1_CCU_RrOnOffLampSts: implementation-data-type=uint8
        CAN1_CCU_SyncLampSts: implementation-data-type=uint8
        CAN1_CabinMode: implementation-data-type=uint8
        CAN1_EDriveMode: implementation-data-type=uint8
        CAN1_FD_AGS_Cmd: implementation-data-type=uint8
        CAN1_FD_RecyAuto_Cmd: implementation-data-type=uint8
        CAN1_Fr_Coolantflow: implementation-data-type=uint8
        CAN1_Fr_Coolanttemp: implementation-data-type=uint16
        CAN1_HPThermalRecoveryReq: implementation-data-type=uint8
        CAN1_Rr_Coolantflow: implementation-data-type=uint8
        CAN1_Rr_Coolanttemp: implementation-data-type=uint16
        CAN1_sigAirIntenZon1St: implementation-data-type=uint8
        CAN1_sigAirIntenZon3St: implementation-data-type=uint8
        CAN1_sigAmbAirT: implementation-data-type=uint8
        CAN1_sigCbnAirT: implementation-data-type=uint8
        CAN1_sigCbnPTCPwrAct: implementation-data-type=uint8
        CAN1_sigCbnSolarLeft: implementation-data-type=uint8
        CAN1_sigCbnSolarRight: implementation-data-type=uint8
        CAN1_sigClmtCmprPwrAct: implementation-data-type=uint8
        CAN1_sigClntTHvBattOut: implementation-data-type=uint8
        CAN1_sigDfrstSt: implementation-data-type=uint8
        CAN1_sigHvacSt: implementation-data-type=uint8
        CAN1_sigRecircSt: implementation-data-type=uint8
        CAN1_sigSetTempZon{1..3}St: implementation-data-type=uint8
        CAN1_sigWindDirZon1St: implementation-data-type=uint8
        CAN1_sigWindDirZon3St: implementation-data-type=uint8
    DT_CAN1_SG_FD_VCU1
      10 x element, all with category=TYPE_REFERENCE, implementation-data-type=uint8:
        CAN1_CC_Crl_Sta
        CAN1_HVPwrSta
        CAN1_LVPwrSta
        CAN1_MSA_Crl_Sta
        CAN1_P_Button_Sta
        CAN1_PrkReq
        CAN1_PrkReqValid
        CAN1_PwrSta
        CAN1_ShiftGearPosn
        CAN1_XWDMode
    DT_CAN1_SG_FD_VCU2
      9 x element, all with category=TYPE_REFERENCE:
        CAN1_ACC_CtrlAvail: implementation-data-type=uint8
        CAN1_AccPedal_Override: implementation-data-type=uint8
        CAN1_ActAPSPosn: implementation-data-type=uint8
        CAN1_CS_VCU2_CAN1: implementation-data-type=uint8
        CAN1_DriverTq: implementation-data-type=uint16
        CAN1_Fr_DriverTq: implementation-data-type=uint16
        CAN1_RC_VCU2_CAN1: implementation-data-type=uint8
        CAN1_Rr_DriverTq: implementation-data-type=uint16
        CAN1_VehActPwr: implementation-data-type=uint32
    DT_CAN1_SG_FD_VCU3
      21 x element, all with category=TYPE_REFERENCE:
        CAN1_CS_VCU3_CAN1: implementation-data-type=uint8
        CAN1_EquivAccPedalSWSta: implementation-data-type=uint8
        CAN1_Fr_EDUAvailBrkRgnTq: implementation-data-type=uint16
        CAN1_Fr_EDUAvailBrkRgnTqValid: implementation-data-type=uint8
        CAN1_Fr_EDURealARgnTq: implementation-data-type=uint16
        CAN1_Fr_EDURealDrvOrBRgnTq: implementation-data-type=uint16
        CAN1_Fr_EDUSpd: implementation-data-type=uint16
        CAN1_Fr_EDUSpdValid: implementation-data-type=uint8
        CAN1_Fr_RgnDecrSta: implementation-data-type=uint8
        CAN1_Fr_RgnPermSta: implementation-data-type=uint8
        CAN1_PTCS_PermSta: implementation-data-type=uint8
        CAN1_RC_VCU3_CAN1: implementation-data-type=uint8
        CAN1_RgnAbnorSta: implementation-data-type=uint8
        CAN1_Rr_EDUAvailBrkRgnTq: implementation-data-type=uint16
        CAN1_Rr_EDUAvailBrkRgnTqValid: implementation-data-type=uint8
        CAN1_Rr_EDURealARgnTq: implementation-data-type=uint16
        CAN1_Rr_EDURealDrvOrBRgnTq: implementation-data-type=uint16
        CAN1_Rr_EDUSpd: implementation-data-type=uint16
        CAN1_Rr_EDUSpdValid: implementation-data-type=uint8
        CAN1_Rr_RgnDecrSta: implementation-data-type=uint8
        CAN1_Rr_RgnPermSta: implementation-data-type=uint8
    DT_CAN1_SG_FD_VCU4
      5 x element, all with category=TYPE_REFERENCE, implementation-data-type=uint8:
        CAN1_Eng_AGSCloseSta
        CAN1_Eng_ActvDmpDisabSta
        CAN1_Eng_CoastDwSta
        CAN1_Eng_PwrLockSta
        CAN1_VehMalfunLevel
    DT_CAN1_SG_SRR1
      18 x element, all with category=TYPE_REFERENCE, implementation-data-type=uint8:
        CAN1_SRR1_Chksum
        CAN1_SRR1_LifeCount
        CAN1_SRR_BSD_Mute
        CAN1_SRR_BSD_SoundL
        CAN1_SRR_BSD_SoundR
        CAN1_SRR_BSD_Sta
        CAN1_SRR_BSD_WarnL
        CAN1_SRR_BSD_WarnR
        CAN1_SRR_FltWrnReq
        CAN1_SRR_ODA_Mute
        CAN1_SRR_ODA_SoundL
        CAN1_SRR_ODA_SoundR
        CAN1_SRR_ODA_Sta
        CAN1_SRR_ODA_WarnL
        CAN1_SRR_ODA_WarnR
        CAN1_SRR_RCTA_Sta
        CAN1_SRR_RCTA_WarnL
        CAN1_SRR_RCTA_WarnR
    DT_CAN1_SG_XNMm_ABM
      6 x element, all with category=TYPE_REFERENCE, implementation-data-type=uint8:
        CAN1_NM_ABM_Active_WU
        CAN1_NM_ABM_CSB
        CAN1_NM_ABM_ERROR_State
        CAN1_NM_ABM_Node_ID
        CAN1_NM_ABM_PNI
        CAN1_NM_ABM_Rpt_Msg_Req
    DT_CAN1_SG_XNMm_EPAS
      6 x element, all with category=TYPE_REFERENCE, implementation-data-type=uint8:
        CAN1_NM_EPAS_Active_WU
        CAN1_NM_EPAS_CSB
        CAN1_NM_EPAS_ERROR_State
        CAN1_NM_EPAS_Node_ID
        CAN1_NM_EPAS_PNI
        CAN1_NM_EPAS_Rpt_Msg_Req
    DT_CAN1_SG_XNMm_ESC
      6 x element, all with category=TYPE_REFERENCE, implementation-data-type=uint8:
        CAN1_NM_ESC_Active_WU
        CAN1_NM_ESC_CSB
        CAN1_NM_ESC_ERROR_State
        CAN1_NM_ESC_Node_ID
        CAN1_NM_ESC_PNI
        CAN1_NM_ESC_Rpt_Msg_Req
    DT_CAN1_SG_XNMm_FCM
      6 x element, all with category=TYPE_REFERENCE, implementation-data-type=uint8:
        CAN1_NM_FCM_Active_WU
        CAN1_NM_FCM_CSB
        CAN1_NM_FCM_ERROR_State
        CAN1_NM_FCM_Node_ID
        CAN1_NM_FCM_PNI
        CAN1_NM_FCM_Rpt_Msg_Req
    DT_CAN1_SG_XNMm_FUSION
      6 x element, all with category=TYPE_REFERENCE, implementation-data-type=uint8:
        CAN1_NM_FUSION_Active_WU
        CAN1_NM_FUSION_CSB
        CAN1_NM_FUSION_ERROR_State
        CAN1_NM_FUSION_Node_ID
        CAN1_NM_FUSION_PNI
        CAN1_NM_FUSION_Rpt_Msg_Req
    DT_CAN1_SG_XNMm_SRR_M
      6 x element, all with category=TYPE_REFERENCE, implementation-data-type=uint8:
        CAN1_NM_SRR_M_Active_WU
        CAN1_NM_SRR_M_CSB
        CAN1_NM_SRR_M_ERROR_State
        CAN1_NM_SRR_M_Node_ID
        CAN1_NM_SRR_M_PNI
        CAN1_NM_SRR_M_Rpt_Msg_Req
    DT_CAN1_SG_XNMm_eBST
      6 x element, all with category=TYPE_REFERENCE, implementation-data-type=uint8:
        CAN1_NM_eBST_Active_WU
        CAN1_NM_eBST_CSB
        CAN1_NM_eBST_ERROR_State
        CAN1_NM_eBST_Node_ID
        CAN1_NM_eBST_PNI
        CAN1_NM_eBST_Rpt_Msg_Req
